VERSION "DIPBNNNYNNNNNNNNNNNNNNNNNNNNNNNNNNNNNNNNNN/4>*%%/4/'%**4NNN///"

NS_ :

BS_:

BU_: Gateway_1 Gateway_0
VAL_TABLE_ SSS_FF38_BtnEvent 3 "Ignore" 2 "No Change/Held" 1 "Pressed" 0 "Released" ;
VAL_TABLE_ SSS_FF39_ControllerFaultStatus 2 "Critical Fault Active" 1 "Caution Fault Active" 0 "No Active Faults" ;
VAL_TABLE_ SSS_FF38_CmdType 1 "Position Cmd" 0 "Button Cmd" ;
VAL_TABLE_ VT_TTA_InstanceSetupMode 3 "Ignore" 2 "Reserved" 1 "MagnetInstancingActive" 0 "PowerOnInstancingActive" ;
VAL_TABLE_ Value_Table_u2_Enable_Disable 3 "Ignore" 2 "Reserved" 1 "Enable" 0 "Disable" ;
VAL_TABLE_ SSS_Act_FaultStatus 3 "Ignore" 2 "Warning" 1 "Caution" 0 "Inactive" ;
VAL_TABLE_ SSS_Act_PosFbk 2047 "No Data" 2046 "Error" 2043 "Not Homed Yet" ;
VAL_TABLE_ SSS_Act_SpeedSetting 4095 "No Change" 4094 "Error" ;
VAL_TABLE_ SSS_Act_FunctionInst 15 "No Data" 14 "Error" 13 "All" ;
VAL_TABLE_ SSS_Act_SourceInst 15 "Not Available" 14 "Error" ;
VAL_TABLE_ SSS_Act_PosCmd 2047 "No Cmd" 2046 "Error" 2043 "Home Cmd" ;
VAL_TABLE_ SSS_Act_MotionCmd 3 "No Cmd" 2 "Move down / Retract / Stbd" 1 "Move up / Extend / Port" 0 "Stop" ;
VAL_TABLE_ SSS_Act_FunctionType 15 "Ignore" 14 "Error" 13 "All" 7 "Smart Act 3" 6 "Smart Act 2" 5 "Smart Act 1" 4 "Surf Actuator" 3 "Trim Tab" 2 "Shallow Water Anchor" 1 "Jack Plate" 0 "Engine Trim" ;
VAL_TABLE_ SSS_Act_SourceType 2 "Trim Dial" 1 "DSC" 0 "MFD" ;
VAL_TABLE_ VT_STA_TabState 5 "Error" 4 "Cycling" 3 "Active" 2 "Ready" 1 "Initting" 0 "Not ready" ;
VAL_TABLE_ CCPCommands 255 "ECU_RESPONCE" 23 "EXCHANGE_ID" 19 "UNLOCK" 18 "GET_SEED" 4 "UPLOAD" 3 "DOWNLOAD" 2 "SET_MTA" 1 "CONNECT" ;
VAL_TABLE_ HelmHardstopType 3 "Ignore" 2 "Electronic and Physical" 1 "Physical" 0 "Electronic" ;
VAL_TABLE_ BatteryStatus 5 "Bad Connection" 4 "High" 3 "Low" 2 "Weak" 1 "Charger Off" 0 "Normal" ;
VAL_TABLE_ Merc_Authentication_Status 1 "Authenticated" 0 "Not Authenticated (default)" ;
VAL_TABLE_ Merc_Trolling_Mode 3 "Not Available (default)" 2 "Error" 1 "Mode on" 0 "Mode off" ;
VAL_TABLE_ Merc_Throttle_Only_Mode 3 "Not Available (default)" 2 "Error" 1 "Mode on" 0 "Mode off" ;
VAL_TABLE_ Merc_Single_Lever_Mode 3 "Not Available (default)" 2 "Error" 1 "Mode on" 0 "Mode off" ;
VAL_TABLE_ AutopiliotMode 4 "Override" 3 "Route" 2 "Track" 1 "Heading" 0 "Standby" ;
VAL_TABLE_ CommandType 1 "Steering" 0 "Rudder" ;
VAL_TABLE_ PCM_eHardstop 2 "Stbd" 1 "Port" 0 "None" ;
VAL_TABLE_ ASK_AckReq 1 "Ack Requested" 0 "No Ack Requested" ;
VAL_TABLE_ JoystickMode 3 "Position and Heading Hold" 2 "Heading Hold" 1 "Position Hold" 0 "Manual" ;
VAL_TABLE_ MCU_Reset_Source 4 "CCP Reset" 3 "Network Reset" 2 "Local Reset" 1 "Stack Overflow" 0 "None" ;
VAL_TABLE_ CPU_Reset_Source 1024 "Software Reset" 512 "Core Lockup" 256 "JTAG Reset" 130 "Power-on" 65 "VLLS with reset Assertion" 64 "External" 32 "Watchdog" 4 "Loss-of-Clock" 2 "Low-voltage Detect" 1 "Low Leakage Wakeup" ;
VAL_TABLE_ ASK_ControlZone 6 "CCW" 5 "CW" 4 "Port" 3 "Reverse" 2 "Starboard" 1 "Forward" 0 "Neutral" ;
VAL_TABLE_ ASK_Mode 3 "Position & Heading" 2 "Heading" 1 "Position" 0 "Off" ;
VAL_TABLE_ VariationSource 63 "Data Not Available" 8 "WMM 2020" 7 "WMM 2015" 6 "WMM 2010" 5 "WMM 2005" 4 "WMM 2000" 3 "Automatic - Calculation" 2 "Automatic - Table" 1 "Automatic - Chart" 0 "Manual Entry" ;
VAL_TABLE_ TFX_OffOn 1 "On" 0 "Off" ;
VAL_TABLE_ TFX_ControlState_EST 0 "Y: Startup, S: Unknown" 15 "Not Available" 14 "Error" 8 "EOL Test" 7 "Power down" 6 "Fault" 5 "Joystick Active" 4 "CH Active" 3 "Y: Inactive, S: Calibration" 2 "Y: SmartSelect, S: Certification" 1 "Y: LPS Cal, S: Startup" ;
VAL_TABLE_ RPMSource 4 "i7700 Tach" 3 "Electronic Engines" 2 "NMEA2000" 1 "PCM Tach" 0 "Unavailable" ;
VAL_TABLE_ TFX_MasterJoystick 3 "Not Available" 2 "Not Available" 1 "Master Joystick" 0 "Non-Master Joystick" ;
VAL_TABLE_ JS_CL_State 2 "Latched" 1 "Enabled" 0 "Disabled" ;
VAL_TABLE_ Default_Ignore_uint4 15 "Ignore" 14 "Default" ;
VAL_TABLE_ TFX_TransferRqstESTGateway 3 "Not Available" 2 "Error" 1 "Transfer to Gateway" 0 "No Request" ;
VAL_TABLE_ Error_NA_int8 127 "Not Available" 126 "Error" ;
VAL_TABLE_ Error_NA_int16 32767 "Not Available" 32766 "Error" ;
VAL_TABLE_ Error_NA_uint4 15 "Not Available" 14 "Error" ;
VAL_TABLE_ Error_NA_uint16 65535 "Not Available" 65534 "Error" ;
VAL_TABLE_ Error_NA_uint8 255 "Not Available" 254 "Error" ;
VAL_TABLE_ TFX_SourceType 1 "Joystick" 0 "Main PCM" ;
VAL_TABLE_ MainSecond 1 "Second" 0 "Main" ;
VAL_TABLE_ EngagedDisengaged 1 "Disengaged" 0 "Engaged" ;
VAL_TABLE_ TFX_ESMFaults 5 "Throttle Up Fault" 4 "Reverse Fault" 3 "Forward Fault" 2 "Neutral Fault" 1 "Danger Fault" 0 "No Fault" ;
VAL_TABLE_ TFX_StartStop 3 "Reserved" 2 "Engine Stop" 1 "Engine Start" 0 "No Change" ;
VAL_TABLE_ TFX_TrimCommand 2 "Trim Down Active" 1 "Trim Up Active" 0 "No Trim Change" ;
VAL_TABLE_ InactiveActive 1 "Active" 0 "Inactive" ;
VAL_TABLE_ Shift_Throttle_type 7 "ETEC-G2" 6 "None (EPS only)" 5 "i7700" 4 "Suzuki" 3 "Yamaha" 2 "Yanmar" 1 "ICON" 0 "i6800" ;
VAL_TABLE_ E_Default_F_Ignore 15 "Ignore" 14 "Default" ;
VAL_TABLE_ BRP_Fault_Code 5 "Throttle Up Fault" 4 "Reverse Fault" 3 "Forward Fault" 2 "Neutral Fault" 1 "Non Recoverable Fault" 0 "No Fault" ;
VAL_TABLE_ TFX_CtrakSourceInstance 15 "Not Available" 14 "Error" ;
VAL_TABLE_ TFX_3Ignore 3 "Ignore" ;
VAL_TABLE_ TFX_3All 3 "All" ;
VAL_TABLE_ TFX_013_OffOnIgnore 1 "On" 0 "Off" 3 "Ignore" ;
VAL_TABLE_ TFX_ErrorFE_NotAvailableFF 255 "Not Available" 254 "Error" ;
VAL_TABLE_ TFX_CANtrakAdjustScreen 3 "Ignore" 1 "Enabled" 0 "Disabled" ;
VAL_TABLE_ TFX_OptimusSystemType 3 "Ignore" 1 "Optimus 360" 0 "Optimus" ;
VAL_TABLE_ TFX_DockingMode 3 "Ignore" 1 "Description for the value '0x1'" 0 "Description for the value '0x0'" ;
VAL_TABLE_ TFX_SyncMode 15 "Ignore" 1 "PTS" 0 "CS" ;
VAL_TABLE_ TFX_OffOnIgnore 3 "Ignore" 1 "On" 0 "Off" ;
VAL_TABLE_ TFX_NeutralGearIgnore 3 "Ignore" 1 "Gear" 0 "Neutral" ;
VAL_TABLE_ TFX_F_Ignore 15 "Ignore" ;
VAL_TABLE_ TFX_LampStatus 1 "On" 0 "Off" ;
VAL_TABLE_ TFX_LimpHomeMode 3 "Reserved Mode" 2 "Mode 2" 1 "Mode 1" 0 "Off" ;
VAL_TABLE_ TFX_KeyOffCylPos 1 "Straighten up if Angled to COG" 0 "Keep Last Position" ;
VAL_TABLE_ TFX_SpeedSource 15 "Ignore" 3 "Throttle Command" 2 "PCM Tachometer" 1 "N2K Engine RPM" 0 "Speed Over Water" ;
VAL_TABLE_ TFX_FFFFIgnore 65535 "Ignore" ;
VAL_TABLE_ TFX_7FIgnore 127 "Ignore" ;
VAL_TABLE_ TFX_FFIgnore 255 "Ignore" ;
VAL_TABLE_ TFX_CANtrak_UserCmd 15 "Ignore" 14 "Error" 3 "Exit Limp Home Mode" 2 "Enter Limp Home Mode" 1 "Resume" 0 "No Command" ;
VAL_TABLE_ TFX_HelmCommand 2 "Reset" 1 "Powerdown" 0 "No Command" ;
VAL_TABLE_ TFX_Helm_Brake_State 8 "Disabled" 7 "Off" 6 "Reapply Brake" 5 "Reverse" 4 "Reduce" 3 "Hold" 2 "Brake" 1 "Steering" 0 "Startup" ;
VAL_TABLE_ TFX_Helm_State 3 "Fault" 2 "Reverse" 1 "Hardover" 0 "Steering" ;
VAL_TABLE_ TFX_TeleflexHeading 1850 "Teleflex" ;
VAL_TABLE_ TFX_TrueFalse 1 "True" 0 "False" ;
VAL_TABLE_ TFX_JoystickInNeutral 3 "Not Available" 2 "Error" 1 "No" 0 "Yes" ;
VAL_TABLE_ TFX_SourceControlType 15 "Not Available" 14 "Error" 1 "Joystick" 0 "Control Head" ;
VAL_TABLE_ TFX_ControlState_Actuator 15 "Not Available" 14 "Error" 5 "Freeze" 4 "Active" 3 "Calibration" 2 "Power Down" 1 "Inactive" ;
VAL_TABLE_ TFX_PrtStbd 2 "Error" 3 "Not Available" 1 "Starboard" 0 "Port" ;
VAL_TABLE_ TFX_NoYes 1 "Yes" 0 "No" ;
VAL_TABLE_ TFX_SidePerformance 3 "Not Available" 2 "Shut Down" 1 "Limited" 0 "Full" ;
VAL_TABLE_ TFX_ControlState_PCM 15 "Not Available" 14 "Error" 8 "Auto-Pilot" 7 "Steering" 6 "Docking" 5 "Freeze" 4 "Purge" 3 "Calibration" 2 "Power Down" 1 "Inactive" ;
VAL_TABLE_ TFX_Fault 1 "Active" 0 "Inactive" ;
VAL_TABLE_ TFX_ActuatorType 1 "Throttle" 0 "Shift" ;
VAL_TABLE_ TFX_GearValue 15 "Not Available" 14 "Error" 2 "Reverse" 1 "Neutral" 0 "Forward" ;

BO_ 3221225472 VECTOR__INDEPENDENT_SIG_MSG: 0 Vector__XXX
 SG_ OilPressure : 0|16@1+ (100,0) [0|0] "Pa" Vector__XXX
 SG_ FaultCode : 0|8@1+ (1,0) [0|0] "" Vector__XXX
 SG_ PeerEMMInstance : 0|8@1+ (1,0) [0|0] "" Vector__XXX
 SG_ SourceESMInstance : 0|3@1+ (1,0) [0|0] "" Vector__XXX
 SG_ TotalNumberOfFramestoTransmitRTS : 0|8@1+ (1,0) [0|255] "" Vector__XXX
 SG_ TotalMessageSizeRTS : 0|16@1+ (1,0) [0|1785] "" Vector__XXX
 SG_ NumberofFramesAllowableforSend : 0|8@1+ (1,0) [0|255] "" Vector__XXX
 SG_ NumberofNextTransmittedFrame : 0|8@1- (1,0) [0|255] "" Vector__XXX
 SG_ TotalMessageSizeModeEOM : 0|16@1+ (1,0) [0|1785] "" Vector__XXX
 SG_ TotalNumberOfFramesReceived : 0|8@1- (1,0) [0|255] "" Vector__XXX
 SG_ TotalMessageSizeModeBAM : 0|16@1+ (1,0) [0|1785] "" Vector__XXX
 SG_ TotalNumberFramesTransmitBAM : 0|8@1- (1,0) [0|255] "" Vector__XXX
 SG_ TFX_ST_MarineIndustryID : 0|3@1+ (1,0) [0|0] "" Vector__XXX
 SG_ SID : 0|8@1+ (1,0) [0|250] "" Vector__XXX
 SG_ TFX_Shift_SyncActive : 0|1@1- (1,0) [0|0] "" Vector__XXX
 SG_ TFX_Shift_Group : 0|3@1+ (1,0) [0|7] "" Vector__XXX
 SG_ TFX_SCM_DockingActive : 0|1@1+ (1,0) [0|0] "" Vector__XXX
 SG_ TFX_SCM_DockingActive : 0|1@1+ (1,0) [0|0] "" Vector__XXX
 SG_ IndustryGroup : 0|3@1+ (1,0) [0|0] "" Vector__XXX
 SG_ TFX_Shift_Throttle : 0|10@1+ (0.1,0) [0|0] "%" Vector__XXX
 SG_ TFX_Shift_TrollBucket : 0|8@1- (1,0) [0|0] "" Vector__XXX
 SG_ TFX_Shift_EngineRpm : 0|14@1- (1,0) [0|0] "" Vector__XXX
 SG_ TFX_Shift_Gear : 0|2@1+ (1,0) [0|0] "" Vector__XXX
 SG_ TFX_Shift_TrollValveEngaged : 0|1@1+ (1,0) [0|0] "" Vector__XXX
 SG_ TFX_Shift_CriticalFailActive : 0|1@1+ (1,0) [0|0] "" Vector__XXX
 SG_ TFX_Shift_WarningActive : 0|1@1- (1,0) [0|0] "" Vector__XXX
 SG_ TFX_Shift_SyncActive : 0|1@1- (1,0) [0|0] "" Vector__XXX
 SG_ TFX_Shift_Group : 0|5@1+ (1,0) [0|0] "" Vector__XXX
 SG_ TFX_Shift_EngineRpm : 0|14@1- (1,0) [0|0] "" Vector__XXX
 SG_ TFX_Shift_TrollValveEngaged : 0|1@1+ (1,0) [0|0] "" Vector__XXX
 SG_ TFX_Shift_CriticalFailActive : 0|1@1+ (1,0) [0|0] "" Vector__XXX
 SG_ TFX_Shift_WarningActive : 0|1@1- (1,0) [0|0] "" Vector__XXX
 SG_ TFX_Shift_Group : 0|5@1+ (1,0) [0|0] "" Vector__XXX
 SG_ TFX_Header : 0|16@1+ (1,0) [0|0] "" Vector__XXX
 SG_ TFX_Shift_Gear : 0|2@1+ (1,0) [0|0] "" Vector__XXX
 SG_ TFX_Shift_TrollValveEngaged : 0|1@1+ (1,0) [0|0] "" Vector__XXX
 SG_ TFX_Shift_CriticalFailActive : 0|1@1+ (1,0) [0|0] "" Vector__XXX
 SG_ TFX_Shift_SyncActive : 0|1@1- (1,0) [0|0] "" Vector__XXX
 SG_ TFX_Shift_Instance : 0|3@1+ (1,0) [0|0] "" Vector__XXX
 SG_ TFX_Shift_TrollBucket : 0|8@1- (1,0) [0|0] "" Vector__XXX
 SG_ TFX_Shift_EngineRpm : 0|14@1- (1,0) [0|0] "" Vector__XXX
 SG_ TFX_Shift_Gear : 0|2@1+ (1,0) [0|0] "" Vector__XXX
 SG_ TFX_Shift_WarningActive : 0|1@1- (1,0) [0|0] "" Vector__XXX
 SG_ TFX_Shift_SyncActive : 0|1@1- (1,0) [0|0] "" Vector__XXX
 SG_ TFX_Shift_Throttle : 0|10@1+ (0.1,0) [0|0] "%" Vector__XXX
 SG_ TFX_Shift_Instance : 0|4@1+ (1,0) [0|15] "" Vector__XXX
 SG_ TFX_Shift_Group : 0|3@1+ (1,0) [0|7] "" Vector__XXX
 SG_ TFX_Header : 0|11@1+ (1,0) [0|2047] "" Vector__XXX
 SG_ TFX_Shift_WarningActive : 0|1@1- (1,0) [0|0] "" Vector__XXX
 SG_ TFX_Shift_TrollValveEngaged : 0|1@1+ (1,0) [0|0] "" Vector__XXX
 SG_ TFX_Shift_TrollBucket : 0|8@1- (1,0) [0|0] "" Vector__XXX
 SG_ TFX_Shift_Throttle : 0|10@1+ (0.1,0) [0|0] "%" Vector__XXX
 SG_ TFX_Shift_SyncActive : 0|1@1- (1,0) [0|0] "" Vector__XXX
 SG_ TFX_Shift_Instance : 0|3@1+ (1,0) [0|0] "" Vector__XXX
 SG_ TFX_Shift_Group : 0|5@1+ (1,0) [0|0] "" Vector__XXX
 SG_ TFX_Shift_Gear : 0|2@1+ (1,0) [0|0] "" Vector__XXX
 SG_ TFX_Shift_EngineRpm : 0|14@1- (1,0) [0|0] "" Vector__XXX
 SG_ TFX_Shift_CriticalFailActive : 0|1@1+ (1,0) [0|0] "" Vector__XXX
 SG_ TFX_Header : 0|16@1+ (1,0) [0|0] "" Vector__XXX
 SG_ TFX_Shift_WarningActive : 0|1@1- (1,0) [0|0] "" Vector__XXX
 SG_ TFX_Shift_TrollValveEngaged : 0|1@1+ (1,0) [0|0] "" Vector__XXX
 SG_ TFX_Shift_TrollBucket : 0|8@1- (1,0) [0|0] "" Vector__XXX
 SG_ TFX_Shift_Throttle : 0|10@1+ (0.1,0) [0|0] "%" Vector__XXX
 SG_ TFX_Shift_SyncActive : 0|1@1- (1,0) [0|0] "" Vector__XXX
 SG_ TFX_Shift_Instance : 0|3@1+ (1,0) [0|0] "" Vector__XXX
 SG_ TFX_Shift_Group : 0|5@1+ (1,0) [0|0] "" Vector__XXX
 SG_ TFX_Shift_Gear : 0|2@1+ (1,0) [0|0] "" Vector__XXX
 SG_ TFX_Shift_EngineRpm : 0|14@1- (1,0) [0|0] "" Vector__XXX
 SG_ TFX_Shift_CriticalFailActive : 0|1@1+ (1,0) [0|0] "" Vector__XXX
 SG_ TFX_Header : 0|16@1+ (1,0) [0|0] "" Vector__XXX
 SG_ TFX_Shift_WarningActive : 0|1@1- (1,0) [0|0] "" Vector__XXX
 SG_ TFX_Shift_TrollValveEngaged : 0|1@1+ (1,0) [0|0] "" Vector__XXX
 SG_ TFX_Shift_TrollBucket : 0|8@1- (1,0) [0|0] "" Vector__XXX
 SG_ TFX_Shift_Throttle : 0|10@1+ (0.1,0) [0|0] "%" Vector__XXX
 SG_ TFX_Shift_SyncActive : 0|1@1- (1,0) [0|0] "" Vector__XXX
 SG_ TFX_Shift_Instance : 0|3@1+ (1,0) [0|0] "" Vector__XXX
 SG_ TFX_Shift_Group : 0|5@1+ (1,0) [0|0] "" Vector__XXX
 SG_ TFX_Shift_Gear : 0|2@1+ (1,0) [0|0] "" Vector__XXX
 SG_ TFX_Shift_EngineRpm : 0|14@1- (1,0) [0|0] "" Vector__XXX
 SG_ TFX_Shift_CriticalFailActive : 0|1@1+ (1,0) [0|0] "" Vector__XXX
 SG_ Override : 0|8@1+ (1,0) [0|0] "" Vector__XXX
 SG_ TFX_PCM_PortSetpointDelta : 0|16@1- (0.01,0) [0|0] "°" Vector__XXX
 SG_ TFX_PCM_PortPTerm : 0|16@1- (0.01,0) [0|0] "" Vector__XXX
 SG_ TFX_PCM_PortPositionError : 0|16@1- (0.01,0) [0|0] "°" Vector__XXX
 SG_ TFX_PCM_PortFfTerm : 0|16@1- (0.1,0) [0|0] "" Vector__XXX
 SG_ TFX_SourceInstance : 0|4@1+ (1,0) [0|0] "" Vector__XXX
 SG_ TFX_IndustryGroup : 0|3@1+ (1,0) [0|0] "" Vector__XXX
 SG_ TFX_Header : 0|11@1+ (1,0) [0|0] "" Vector__XXX
 SG_ TFX_IndustryGroup : 0|3@1+ (1,0) [0|0] "" Vector__XXX
 SG_ TFX_Header : 0|11@1+ (1,0) [0|0] "" Vector__XXX
 SG_ TFX_Helm_Fault_SingleSensor : 0|1@1+ (1,0) [0|0] "" Vector__XXX
 SG_ TFX_Helm_Fault_SensorMismatch : 0|1@1+ (1,0) [0|0] "" Vector__XXX
 SG_ TFX_Helm_Fault_PcmHeartbeat : 0|1@1+ (1,0) [0|0] "" Vector__XXX
 SG_ TFX_Helm_Fault_FtCanWiring : 0|1@1+ (1,0) [0|0] "" Vector__XXX
 SG_ TFX_Helm_Fault_Brake_OverCurrent : 0|1@1+ (1,0) [0|0] "" Vector__XXX
 SG_ TFX_Helm_Fault_Brake_OpenCircuit : 0|1@1+ (1,0) [0|0] "" Vector__XXX
 SG_ TFX_Helm_Fault_BothSensors : 0|1@1+ (1,0) [0|0] "" Vector__XXX
 SG_ TFX_VC_JoystickAngle : 0|16@1- (0.01,0) [-180|180] "deg" Vector__XXX
 SG_ TFX_VC_JoystickTAxisPos : 0|16@1- (0.01,0) [-100|100] "%" Vector__XXX
 SG_ TFX_VC_JoystickYAxisPos : 0|16@1- (0.01,0) [-100|100] "%" Vector__XXX
 SG_ TFX_VC_JoystickXAxisPos : 0|16@1- (0.01,0) [-100|100] "%" Vector__XXX
 SG_ TFX_VC_Thrust_Stbd : 0|16@1+ (0.01,0) [0|100] "%" Vector__XXX
 SG_ TFX_VC_Thrust_Port : 0|16@1+ (0.01,0) [0|100] "%" Vector__XXX
 SG_ TFX_VC_State : 0|8@1+ (1,0) [0|0] "" Vector__XXX
 SG_ TFX_VC_ControlState : 0|8@1+ (1,0) [0|0] "" Vector__XXX
 SG_ TFX_JoystickHrtBtLoss_1 : 0|1@1+ (1,0) [0|0] "" Vector__XXX
 SG_ TFX_JoystickHrtBtLoss_0 : 0|1@1+ (1,0) [0|0] "" Vector__XXX
 SG_ TFX_HelmSensorFault : 0|1@1+ (1,0) [0|0] "" Vector__XXX
 SG_ TFX_HelmPCM_HrtBtLoss : 0|1@1+ (1,0) [0|0] "" Vector__XXX
 SG_ TFX_HelmHrtBtLoss_1 : 0|1@1+ (1,0) [0|0] "" Vector__XXX
 SG_ TFX_HelmHrtBtLoss_0 : 0|1@1+ (1,0) [0|0] "" Vector__XXX
 SG_ TFX_HelmFTCANwiringProblem : 0|1@1+ (1,0) [0|0] "" Vector__XXX
 SG_ TFX_HelmBrakeFault : 0|1@1+ (1,0) [0|0] "" Vector__XXX
 SG_ TFX_StbdTempSensorFault : 0|1@1+ (1,0) [0|0] "" Vector__XXX
 SG_ TFX_StbdOverTempFault : 0|1@1+ (1,0) [0|0] "" Vector__XXX
 SG_ TFX_StbdMotorFault : 0|1@1+ (1,0) [0|0] "" Vector__XXX
 SG_ TFX_StbdElectronicFault : 0|1@1+ (1,0) [0|0] "" Vector__XXX
 SG_ TFX_StbdCylWrongDirection : 0|1@1+ (1,0) [0|0] "" Vector__XXX
 SG_ TFX_StbdCylUnintendedMove : 0|1@1+ (1,0) [0|0] "" Vector__XXX
 SG_ TFX_StbdCylSensorNotCalibrated : 0|1@1+ (1,0) [0|0] "" Vector__XXX
 SG_ TFX_StbdCylSensorFault : 0|1@1+ (1,0) [0|0] "" Vector__XXX
 SG_ TFX_StbdCylDidNotMove : 0|1@1+ (1,0) [0|0] "" Vector__XXX
 SG_ TFX_StbdBatVoltageFault : 0|1@1+ (1,0) [0|0] "" Vector__XXX
 SG_ TFX_PortCylWrongDirection : 0|1@1+ (1,0) [0|0] "" Vector__XXX
 SG_ TFX_PortCylSensorNotCalibrated : 0|1@1+ (1,0) [0|0] "" Vector__XXX
 SG_ TFX_PortCylSensorFault : 0|1@1+ (1,0) [0|0] "" Vector__XXX
 SG_ TFX_StbdSideVoltageSource : 0|1@1+ (1,0) [0|0] "" Vector__XXX
 SG_ TFX_StbdSidePerformance : 0|2@1+ (1,0) [0|0] "" Vector__XXX
 SG_ TFX_PortSideVoltageSource : 0|1@1+ (1,0) [0|0] "" Vector__XXX
 SG_ TFX_PortSidePerformance : 0|2@1+ (1,0) [0|0] "" Vector__XXX
 SG_ TFX_PortTempSensorFault : 0|1@1+ (1,0) [0|0] "" Vector__XXX
 SG_ TFX_PortOverTempFault : 0|1@1+ (1,0) [0|0] "" Vector__XXX
 SG_ TFX_PortMotorFault : 0|1@1+ (1,0) [0|0] "" Vector__XXX
 SG_ TFX_PortElectronicFault : 0|1@1+ (1,0) [0|0] "" Vector__XXX
 SG_ TFX_PortCylUnintendedMove : 0|1@1+ (1,0) [0|0] "" Vector__XXX
 SG_ TFX_PortCylDidNotMove : 0|1@1+ (1,0) [0|0] "" Vector__XXX
 SG_ TFX_PortBatVoltageFault : 0|1@1+ (1,0) [0|0] "" Vector__XXX
 SG_ TFX_StbdSidePerformance : 0|1@1+ (1,0) [0|0] "" Vector__XXX
 SG_ TFX_ThrActHrtBtLoss_2 : 0|1@1+ (1,0) [0|0] "" Vector__XXX
 SG_ TFX_ThrActHrtBtLoss_1 : 0|1@1+ (1,0) [0|0] "" Vector__XXX
 SG_ TFX_ThrActHrtBtLoss_0 : 0|1@1+ (1,0) [0|0] "" Vector__XXX
 SG_ TFX_ShftActHrtBtLoss_2 : 0|1@1+ (1,0) [0|0] "" Vector__XXX
 SG_ TFX_ShftActHrtBtLoss_1 : 0|1@1+ (1,0) [0|0] "" Vector__XXX
 SG_ TFX_ShftActHrtBtLoss_0 : 0|1@1+ (1,0) [0|0] "" Vector__XXX
 SG_ TFX_PCM_HrtBtLoss_1 : 0|1@1+ (1,0) [0|0] "" Vector__XXX
 SG_ TFX_PCM_HrtBtLoss_0 : 0|1@1+ (1,0) [0|0] "" Vector__XXX
 SG_ TFX_JoystickYaxisPotFault : 0|1@1+ (1,0) [0|0] "" Vector__XXX
 SG_ TFX_JoystickXaxisPotFault : 0|1@1+ (1,0) [0|0] "" Vector__XXX
 SG_ TFX_JoystickThetaAxisPotFault : 0|1@1+ (1,0) [0|0] "" Vector__XXX
 SG_ TFX_ThrActHrtBtLoss_3 : 0|1@1+ (1,0) [0|0] "" Vector__XXX
 SG_ TFX_ThrActHrtBtLoss_2 : 0|1@1+ (1,0) [0|0] "" Vector__XXX
 SG_ TFX_ThrActHrtBtLoss_1 : 0|1@1+ (1,0) [0|0] "" Vector__XXX
 SG_ TFX_ThrActHrtBtLoss_0 : 0|1@1+ (1,0) [0|0] "" Vector__XXX
 SG_ TFX_StbdLeverFault : 0|1@1+ (1,0) [0|0] "" Vector__XXX
 SG_ TFX_ShftActHrtBtLoss_3 : 0|1@1+ (1,0) [0|0] "" Vector__XXX
 SG_ TFX_ShftActHrtBtLoss_2 : 0|1@1+ (1,0) [0|0] "" Vector__XXX
 SG_ TFX_ShftActHrtBtLoss_1 : 0|1@1+ (1,0) [0|0] "" Vector__XXX
 SG_ TFX_ShftActHrtBtLoss_0 : 0|1@1+ (1,0) [0|0] "" Vector__XXX
 SG_ TFX_PortLeverFault : 0|1@1+ (1,0) [0|0] "" Vector__XXX
 SG_ TFX_WarningFault : 0|1@1+ (1,0) [0|0] "" Vector__XXX
 SG_ TFX_ThrUpMotionFault : 0|1@1+ (1,0) [0|0] "" Vector__XXX
 SG_ TFX_ThrDwnMotionFault : 0|1@1+ (1,0) [0|0] "" Vector__XXX
 SG_ TFX_ShiftRevMotionFault : 0|1@1+ (1,0) [0|0] "" Vector__XXX
 SG_ TFX_ShiftNeutMotionFault : 0|1@1+ (1,0) [0|0] "" Vector__XXX
 SG_ TFX_ShiftFwdMotionFault : 0|1@1+ (1,0) [0|0] "" Vector__XXX
 SG_ TFX_CriticalFault : 0|1@1+ (1,0) [0|0] "" Vector__XXX
 SG_ TFX_ActuatorType : 0|1@1+ (1,0) [0|0] "" Vector__XXX
 SG_ TFX_ActualTrollingValveValue : 0|8@1+ (1,0) [0|100] "%" Vector__XXX
 SG_ TFX_ActualThrottleValue : 0|16@1+ (0.1,0) [0|100] "%" Vector__XXX
 SG_ TFX_ActualGearValue : 0|4@1- (1,0) [0|0] "" Vector__XXX
 SG_ TFX_SourceInstance : 0|4@1+ (1,0) [0|0] "" Vector__XXX
 SG_ TFX_IndustryGroup : 0|3@1+ (1,0) [0|0] "" Vector__XXX
 SG_ TFX_Header : 0|11@1+ (1,0) [0|2047] "" Vector__XXX
 SG_ TFX_ThrUpMotionFault : 0|1@1+ (1,0) [0|0] "" Vector__XXX
 SG_ TFX_ThrDwnMotionFault : 0|1@1+ (1,0) [0|0] "" Vector__XXX
 SG_ TFX_ShiftRevMotionFault : 0|1@1+ (1,0) [0|0] "" Vector__XXX
 SG_ TFX_ShiftNeutMotionFault : 0|1@1+ (1,0) [0|0] "" Vector__XXX
 SG_ TFX_ShiftFwdMotionFault : 0|1@1+ (1,0) [0|0] "" Vector__XXX
 SG_ TFX_CriticalFault : 0|1@1+ (1,0) [0|0] "" Vector__XXX
 SG_ TFX_ActuatorType : 0|1@1+ (1,0) [0|0] "" Vector__XXX
 SG_ TFX_ActualTrollingValveValue : 0|8@1+ (1,0) [0|100] "%" Vector__XXX
 SG_ TFX_ActualThrottleValue : 0|16@1+ (0.1,0) [0|100] "%" Vector__XXX
 SG_ TFX_ActualGearValue : 0|4@1- (1,0) [0|0] "" Vector__XXX
 SG_ TFX_SourceInstance : 0|4@1+ (1,0) [0|0] "" Vector__XXX
 SG_ TFX_Header : 0|11@1+ (1,0) [0|2047] "" Vector__XXX
 SG_ TFX_DockingMode : 0|2@1+ (1,0) [0|3] "" Vector__XXX
 SG_ TFX_StationProtect : 0|2@1+ (1,0) [0|3] "" Vector__XXX
 SG_ TFX_SplitRange : 0|16@1+ (1,0) [5|75] "" Vector__XXX
 SG_ TFX_LeadLever : 0|2@1+ (1,0) [0|3] "" Vector__XXX
 SG_ TFX_FailureToSomething : 0|2@1+ (1,0) [0|3] "" Vector__XXX
 SG_ TFX_FilterThr_Stbd : 0|16@1+ (0.1,0) [0|100] "%" Vector__XXX
 SG_ TFX_FilterThr_Port : 0|16@1+ (0.1,0) [0|100] "%" Vector__XXX
 SG_ TFX_IndustryGroup : 0|3@1+ (1,0) [0|0] "" Vector__XXX
 SG_ TFX_Header : 0|11@1+ (1,0) [0|2047] "" Vector__XXX
 SG_ TFX_DestinationAddress : 0|8@1+ (1,0) [0|0] "" Vector__XXX
 SG_ TFX_DestinationAddress : 0|8@1+ (1,0) [0|0] "" Vector__XXX
 SG_ TFX_DestinationAddress : 0|8@1+ (1,0) [0|0] "" Vector__XXX
 SG_ TFX_Shift_WarningActive : 0|1@1- (1,0) [0|0] "" Vector__XXX
 SG_ TFX_Shift_TrollValveEngaged : 0|1@1+ (1,0) [0|0] "" Vector__XXX
 SG_ TFX_Shift_TrollBucket : 0|8@1- (1,0) [0|0] "" Vector__XXX
 SG_ TFX_Shift_Throttle : 0|10@1+ (0.1,0) [0|0] "%" Vector__XXX
 SG_ TFX_Shift_SyncActive : 0|1@1- (1,0) [0|0] "" Vector__XXX
 SG_ TFX_Shift_Instance : 0|3@1+ (1,0) [0|0] "" Vector__XXX
 SG_ TFX_Shift_Group : 0|5@1+ (1,0) [0|0] "" Vector__XXX
 SG_ TFX_Shift_Gear : 0|2@1+ (1,0) [0|0] "" Vector__XXX
 SG_ TFX_Shift_EngineRpm : 0|14@1- (1,0) [0|0] "" Vector__XXX
 SG_ TFX_Shift_CriticalFailActive : 0|1@1+ (1,0) [0|0] "" Vector__XXX
 SG_ TFX_Header : 0|16@1+ (1,0) [0|0] "" Vector__XXX
 SG_ TFX_Shift_WarningActive : 0|1@1- (1,0) [0|0] "" Vector__XXX
 SG_ TFX_Shift_TrollValveEngaged : 0|1@1+ (1,0) [0|0] "" Vector__XXX
 SG_ TFX_Shift_TrollBucket : 0|8@1- (1,0) [0|0] "" Vector__XXX
 SG_ TFX_Shift_Throttle : 0|10@1+ (0.1,0) [0|0] "%" Vector__XXX
 SG_ TFX_Shift_SyncActive : 0|1@1- (1,0) [0|0] "" Vector__XXX
 SG_ TFX_Shift_Instance : 0|3@1+ (1,0) [0|0] "" Vector__XXX
 SG_ TFX_Shift_Group : 0|5@1+ (1,0) [0|0] "" Vector__XXX
 SG_ TFX_Shift_Gear : 0|2@1+ (1,0) [0|0] "" Vector__XXX
 SG_ TFX_Shift_EngineRpm : 0|14@1- (1,0) [0|0] "" Vector__XXX
 SG_ TFX_Shift_CriticalFailActive : 0|1@1+ (1,0) [0|0] "" Vector__XXX
 SG_ TFX_Header : 0|16@1+ (1,0) [0|0] "" Vector__XXX
 SG_ TFX_Shift_WarningActive : 0|1@1- (1,0) [0|0] "" Vector__XXX
 SG_ TFX_Shift_TrollValveEngaged : 0|1@1+ (1,0) [0|0] "" Vector__XXX
 SG_ TFX_Shift_TrollBucket : 0|8@1- (1,0) [0|0] "" Vector__XXX
 SG_ TFX_Shift_Throttle : 0|10@1+ (0.1,0) [0|0] "%" Vector__XXX
 SG_ TFX_Shift_SyncActive : 0|1@1- (1,0) [0|0] "" Vector__XXX
 SG_ TFX_Shift_Instance : 0|3@1+ (1,0) [0|0] "" Vector__XXX
 SG_ TFX_Shift_Group : 0|5@1+ (1,0) [0|0] "" Vector__XXX
 SG_ TFX_Shift_Gear : 0|2@1+ (1,0) [0|0] "" Vector__XXX
 SG_ TFX_Shift_EngineRpm : 0|14@1- (1,0) [0|0] "" Vector__XXX
 SG_ TFX_Shift_CriticalFailActive : 0|1@1+ (1,0) [0|0] "" Vector__XXX
 SG_ TFX_Header : 0|16@1+ (1,0) [0|0] "" Vector__XXX
 SG_ TFX_Shift_WarningActive : 0|1@1- (1,0) [0|0] "" Vector__XXX
 SG_ TFX_Shift_TrollValveEngaged : 0|1@1+ (1,0) [0|0] "" Vector__XXX
 SG_ TFX_Shift_TrollBucket : 0|8@1- (1,0) [0|0] "" Vector__XXX
 SG_ TFX_Shift_Throttle : 0|10@1+ (0.1,0) [0|0] "%" Vector__XXX
 SG_ TFX_Shift_SyncActive : 0|1@1- (1,0) [0|0] "" Vector__XXX
 SG_ TFX_Shift_Instance : 0|3@1+ (1,0) [0|0] "" Vector__XXX
 SG_ TFX_Shift_Group : 0|5@1+ (1,0) [0|0] "" Vector__XXX
 SG_ TFX_Shift_Gear : 0|2@1+ (1,0) [0|0] "" Vector__XXX
 SG_ TFX_Shift_EngineRpm : 0|14@1- (1,0) [0|0] "" Vector__XXX
 SG_ TFX_Shift_CriticalFailActive : 0|1@1+ (1,0) [0|0] "" Vector__XXX
 SG_ TFX_Header : 0|16@1+ (1,0) [0|0] "" Vector__XXX
 SG_ TFX_VC_JoystickAngle : 0|16@1- (0.01,0) [-180|180] "deg" Vector__XXX
 SG_ LPS_Sender_SCtr_2 : 0|16@1+ (0.001220703125,0) [0|0] "V" Vector__XXX
 SG_ LPS_Sender_PCtr_2 : 0|16@1+ (0.001220703125,0) [0|0] "V" Vector__XXX
 SG_ TFX_SteeringResistance : 0|12@1- (0.1,0) [0|0] "" Vector__XXX
 SG_ TFX_StarboardAngleToBrake : 0|16@1- (0.1,0) [0|0] "" Vector__XXX
 SG_ TFX_PortAngleToBrake : 0|16@1- (0.1,0) [0|0] "" Vector__XXX
 SG_ TFX_SCU_SourceInstance : 0|4@1+ (1,0) [0|0] "" Vector__XXX
 SG_ TFX_Integrity_Counter : 0|8@1+ (1,0) [0|0] "" Vector__XXX
 SG_ TFX_Helm_WarningFault : 0|1@1+ (1,0) [0|0] "" Vector__XXX
 SG_ TFX_Helm_DangerFault : 0|1@1+ (1,0) [0|0] "" Vector__XXX
 SG_ TFX_Helm_EstimatedPosition : 0|16@1- (0.1,0) [0|0] "°" Vector__XXX
 SG_ TFX_Helm_SteeringMovement : 0|16@1- (0.01,0) [0|0] "°" Vector__XXX
 SG_ TFX_Helm_SourceInstance : 0|4@1+ (1,0) [0|0] "" Vector__XXX
 SG_ TFX_Integrity_Counter : 0|8@1+ (1,0) [0|0] "" Vector__XXX
 SG_ TFX_PCM_StbdPerformanceLimit : 0|8@1+ (1,0) [0|0] "%" Vector__XXX
 SG_ TFX_PCM_StbdHBridgeSource : 0|8@1+ (1,0) [0|0] "" Vector__XXX
 SG_ TFX_PCM_StbdBatteryVoltage : 0|16@1+ (0.001,0) [0|0] "V" Vector__XXX
 SG_ TFX_PCM_PortPerformanceLimit : 0|8@1+ (1,0) [0|0] "%" Vector__XXX
 SG_ TFX_PCM_PortHBridgeSource : 0|8@1+ (1,0) [0|0] "" Vector__XXX
 SG_ TFX_PCM_PortBatteryVoltage : 0|16@1+ (0.001,0) [0|0] "V" Vector__XXX
 SG_ TFX_RateOfTurn : 0|16@1- (0.011,0) [-360.448|360.437] "deg/sec" Vector__XXX
 SG_ TFX_Angle : 0|16@1- (0.005493,0) [-180|180] "deg" Vector__XXX
 SG_ Power_PowerdownTimer : 0|16@0+ (1,0) [0|0] "" Vector__XXX
 SG_ Power_ForceResetTimer : 0|8@0+ (1,0) [0|0] "" Vector__XXX
 SG_ EngineSpeed : 0|16@1+ (0.25,0) [0|16383] "RPM" Vector__XXX
 SG_ Heading : 0|16@1+ (0.0001,0) [0|6.2831] "rad" Vector__XXX
 SG_ PCM_WrgDir_Time : 0|8@1+ (100,0) [0|1000] "ms" Vector__XXX
 SG_ TFX_SourceType : 0|4@1+ (1,0) [0|0] "" Vector__XXX
 SG_ TFX_SourceType : 0|4@1+ (1,0) [0|0] "" Vector__XXX
 SG_ Autopilot_Diag3_LongN : 0|32@1- (1E-007,0) [0|0] "°" Vector__XXX
 SG_ Autopilot_Diag3_LatiN : 0|32@1- (1E-007,0) [0|0] "°" Vector__XXX
 SG_ Autopilot_Diag4_PosY_0 : 0|32@1- (0.01,0) [0|0] "m" Vector__XXX
 SG_ Autopilot_Diag4_PosX_0 : 0|32@1- (0.01,0) [0|0] "m" Vector__XXX
 SG_ Autopilot_Diag2_Long0 : 0|32@1- (1E-007,0) [0|0] "°" Vector__XXX
 SG_ Autopilot_Diag2_Lati0 : 0|32@1- (1E-007,0) [0|0] "°" Vector__XXX
 SG_ Autopilot_Diag1_XTE : 0|32@1- (0.01,0) [0|0] "m" Vector__XXX
 SG_ LPS_DAC_Stbd_2 : 0|16@1+ (0.001220703125,0) [0|0] "V" Vector__XXX
 SG_ LPS_DAC_Stbd_1 : 0|16@1+ (0.001220703125,0) [0|0] "V" Vector__XXX
 SG_ LPS_DAC_Port_2 : 0|16@1+ (0.001220703125,0) [0|0] "V" Vector__XXX
 SG_ LPS_DAC_Port_1 : 0|16@1+ (0.001220703125,0) [0|0] "V" Vector__XXX
 SG_ RPM_Stbd : 0|16@1+ (0.25,0) [0|16383] "RPM" Vector__XXX
 SG_ RPM_Port : 0|16@1+ (0.25,0) [0|16383] "RPM" Vector__XXX
 SG_ LPS_Input_Stbd_3 : 0|16@1+ (0.001220703125,0) [0|0] "V" Vector__XXX
 SG_ LPS_Input_Stbd_2 : 0|16@1+ (0.001220703125,0) [0|0] "V" Vector__XXX
 SG_ LPS_Input_Stbd_1 : 0|16@1+ (0.001220703125,0) [0|0] "V" Vector__XXX
 SG_ LPS_Input_Port_3 : 0|16@1+ (0.001220703125,0) [0|0] "V" Vector__XXX
 SG_ LPS_Input_Port_2 : 0|16@1+ (0.001220703125,0) [0|0] "V" Vector__XXX
 SG_ LPS_Input_Port_1 : 0|16@1+ (0.001220703125,0) [0|0] "V" Vector__XXX
 SG_ XTE_Limit : 0|16@1+ (1,0) [0|0] "m" Vector__XXX
 SG_ NumOfWPsInRoute : 0|16@1+ (1,0) [0|0] "" Vector__XXX
 SG_ SourceInstance : 0|4@1+ (1,0) [0|15] "" Vector__XXX
 SG_ IndustryGroup : 0|3@1+ (1,0) [0|0] "" Vector__XXX
 SG_ ManufacturerCode : 0|11@1+ (1,0) [0|0] "" Vector__XXX
 SG_ IndustryGroup : 0|3@1+ (1,0) [0|0] "" Vector__XXX
 SG_ ManufacturerCode : 0|11@1+ (1,0) [0|0] "" Vector__XXX
 SG_ TFX_Header : 0|11@1+ (1,0) [0|0] "" Vector__XXX
 SG_ ETEC_G2_Fault : 0|1@1+ (1,0) [0|0] "" Vector__XXX
 SG_ ETEC_G2_Gear : 0|2@1+ (1,0) [0|0] "" Vector__XXX
 SG_ EMM_Instance : 0|3@1+ (1,0) [0|0] "" Vector__XXX
 SG_ IndustryGroup : 0|3@1+ (1,0) [0|0] "" Vector__XXX
 SG_ ManufacturerCode : 0|11@1+ (1,0) [0|0] "" Vector__XXX
 SG_ ESM_Instance : 0|3@1+ (1,0) [0|0] "" Vector__XXX
 SG_ TFX_IndustryGroup : 0|3@1+ (1,0) [0|0] "" Vector__XXX
 SG_ ManufacturerCode : 0|11@1+ (1,0) [0|0] "" Vector__XXX
 SG_ ESM_Instance : 0|3@1+ (1,0) [0|0] "" Vector__XXX
 SG_ TFX_IndustryGroup : 0|3@1+ (1,0) [0|0] "" Vector__XXX
 SG_ ManufacturerCode : 0|11@1+ (1,0) [0|0] "" Vector__XXX
 SG_ ESM_Instance : 0|3@1+ (1,0) [0|0] "" Vector__XXX
 SG_ TFX_IndustryGroup : 0|3@1+ (1,0) [0|0] "" Vector__XXX
 SG_ ManufacturerCode : 0|11@1+ (1,0) [0|0] "" Vector__XXX
 SG_ ESM_Instance : 0|3@1+ (1,0) [0|0] "" Vector__XXX
 SG_ TFX_IndustryGroup : 0|3@1+ (1,0) [0|0] "" Vector__XXX
 SG_ ManufacturerCode : 0|11@1+ (1,0) [0|0] "" Vector__XXX
 SG_ TFX_IndustryGroup : 0|3@1+ (1,0) [0|0] "" Vector__XXX
 SG_ ManufacturerCode : 0|11@1+ (1,0) [0|0] "" Vector__XXX
 SG_ TFX_IndustryGroup : 0|3@1+ (1,0) [0|0] "" Vector__XXX
 SG_ ManufacturerCode : 0|11@1+ (1,0) [0|0] "" Vector__XXX
 SG_ ESM_Instance : 0|3@1+ (1,0) [0|0] "" Vector__XXX
 SG_ TFX_IndustryGroup : 0|3@1+ (1,0) [0|0] "" Vector__XXX
 SG_ ManufacturerCode : 0|11@1+ (1,0) [0|0] "" Vector__XXX
 SG_ GearCommand : 0|2@1+ (1,0) [0|0] "" Vector__XXX
 SG_ LimpHomeCommand : 0|1@1+ (1,0) [0|1] "" Vector__XXX
 SG_ NTLStartProtection : 0|1@1+ (1,0) [0|1] "" Vector__XXX
 SG_ StartStopCommand : 0|2@1+ (1,0) [0|3] "" Vector__XXX
 SG_ TrimCommand : 0|8@1+ (1,0) [0|255] "" Vector__XXX
 SG_ TFX_ThrottleCommand : 0|16@1+ (0.1,0) [0|100] "%" Vector__XXX
 SG_ Synchronizing : 0|1@1+ (1,0) [0|1] "" Vector__XXX
 SG_ DestinationESMinstance : 0|3@1+ (1,0) [0|7] "" Vector__XXX
 SG_ MessageGroup : 0|5@1+ (1,0) [0|31] "" Vector__XXX
 SG_ TFX_IndustryGroup : 0|3@1+ (1,0) [0|0] "" Vector__XXX
 SG_ TFX_Header : 0|11@1+ (1,0) [0|2047] "" Vector__XXX
 SG_ TFX_Header : 0|11@1+ (1,0) [0|2047] "" Vector__XXX
 SG_ IndustryGroup : 0|3@1+ (1,0) [0|0] "" Vector__XXX
 SG_ TFX_Header : 0|11@1+ (1,0) [0|0] "" Vector__XXX
 SG_ TFX_IndustryGroup : 0|3@1+ (1,0) [0|0] "" Vector__XXX
 SG_ TFX_ST_StbdThrottleCmd : 0|8@1+ (1,0) [0|0] "%" Vector__XXX
 SG_ TFX_ST_StbdShiftCmd : 0|8@1+ (1,0) [0|0] "" Vector__XXX
 SG_ TFX_ST_PortThrottleCmd : 0|8@1+ (1,0) [0|0] "%" Vector__XXX
 SG_ TFX_ST_PortShiftCmd : 0|8@1+ (1,0) [0|0] "" Vector__XXX
 SG_ TFX_ST_Group : 0|5@1+ (1,0) [0|0] "" Vector__XXX
 SG_ TFX_ST_DestSourceAddr : 0|8@1+ (1,0) [0|0] "" Vector__XXX
 SG_ TFX_ST_ControlType : 0|3@1+ (1,0) [0|0] "" Vector__XXX
 SG_ TFX_ST_Header : 0|16@1+ (1,0) [0|0] "" Vector__XXX
 SG_ TFX_PCM_StbdRudderFbk : 0|16@1- (0.01,0) [-30|30] "deg" Vector__XXX
 SG_ TFX_FilterThr_Stbd : 0|16@1+ (0.1,0) [0|100] "%" Vector__XXX
 SG_ TFX_FilterThr_Port : 0|16@1+ (0.1,0) [0|100] "%" Vector__XXX
 SG_ TFX_FilterRPM_Stbd : 0|16@1+ (0.25,0) [0|6000] "RPM" Vector__XXX
 SG_ TFX_FilterRPM_Port : 0|16@1+ (0.25,0) [0|6000] "RPM" Vector__XXX
 SG_ SSS_FFF2_Break_Voltage : 0|16@1+ (0.001,0) [0|0] "" Vector__XXX
 SG_ Reserved_1Bit_0 : 0|1@1+ (1,0) [0|0] "" Vector__XXX
 SG_ Reserved_1Byte_0s : 0|8@1+ (1,0) [0|0] "" Vector__XXX
 SG_ Reserved2_2Bits_3 : 0|2@1+ (1,0) [3|3] "" Vector__XXX
 SG_ Reserved_1Word_0xFFFF : 0|16@1+ (1,0) [65535|65535] "" Vector__XXX
 SG_ TFX_SteeringDerated : 0|1@1+ (1,0) [0|0] "" Vector__XXX
 SG_ TFX_SteeringOverride : 0|1@1+ (1,0) [0|0] "" Vector__XXX
 SG_ TFX_StbdRPMFbk_PCM : 0|16@1+ (0.25,0) [0|6000] "RPM" Vector__XXX
 SG_ TFX_PrtRPMFbk_PCM : 0|16@1+ (0.25,0) [0|6000] "RPM" Vector__XXX
 SG_ TFX_StbdRPMFbk_N2K : 0|16@1+ (0.25,0) [0|6000] "RPM" Vector__XXX
 SG_ TFX_PrtRPMFbk_N2K : 0|16@1+ (0.25,0) [0|6000] "RPM" Vector__XXX
 SG_ Reserved_2Bits_3 : 0|2@1+ (1,0) [3|3] "" Vector__XXX
 SG_ Reserved_2Bits_3 : 0|2@1+ (1,0) [3|3] "" Vector__XXX
 SG_ Reserved_1Word_0xFFFF : 0|16@1+ (1,0) [65535|65535] "" Vector__XXX
 SG_ Reserved_1Bit_0 : 0|1@1+ (1,0) [0|0] "" Vector__XXX
 SG_ DestinationTabInstance : 0|4@1+ (1,0) [0|15] "" Vector__XXX
 SG_ u16Percent_3 : 0|16@0+ (0.01,0) [0|125] "" Vector__XXX
 SG_ u16Percent_2 : 0|16@0+ (0.01,0) [0|125] "" Vector__XXX
 SG_ u16Percent_1 : 0|16@0+ (0.01,0) [0|125] "" Vector__XXX

BO_ 2680225749 TFX_Autolevel_diag_1: 8 Vector__XXX
 SG_ AL_OL_RudderFFPortion : 32|16@1- (0.01,0) [-327.68|327.67] "°" Vector__XXX
 SG_ AL_OL_RetractPortion : 16|16@1- (0.01,0) [-327.68|327.67] "°" Vector__XXX
 SG_ AL_OL_Cmd : 48|16@1- (0.01,0) [-327.68|327.67] "°" Vector__XXX
 SG_ AL_OL_BaseCmd : 0|16@1- (0.01,0) [-327.68|327.67] "°" Vector__XXX

BO_ 2680225591 TFX_Diag_TTA_2: 8 Vector__XXX
 SG_ i16Percent_1 : 7|16@0- (0.01,0) [-125|125] "" Vector__XXX
 SG_ u16Raw_2 : 23|16@0+ (1,0) [0|5000] "" Vector__XXX
 SG_ u16Raw_3 : 39|16@0+ (1,0) [0|5000] "" Vector__XXX
 SG_ i16Percent_4 : 55|16@0- (0.01,0) [-125|125] "" Vector__XXX

BO_ 2680225590 TFX_Diag_TTA_1: 8 Vector__XXX
 SG_ u16Percent_4 : 55|16@0+ (0.01,0) [0|100] "" Vector__XXX
 SG_ u16Percent_3 : 39|16@0+ (0.01,0) [0|125] "" Vector__XXX
 SG_ u16Percent_2 : 23|16@0+ (0.01,0) [0|125] "" Vector__XXX
 SG_ u16Percent_1 : 7|16@0+ (0.01,0) [0|125] "" Vector__XXX

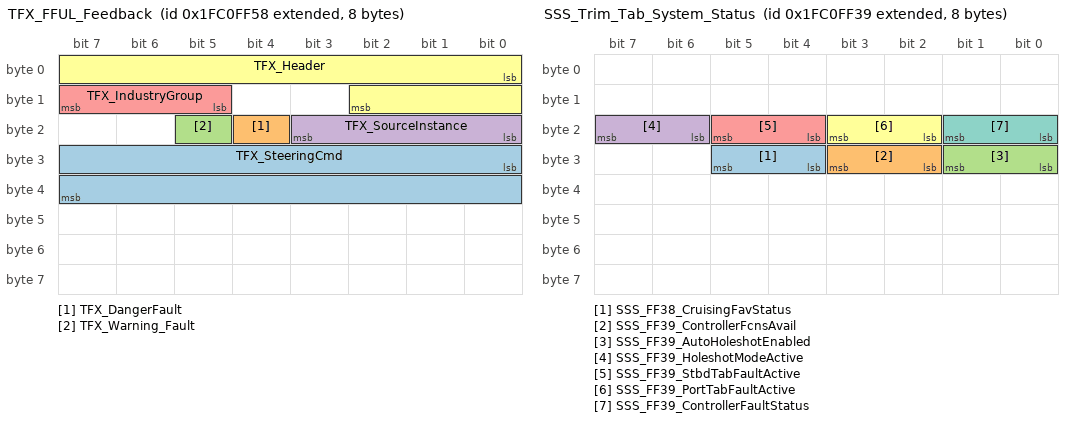
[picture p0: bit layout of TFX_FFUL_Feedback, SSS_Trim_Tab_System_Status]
BO_ 2680225624 TFX_FFUL_Feedback: 8 Vector__XXX
 SG_ TFX_SteeringCmd : 24|16@1- (0.01,0) [-40|40] "deg" Vector__XXX
 SG_ TFX_DangerFault : 20|1@1+ (1,0) [0|0] "" Vector__XXX
 SG_ TFX_Warning_Fault : 21|1@1+ (1,0) [0|0] "" Vector__XXX
 SG_ TFX_SourceInstance : 16|4@1+ (1,0) [0|0] "" Vector__XXX
 SG_ TFX_IndustryGroup : 13|3@1+ (1,0) [0|0] "" Vector__XXX
 SG_ TFX_Header : 0|11@1+ (1,0) [0|2047] "" Vector__XXX

BO_ 2680225593 SSS_Trim_Tab_System_Status: 8 Vector__XXX
 SG_ SSS_FF38_CruisingFavStatus : 28|2@1- (1,0) [0|0] "" Vector__XXX
 SG_ SSS_FF39_ControllerFcnsAvail : 26|2@1+ (1,0) [0|0] "" Vector__XXX
 SG_ SSS_FF39_AutoHoleshotEnabled : 24|2@1+ (1,0) [0|0] "" Vector__XXX
 SG_ SSS_FF39_HoleshotModeActive : 22|2@1+ (1,0) [0|0] "" Vector__XXX
 SG_ SSS_FF39_StbdTabFaultActive : 20|2@1+ (1,0) [0|0] "" Vector__XXX
 SG_ SSS_FF39_PortTabFaultActive : 18|2@1+ (1,0) [0|0] "" Vector__XXX
 SG_ SSS_FF39_ControllerFaultStatus : 16|2@1+ (1,0) [0|0] "" Vector__XXX

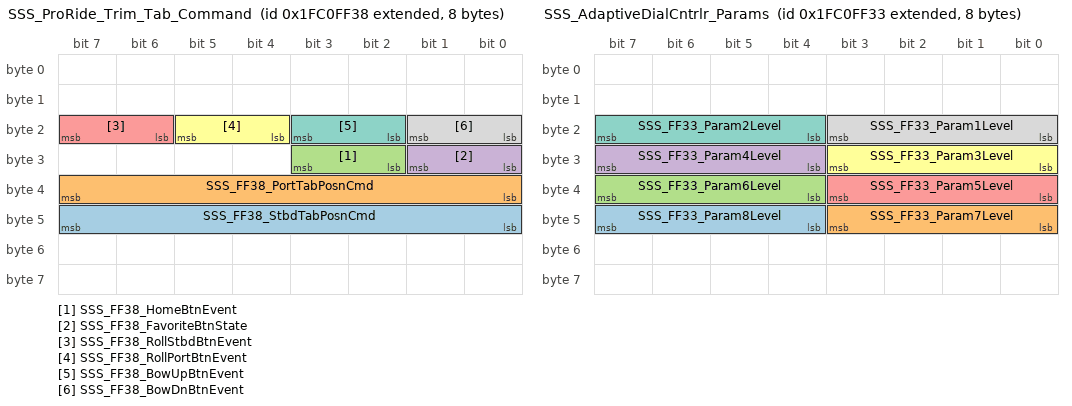
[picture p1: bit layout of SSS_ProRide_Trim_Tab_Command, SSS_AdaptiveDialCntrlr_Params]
BO_ 2680225592 SSS_ProRide_Trim_Tab_Command: 8 Vector__XXX
 SG_ SSS_FF38_StbdTabPosnCmd : 40|8@1- (1,0) [0|0] "" Vector__XXX
 SG_ SSS_FF38_PortTabPosnCmd : 32|8@1- (1,0) [0|0] "" Vector__XXX
 SG_ SSS_FF38_HomeBtnEvent : 26|2@1+ (1,0) [0|0] "" Vector__XXX
 SG_ SSS_FF38_FavoriteBtnState : 24|2@1+ (1,0) [0|0] "" Vector__XXX
 SG_ SSS_FF38_RollStbdBtnEvent : 22|2@1+ (1,0) [0|0] "" Vector__XXX
 SG_ SSS_FF38_RollPortBtnEvent : 20|2@1+ (1,0) [0|0] "" Vector__XXX
 SG_ SSS_FF38_BowUpBtnEvent : 18|2@1+ (1,0) [0|0] "" Vector__XXX
 SG_ SSS_FF38_BowDnBtnEvent : 16|2@1+ (1,0) [0|0] "" Vector__XXX

BO_ 2680225587 SSS_AdaptiveDialCntrlr_Params: 8 Vector__XXX
 SG_ SSS_FF33_Param8Level : 44|4@1+ (1,0) [0|15] "" Vector__XXX
 SG_ SSS_FF33_Param7Level : 40|4@1+ (1,0) [0|15] "" Vector__XXX
 SG_ SSS_FF33_Param6Level : 36|4@1+ (1,0) [0|15] "" Vector__XXX
 SG_ SSS_FF33_Param4Level : 28|4@1+ (1,0) [0|15] "" Vector__XXX
 SG_ SSS_FF33_Param5Level : 32|4@1+ (1,0) [0|15] "" Vector__XXX
 SG_ SSS_FF33_Param3Level : 24|4@1+ (1,0) [0|15] "" Vector__XXX
 SG_ SSS_FF33_Param2Level : 20|4@1+ (1,0) [0|15] "" Vector__XXX
 SG_ SSS_FF33_Param1Level : 16|4@1+ (1,0) [0|15] "" Vector__XXX

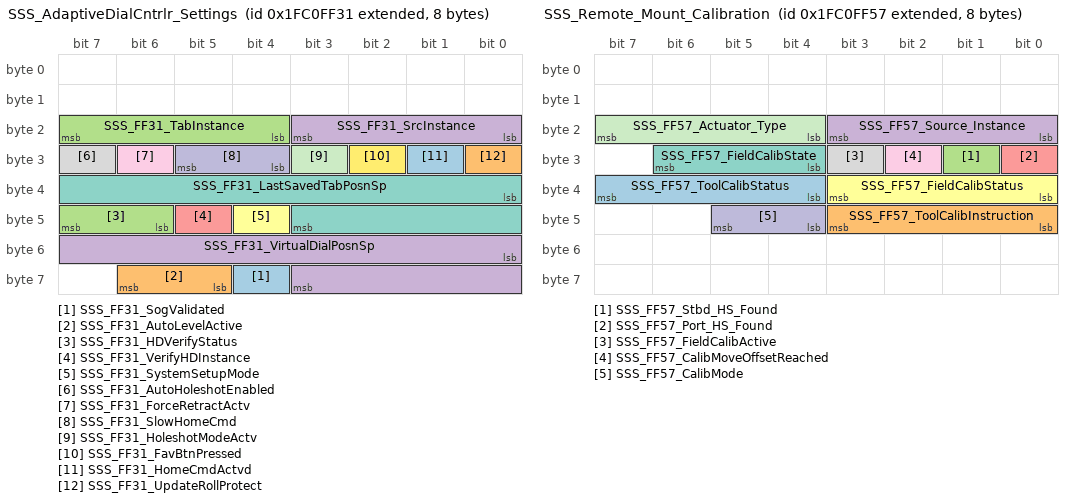
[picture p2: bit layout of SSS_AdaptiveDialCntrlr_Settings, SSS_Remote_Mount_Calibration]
BO_ 2680225585 SSS_AdaptiveDialCntrlr_Settings: 8 Vector__XXX
 SG_ SSS_FF31_SogValidated : 60|1@1+ (1,0) [0|15] "" Vector__XXX
 SG_ SSS_FF31_AutoLevelActive : 61|2@1+ (1,0) [0|15] "" Vector__XXX
 SG_ SSS_FF31_HDVerifyStatus : 46|2@1+ (1,0) [0|0] "" Vector__XXX
 SG_ SSS_FF31_VirtualDialPosnSp : 48|12@1- (0.1,0) [0|15] "%" Vector__XXX
 SG_ SSS_FF31_VerifyHDInstance : 45|1@1+ (1,0) [0|15] "" Vector__XXX
 SG_ SSS_FF31_SystemSetupMode : 44|1@1+ (1,0) [0|15] "" Vector__XXX
 SG_ SSS_FF31_LastSavedTabPosnSp : 32|12@1+ (0.1,0) [0|15] "%" Vector__XXX
 SG_ SSS_FF31_AutoHoleshotEnabled : 31|1@1+ (1,0) [0|15] "" Vector__XXX
 SG_ SSS_FF31_ForceRetractActv : 30|1@1+ (1,0) [0|15] "" Vector__XXX
 SG_ SSS_FF31_SlowHomeCmd : 28|2@1+ (1,0) [0|15] "" Vector__XXX
 SG_ SSS_FF31_HoleshotModeActv : 27|1@1+ (1,0) [0|15] "" Vector__XXX
 SG_ SSS_FF31_FavBtnPressed : 26|1@1+ (1,0) [0|15] "" Vector__XXX
 SG_ SSS_FF31_HomeCmdActvd : 25|1@1+ (1,0) [0|15] "" Vector__XXX
 SG_ SSS_FF31_UpdateRollProtect : 24|1@1+ (1,0) [0|15] "" Vector__XXX
 SG_ SSS_FF31_TabInstance : 20|4@1+ (1,0) [0|15] "" Vector__XXX
 SG_ SSS_FF31_SrcInstance : 16|4@1+ (1,0) [0|15] "" Vector__XXX

BO_ 2680225623 SSS_Remote_Mount_Calibration: 8 Vector__XXX
 SG_ SSS_FF57_ToolCalibStatus : 36|4@1+ (1,0) [0|0] "" Vector__XXX
 SG_ SSS_FF57_ToolCalibInstruction : 40|4@1+ (1,0) [0|0] "" Vector__XXX
 SG_ SSS_FF57_Stbd_HS_Found : 25|1@1+ (1,0) [0|0] "" Vector__XXX
 SG_ SSS_FF57_Source_Instance : 16|4@1+ (1,0) [0|0] "" Vector__XXX
 SG_ SSS_FF57_Port_HS_Found : 24|1@1+ (1,0) [0|0] "" Vector__XXX
 SG_ SSS_FF57_FieldCalibStatus : 32|4@1+ (1,0) [0|0] "" Vector__XXX
 SG_ SSS_FF57_FieldCalibState : 28|3@1+ (1,0) [0|0] "" Vector__XXX
 SG_ SSS_FF57_FieldCalibActive : 27|1@1+ (1,0) [0|0] "" Vector__XXX
 SG_ SSS_FF57_CalibMoveOffsetReached : 26|1@1+ (1,0) [0|0] "" Vector__XXX
 SG_ SSS_FF57_CalibMode : 44|2@1+ (1,0) [0|0] "" Vector__XXX
 SG_ SSS_FF57_Actuator_Type : 20|4@1+ (1,0) [0|0] "" Vector__XXX

BO_ 2680225586 SSS_Actuator_Misc_Settings: 8 Vector__XXX
 SG_ SSS_FF32_SafeMode : 16|2@1+ (1,0) [0|15] "" Vector__XXX
 SG_ IndustryGroup : 13|3@1+ (1,0) [0|0] "" Vector__XXX
 SG_ ManufacturerCode : 0|11@1+ (1,0) [0|0] "" Vector__XXX

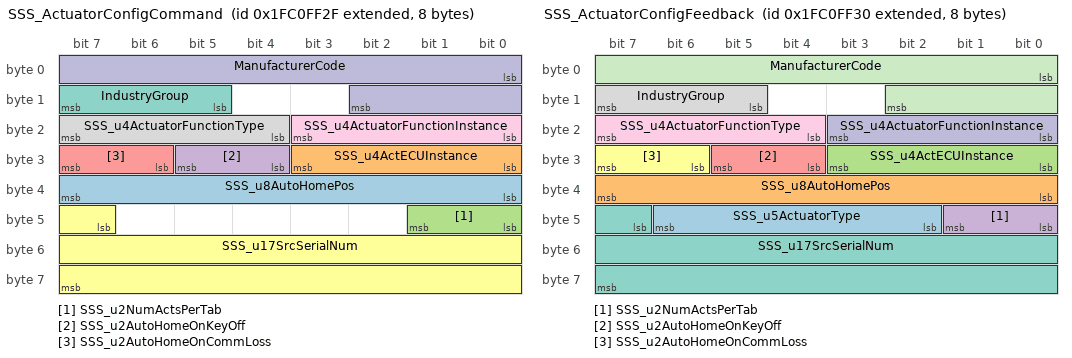
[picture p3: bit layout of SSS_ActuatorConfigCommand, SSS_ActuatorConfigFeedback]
BO_ 2680225583 SSS_ActuatorConfigCommand: 8 Vector__XXX
 SG_ SSS_u8AutoHomePos : 32|8@1+ (1,0) [0|255] "%" Vector__XXX
 SG_ SSS_u4ActECUInstance : 24|4@1+ (1,0) [0|15] "" Vector__XXX
 SG_ SSS_u2NumActsPerTab : 40|2@1+ (1,0) [0|3] "" Vector__XXX
 SG_ SSS_u2AutoHomeOnKeyOff : 28|2@1+ (1,0) [0|3] "" Vector__XXX
 SG_ SSS_u2AutoHomeOnCommLoss : 30|2@1+ (1,0) [0|3] "" Vector__XXX
 SG_ SSS_u17SrcSerialNum : 47|17@1+ (1,0) [0|131071] "" Vector__XXX
 SG_ IndustryGroup : 13|3@1+ (1,0) [0|0] "" Vector__XXX
 SG_ SSS_u4ActuatorFunctionType : 20|4@1+ (1,0) [0|15] "" Vector__XXX
 SG_ SSS_u4ActuatorFunctionInstance : 16|4@1+ (1,0) [0|15] "" Vector__XXX
 SG_ ManufacturerCode : 0|11@1+ (1,0) [0|0] "" Vector__XXX

BO_ 2680225584 SSS_ActuatorConfigFeedback: 8 Vector__XXX
 SG_ SSS_u5ActuatorType : 42|5@1+ (1,0) [0|31] "" Vector__XXX
 SG_ SSS_u8AutoHomePos : 32|8@1+ (1,0) [0|255] "%" Vector__XXX
 SG_ SSS_u4ActECUInstance : 24|4@1+ (1,0) [0|15] "" Vector__XXX
 SG_ SSS_u2NumActsPerTab : 40|2@1+ (1,0) [0|3] "" Vector__XXX
 SG_ SSS_u2AutoHomeOnKeyOff : 28|2@1+ (1,0) [0|3] "" Vector__XXX
 SG_ SSS_u2AutoHomeOnCommLoss : 30|2@1+ (1,0) [0|3] "" Vector__XXX
 SG_ SSS_u17SrcSerialNum : 47|17@1+ (1,0) [0|131071] "" Vector__XXX
 SG_ IndustryGroup : 13|3@1+ (1,0) [0|0] "" Vector__XXX
 SG_ SSS_u4ActuatorFunctionType : 20|4@1+ (1,0) [0|15] "" Vector__XXX
 SG_ SSS_u4ActuatorFunctionInstance : 16|4@1+ (1,0) [0|15] "" Vector__XXX
 SG_ ManufacturerCode : 0|11@1+ (1,0) [0|0] "" Vector__XXX

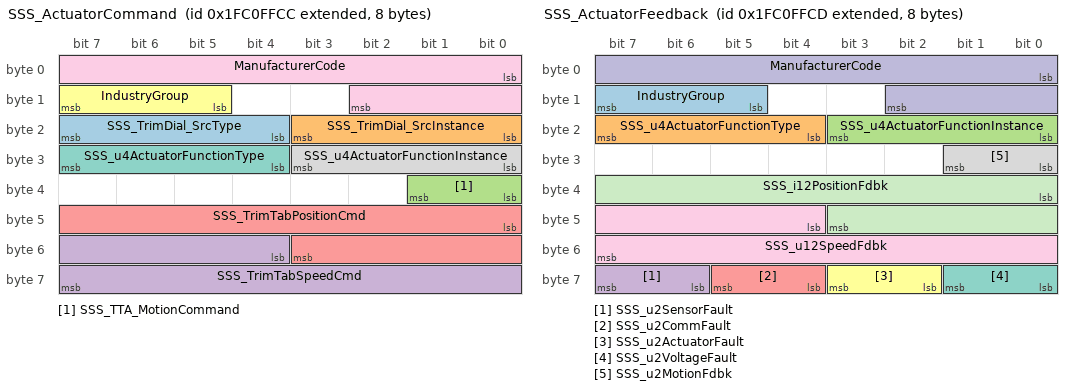
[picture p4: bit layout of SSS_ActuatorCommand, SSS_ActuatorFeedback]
BO_ 2680225740 SSS_ActuatorCommand: 8 Vector__XXX
 SG_ SSS_TrimDial_SrcType : 20|4@1+ (1,0) [0|15] "" Vector__XXX
 SG_ SSS_TrimDial_SrcInstance : 16|4@1+ (1,0) [0|15] "" Vector__XXX
 SG_ SSS_TTA_MotionCommand : 32|2@1+ (1,0) [0|3] "" Vector__XXX
 SG_ SSS_TrimTabSpeedCmd : 52|12@1+ (0.1,0) [1|100] "" Vector__XXX
 SG_ SSS_TrimTabPositionCmd : 40|12@1+ (0.1,0) [0|100] "" Vector__XXX
 SG_ IndustryGroup : 13|3@1+ (1,0) [0|0] "" Vector__XXX
 SG_ SSS_u4ActuatorFunctionType : 28|4@1+ (1,0) [0|15] "" Vector__XXX
 SG_ SSS_u4ActuatorFunctionInstance : 24|4@1+ (1,0) [0|15] "" Vector__XXX
 SG_ ManufacturerCode : 0|11@1+ (1,0) [0|0] "" Vector__XXX

BO_ 2680225741 SSS_ActuatorFeedback: 8 Vector__XXX
 SG_ IndustryGroup : 13|3@1+ (1,0) [0|0] "" Vector__XXX
 SG_ SSS_u4ActuatorFunctionType : 20|4@1+ (1,0) [0|15] "" Vector__XXX
 SG_ SSS_u4ActuatorFunctionInstance : 16|4@1+ (1,0) [0|15] "" Vector__XXX
 SG_ SSS_u2SensorFault : 62|2@1+ (1,0) [0|3] "" Vector__XXX
 SG_ SSS_u2CommFault : 60|2@1+ (1,0) [0|3] "" Vector__XXX
 SG_ SSS_u2ActuatorFault : 58|2@1+ (1,0) [0|3] "" Vector__XXX
 SG_ SSS_u2VoltageFault : 56|2@1+ (1,0) [0|3] "" Vector__XXX
 SG_ SSS_u2MotionFdbk : 24|2@1+ (1,0) [0|3] "" Vector__XXX
 SG_ SSS_u12SpeedFdbk : 44|12@1+ (0.1,0) [0|100] "" Vector__XXX
 SG_ ManufacturerCode : 0|11@1+ (1,0) [0|0] "" Vector__XXX
 SG_ SSS_i12PositionFdbk : 32|12@1- (0.1,0) [-100|100] "" Vector__XXX

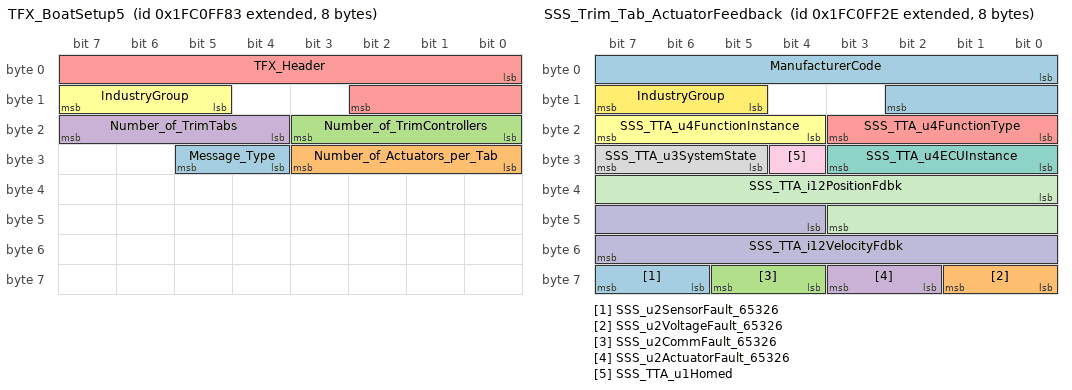
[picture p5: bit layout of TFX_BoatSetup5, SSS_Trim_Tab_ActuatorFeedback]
BO_ 2680225667 TFX_BoatSetup5: 8 Vector__XXX
 SG_ Message_Type : 28|2@1+ (1,0) [0|0] "" Vector__XXX
 SG_ Number_of_Actuators_per_Tab : 24|4@1+ (1,0) [0|0] "" Vector__XXX
 SG_ Number_of_TrimControllers : 16|4@1+ (1,0) [0|0] "" Vector__XXX
 SG_ Number_of_TrimTabs : 20|4@1+ (1,0) [0|0] "" Vector__XXX
 SG_ TFX_Header : 0|11@1+ (1,0) [0|2047] "" Vector__XXX
 SG_ IndustryGroup : 13|3@1+ (1,0) [0|0] "" Vector__XXX

BO_ 2680225790 SSS_FFFE_DM15: 8 Vector__XXX
 SG_ PreDriverState : 32|16@1+ (1,0) [0|0] "" Vector__XXX

BO_ 2680225582 SSS_Trim_Tab_ActuatorFeedback: 8 Vector__XXX
 SG_ SSS_u2SensorFault_65326 : 62|2@1+ (1,0) [0|3] "" Vector__XXX
 SG_ SSS_u2VoltageFault_65326 : 56|2@1+ (1,0) [0|3] "" Vector__XXX
 SG_ SSS_u2CommFault_65326 : 60|2@1+ (1,0) [0|3] "" Vector__XXX
 SG_ SSS_u2ActuatorFault_65326 : 58|2@1+ (1,0) [0|3] "" Vector__XXX
 SG_ SSS_TTA_u4FunctionType : 16|4@1+ (1,0) [-204.8|204.7] "" Vector__XXX
 SG_ SSS_TTA_u4FunctionInstance : 20|4@1+ (1,0) [-204.8|204.7] "" Vector__XXX
 SG_ SSS_TTA_u4ECUInstance : 24|4@1+ (1,0) [-204.8|204.7] "" Vector__XXX
 SG_ SSS_TTA_u3SystemState : 29|3@1+ (1,0) [-204.8|204.7] "" Vector__XXX
 SG_ SSS_TTA_u1Homed : 28|1@1+ (1,0) [-204.8|204.7] "" Vector__XXX
 SG_ SSS_TTA_i12VelocityFdbk : 44|12@1+ (0.1,0) [-204.8|204.7] "" Vector__XXX
 SG_ SSS_TTA_i12PositionFdbk : 32|12@1- (0.1,0) [-204.8|204.7] "" Vector__XXX
 SG_ IndustryGroup : 13|3@1+ (1,0) [0|0] "" Vector__XXX
 SG_ ManufacturerCode : 0|11@1+ (1,0) [0|0] "" Vector__XXX

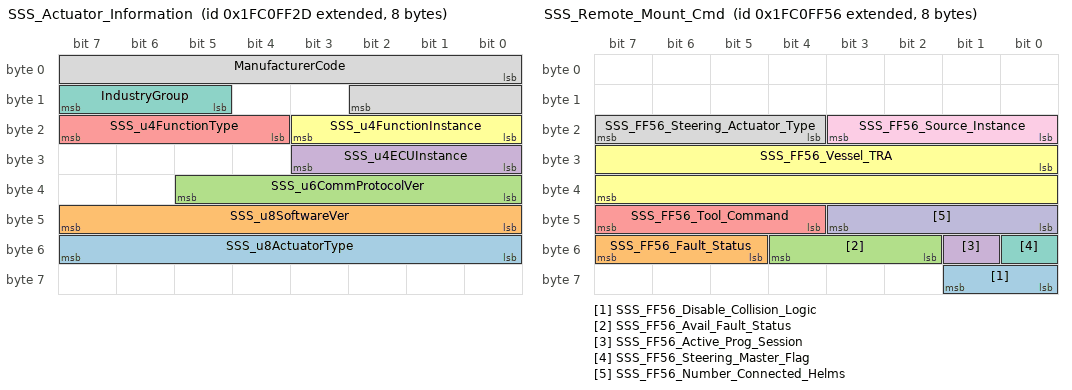
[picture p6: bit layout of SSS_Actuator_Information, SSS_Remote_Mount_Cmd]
BO_ 2680225581 SSS_Actuator_Information: 8 Vector__XXX
 SG_ SSS_u8ActuatorType : 48|8@1+ (1,0) [0|255] "" Vector__XXX
 SG_ SSS_u8SoftwareVer : 40|8@1+ (1,0) [0|255] "" Vector__XXX
 SG_ SSS_u6CommProtocolVer : 32|6@1+ (1,0) [0|63] "" Vector__XXX
 SG_ SSS_u4ECUInstance : 24|4@1+ (1,0) [0|15] "" Vector__XXX
 SG_ SSS_u4FunctionType : 20|4@1+ (1,0) [0|15] "" Vector__XXX
 SG_ SSS_u4FunctionInstance : 16|4@1+ (1,0) [0|15] "" Vector__XXX
 SG_ IndustryGroup : 13|3@1+ (1,0) [0|0] "" Vector__XXX
 SG_ ManufacturerCode : 0|11@1+ (1,0) [0|0] "" Vector__XXX

BO_ 2680225622 SSS_Remote_Mount_Cmd: 8 Vector__XXX
 SG_ SSS_FF56_Disable_Collision_Logic : 56|2@1+ (1,0) [0|0] "" Vector__XXX
 SG_ SSS_FF56_Fault_Status : 53|3@1+ (1,0) [0|0] "" Vector__XXX
 SG_ SSS_FF56_Avail_Fault_Status : 50|3@1+ (1,0) [0|0] "" Vector__XXX
 SG_ SSS_FF56_Active_Prog_Session : 49|1@1+ (1,0) [0|0] "" Vector__XXX
 SG_ SSS_FF56_Tool_Command : 44|4@1+ (1,0) [0|0] "" Vector__XXX
 SG_ SSS_FF56_Vessel_TRA : 24|16@1- (1,0) [0|0] "" Vector__XXX
 SG_ SSS_FF56_Steering_Master_Flag : 48|1@1+ (1,0) [0|0] "" Vector__XXX
 SG_ SSS_FF56_Steering_Actuator_Type : 20|4@1+ (1,0) [0|0] "" Vector__XXX
 SG_ SSS_FF56_Source_Instance : 16|4@1+ (1,0) [0|0] "" Vector__XXX
 SG_ SSS_FF56_Number_Connected_Helms : 40|4@1+ (1,0) [0|0] "" Vector__XXX

BO_ 2680225786 SSS_FFFA_DM10: 8 Vector__XXX
 SG_ SSS_FFFA_Motor_Current_Sq_30min m6 : 16|16@1+ (1,0) [0|0] "" Vector__XXX
 SG_ SSS_FFFA_Motor_Current_Sq_5sec m5 : 16|16@1+ (1,0) [0|0] "" Vector__XXX
 SG_ SSS_FFFA_Motor_Current_Sq_5min m5 : 48|16@1+ (1,0) [0|0] "" Vector__XXX
 SG_ SSS_FFFA_Motor_Current_Sq_1min m5 : 32|16@1+ (1,0) [0|0] "" Vector__XXX
 SG_ SSS_FFFA_Temperature m4 : 24|16@1- (0.01,0) [0|0] "" Vector__XXX
 SG_ SSS_FFFA_Motor_RPM m4 : 8|16@1+ (1,0) [0|0] "" Vector__XXX
 SG_ SSS_FFFA_Invalid_Com_Counts m4 : 40|16@1+ (1,0) [0|0] "" Vector__XXX
 SG_ SSS_FFFA_Toe_Angle m3 : 8|8@1- (0.01,0) [0|0] "" Vector__XXX
 SG_ SSS_FFFA_SCU_State m3 : 24|8@1+ (1,0) [0|0] "" Vector__XXX
 SG_ SSS_FFFA_Number_Of_Helm_Turns m3 : 16|8@1+ (1,0) [0|0] "" Vector__XXX
 SG_ SSS_FFFA_Calibration_State m3 : 32|8@1+ (1,0) [0|0] "" Vector__XXX
 SG_ SSS_FFFA_Warning_Fault m2 : 10|1@1+ (1,0) [0|0] "" Vector__XXX
 SG_ SSS_FFFA_Wake_Up_B m2 : 12|1@1+ (1,0) [0|0] "" Vector__XXX
 SG_ SSS_FFFA_Wake_Up_A m2 : 13|1@1+ (1,0) [0|0] "" Vector__XXX
 SG_ SSS_FFFA_Override m2 : 8|1@1+ (1,0) [0|0] "" Vector__XXX
 SG_ SSS_FFFA_Motor_Circuit_Error_Bit m2 : 22|1@1+ (1,0) [0|0] "" Vector__XXX
 SG_ SSS_FFFA_Limp_Home m2 : 23|1@1+ (1,0) [0|0] "" Vector__XXX
 SG_ SSS_FFFA_Ignition_Switch m2 : 14|1@1+ (1,0) [0|0] "" Vector__XXX
 SG_ SSS_FFFA_High_Speed_Rudder_Lock m2 : 15|1@1+ (1,0) [0|0] "" Vector__XXX
 SG_ SSS_FFFA_Derated_Flag m2 : 9|1@1+ (1,0) [0|0] "" Vector__XXX
 SG_ SSS_FFFA_Danger_Fault m2 : 11|1@1+ (1,0) [0|0] "" Vector__XXX
 SG_ SSS_FFFA_ID M : 0|8@1+ (1,0) [0|0] "" Vector__XXX

BO_ 2680225785 SSS_FFF9_DM9: 8 Vector__XXX
 SG_ SSS_FFF9_Motor_Sensor_Angle : 16|16@1- (0.01,0) [0|0] "" Vector__XXX
 SG_ SSS_FFF9_Active_Phase : 0|8@1+ (1,0) [0|0] "" Vector__XXX
 SG_ SSS_FFF9_PWM_Output : 48|16@1- (0.01,0) [0|0] "" Vector__XXX
 SG_ SSS_FFF9_PWM_Command : 32|16@1- (0.01,0) [0|0] "" Vector__XXX
 SG_ SSS_FFF9_Hall_State : 8|8@1+ (1,0) [0|0] "" Vector__XXX

BO_ 2680225784 SSS_FFF8_DM8: 8 Vector__XXX
 SG_ SSS_FFF8_Abs_Raw_Angle_1 : 32|16@1- (0.01,0) [0|0] "" Vector__XXX
 SG_ SSS_FFF8_Abs_Sensor_Angle_2 : 16|16@1- (0.01,0) [0|0] "" Vector__XXX
 SG_ SSS_FFF8_Abs_Sensor_Angle_1 : 0|16@1- (0.01,0) [0|0] "" Vector__XXX
 SG_ SSS_FFF8_Abs_Raw_Angle_2 : 48|16@1- (0.01,0) [0|0] "" Vector__XXX

BO_ 2680225783 SSS_FFF7_DM7: 8 Vector__XXX
 SG_ SSS_FFF7_Virtual_Sensor_Counts : 48|16@1- (1,0) [0|0] "" Vector__XXX
 SG_ SSS_FFF7_Virtual_Sensor_Angle : 32|16@1- (0.01,0) [0|0] "" Vector__XXX
 SG_ SSS_FFF7_Target_Rudder_Angle : 0|16@1- (0.01,0) [0|0] "" Vector__XXX
 SG_ SSS_FFF7_Combined_Pos_Angle : 16|16@1- (0.01,0) [0|0] "" Vector__XXX

BO_ 2680225782 SSS_FFF6_DM6: 8 Vector__XXX
 SG_ SSS_FFF6_Battery_Voltage : 48|16@1+ (0.001,0) [0|0] "" Vector__XXX
 SG_ SSS_FFF6_Phase_C_Current : 32|16@1- (0.01,0) [0|0] "" Vector__XXX
 SG_ SSS_FFF6_Phase_A_Current : 0|16@1- (0.01,0) [0|0] "" Vector__XXX
 SG_ SSS_FFF6_Phase_B_Current : 16|16@1- (0.01,0) [0|0] "" Vector__XXX

BO_ 2680225781 SSS_FFF5_DM5: 8 Vector__XXX
 SG_ SSS_FFF5_Motor_Current : 0|16@1- (0.1,0) [0|0] "" Vector__XXX
 SG_ SSS_FFF5_Filtered_Motor_Current : 16|16@1- (0.1,0) [0|0] "" Vector__XXX
 SG_ SSS_FFF5_Filtered_Batt_Current : 48|16@1- (0.1,0) [0|0] "" Vector__XXX
 SG_ SSS_FFF5_Battery_Current : 32|16@1- (0.1,0) [0|0] "" Vector__XXX

BO_ 2680225780 SSS_FFF4_DM4: 8 Vector__XXX
 SG_ SSS_FFF4_Unsaturated_PID : 32|16@1- (0.01,0) [0|0] "" Vector__XXX
 SG_ SSS_FFF4_Position_Error : 48|16@1- (0.01,0) [0|0] "" Vector__XXX
 SG_ SSS_FFF4_D_Term : 0|16@1- (0.01,0) [0|0] "" Vector__XXX
 SG_ SSS_FFF4_Back_Calculation_Term : 16|16@1- (0.01,0) [0|0] "" Vector__XXX

BO_ 2680225779 SSS_FFF3_DM3: 8 Vector__XXX
 SG_ SSS_FFF3_Velocity_FF : 32|16@1- (0.01,0) [0|0] "" Vector__XXX
 SG_ SSS_FFF3_PID_Total : 48|16@1- (0.01,0) [0|0] "" Vector__XXX
 SG_ SSS_FFF3_P_Term : 0|16@1- (0.01,0) [0|0] "" Vector__XXX
 SG_ SSS_FFF3_I_Term : 16|16@1- (0.01,0) [0|0] "" Vector__XXX

BO_ 2680225778 SSS_FFF2_DM2: 8 Vector__XXX
 SG_ SSS_FFF2_Coil_Temp : 48|16@1- (0.01,0) [0|0] "" Vector__XXX
 SG_ SSS_FFF2_Coil_Resistance : 32|16@1- (0.001,0) [0|0] "" Vector__XXX
 SG_ SSS_FFF2_Brake_PWM : 16|16@1+ (0.01,0) [0|0] "" Vector__XXX
 SG_ SSS_FFF2_Brake_Current : 0|16@1+ (0.001,0) [0|0] "" Vector__XXX

BO_ 2680225777 SSS_FFF1_DM1: 8 Vector__XXX
 SG_ SSS_FFF1_STBD_Stop_Angle : 48|16@1- (0.01,0) [0|0] "" Vector__XXX
 SG_ SSS_FFF1_STBD_Slow_Angle : 32|16@1- (0.01,0) [0|0] "" Vector__XXX
 SG_ SSS_FFF1_Port_Stop_Angle : 16|16@1- (0.01,0) [0|0] "" Vector__XXX
 SG_ SSS_FFF1_Port_Slow_Angle : 0|16@1- (0.01,0) [0|0] "" Vector__XXX

BO_ 2147544832 CCPComMessage: 8 Vector__XXX
 SG_ CPP_Command : 0|8@1+ (1,0) [0|255] "" Vector__XXX

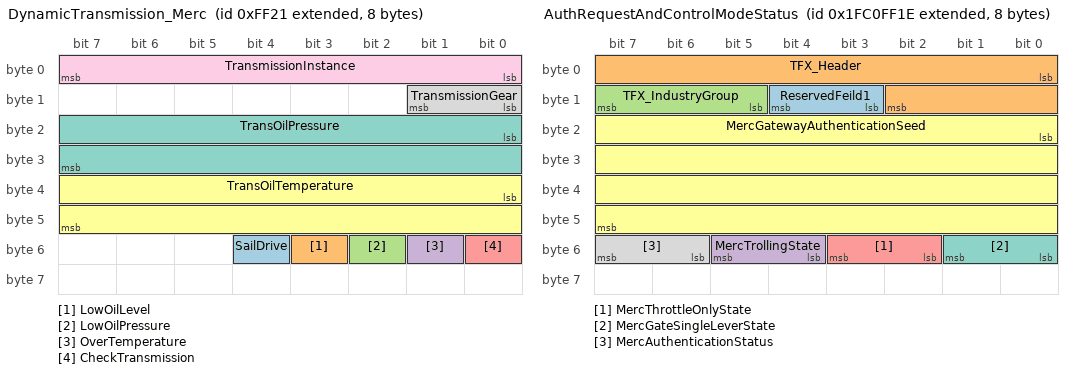
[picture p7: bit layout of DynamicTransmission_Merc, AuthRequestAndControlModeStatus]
BO_ 2147548961 DynamicTransmission_Merc: 8 Vector__XXX
 SG_ SailDrive : 52|1@1+ (1,0) [0|1] "" Vector__XXX
 SG_ LowOilLevel : 51|1@1+ (1,0) [0|1] "" Vector__XXX
 SG_ LowOilPressure : 50|1@1+ (1,0) [0|1] "" Vector__XXX
 SG_ OverTemperature : 49|1@1+ (1,0) [0|1] "" Vector__XXX
 SG_ CheckTransmission : 48|1@1+ (1,0) [0|1] "" Vector__XXX
 SG_ TransOilTemperature : 32|16@1+ (0.1,0) [0|6553.2] "degK" Vector__XXX
 SG_ TransOilPressure : 16|16@1+ (100,0) [0|6553200] "Pa" Vector__XXX
 SG_ TransmissionGear : 8|2@1+ (1,0) [0|3] "" Vector__XXX
 SG_ TransmissionInstance : 0|8@1+ (1,0) [0|255] "" Vector__XXX

BO_ 2147548960 EngineParametersRapidUpdate_Merc: 8 Vector__XXX
 SG_ EngineTiltTrim : 40|8@1- (1,0) [0|0] "%" Vector__XXX
 SG_ EngineBoostPressure : 24|16@1+ (100,0) [0|6553200] "Pa" Vector__XXX
 SG_ EngineSpeed : 8|16@1+ (0.25,0) [0|16383] "RPM" Vector__XXX
 SG_ EngineInstance : 0|8@1+ (1,0) [0|255] "" Vector__XXX

BO_ 2680225567 AuthenticationResponce: 8 Vector__XXX
 SG_ TFX_IndustryGroup : 13|3@1+ (1,0) [0|0] "" Vector__XXX
 SG_ TFX_Header : 0|11@1+ (1,0) [0|2047] "" Vector__XXX
 SG_ GeneratedKey : 16|32@1+ (1,0) [0|0] "" Vector__XXX

BO_ 2680225566 AuthRequestAndControlModeStatus: 8 Vector__XXX
 SG_ ReservedFeild1 : 11|2@1+ (1,0) [0|0] "" Vector__XXX
 SG_ TFX_Header : 0|11@1+ (1,0) [0|0] "" Vector__XXX
 SG_ TFX_IndustryGroup : 13|3@1+ (1,0) [0|0] "" Vector__XXX
 SG_ MercTrollingState : 52|2@1+ (1,0) [0|0] "" Vector__XXX
 SG_ MercThrottleOnlyState : 50|2@1+ (1,0) [0|0] "" Vector__XXX
 SG_ MercGatewayAuthenticationSeed : 16|32@1+ (1,0) [0|0] "" Vector__XXX
 SG_ MercGateSingleLeverState : 48|2@1+ (1,0) [0|0] "" Vector__XXX
 SG_ MercAuthenticationStatus : 54|2@1+ (1,0) [0|0] "" Vector__XXX

BO_ 2680225603 TFX_AutopilotFbk_3: 8 Vector__XXX
 SG_ Target_Heading : 16|16@1+ (0.01,0) [0|360] "°" Vector__XXX
 SG_ Target_COG : 32|16@1+ (0.01,0) [0|360] "°" Vector__XXX

BO_ 2680225602 TFX_AutopilotFbk_2: 8 Vector__XXX
 SG_ XTE_Internal : 16|16@1- (0.1,0) [0|200] "m" Vector__XXX
 SG_ XTE_Limit : 32|16@1+ (0.1,0) [0|500] "m" Vector__XXX

BO_ 2680225710 TFX_Diagnostics_Gtwy_ECM_Port: 8 Vector__XXX
 SG_ LPS_ECM_Stbd_1 : 48|16@1+ (0.001220703125,0) [0|0] "V" Vector__XXX
 SG_ LPS_ECM_Port_3 : 32|16@1+ (0.001220703125,0) [0|0] "V" Vector__XXX
 SG_ LPS_ECM_Port_2 : 16|16@1+ (0.001220703125,0) [0|0] "V" Vector__XXX
 SG_ LPS_ECM_Port_1 : 0|16@1+ (0.001220703125,0) [0|0] "V" Vector__XXX

BO_ 2680225601 TFX_AutopilotFbk_1: 8 Vector__XXX
 SG_ ShowXTELimits : 31|1@1+ (1,0) [0|1] "" Vector__XXX
 SG_ RouteTurnBuzzOption : 23|1@1+ (1,0) [0|1] "" Vector__XXX
 SG_ RouteOverrideScrRqst : 28|1@1+ (1,0) [0|1] "" Vector__XXX
 SG_ RouteInitScrRqst : 27|1@1+ (1,0) [0|1] "" Vector__XXX
 SG_ RouteEndBuzzOpt : 30|1@1+ (1,0) [0|1] "" Vector__XXX
 SG_ AutopilotEnabled : 18|1@1+ (1,0) [0|1] "" Vector__XXX
 SG_ AutopilotAvailable : 17|1@1+ (1,0) [0|1] "" Vector__XXX
 SG_ CourseChange : 32|16@1- (0.01,0) [-327.68|327.67] "°" Vector__XXX
 SG_ RouteEndReq : 29|1@1+ (1,0) [0|0] "" Vector__XXX
 SG_ GPS_SourceAddr : 48|8@1+ (1,0) [0|0] "" Vector__XXX
 SG_ CourseChangeReq : 22|1@1+ (1,0) [0|0] "" Vector__XXX
 SG_ Compass_SourceAddr : 56|8@1+ (1,0) [0|0] "" Vector__XXX
 SG_ RouteModeAvailable : 21|1@1+ (1,0) [0|0] "" Vector__XXX
 SG_ TrackModeAvailable : 20|1@1+ (1,0) [0|0] "" Vector__XXX
 SG_ HeadingModeAvailable : 19|1@1+ (1,0) [0|0] "" Vector__XXX
 SG_ AutopiloteMode : 24|3@1+ (1,0) [0|0] "" Vector__XXX
 SG_ LicenseExists : 16|1@1+ (1,0) [0|1] "" Vector__XXX
 SG_ IndustryGroup : 13|3@1+ (1,0) [0|0] "" Vector__XXX
 SG_ ManufacturerCode : 0|11@1+ (1,0) [0|0] "" Vector__XXX

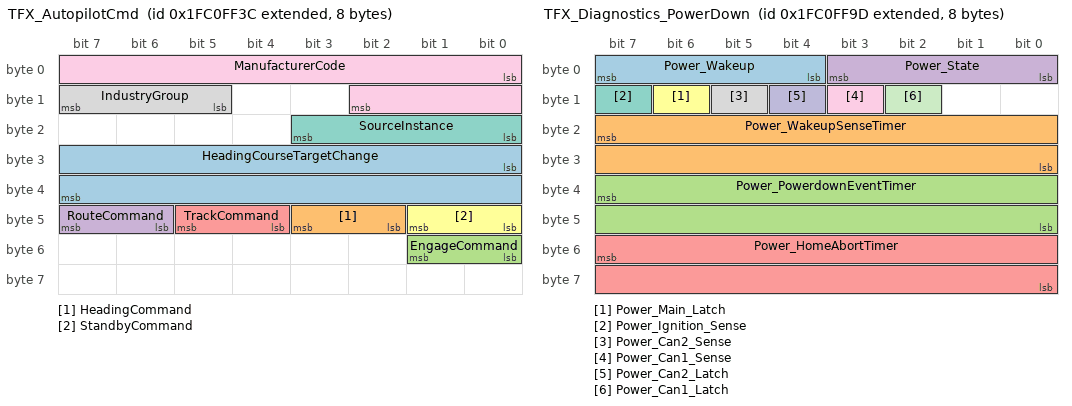
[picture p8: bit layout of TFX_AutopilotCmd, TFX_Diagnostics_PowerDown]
BO_ 2680225596 TFX_AutopilotCmd: 8 Vector__XXX
 SG_ HeadingCourseTargetChange : 24|16@1- (0.1,0) [0|0] "°" Vector__XXX
 SG_ HeadingCommand : 42|2@1+ (1,0) [0|3] "" Vector__XXX
 SG_ EngageCommand : 48|2@1+ (1,0) [0|3] "" Vector__XXX
 SG_ RouteCommand : 46|2@1+ (1,0) [0|3] "" Vector__XXX
 SG_ TrackCommand : 44|2@1+ (1,0) [0|3] "" Vector__XXX
 SG_ StandbyCommand : 40|2@1+ (1,0) [0|3] "" Vector__XXX
 SG_ SourceInstance : 16|4@1+ (1,0) [0|15] "" Vector__XXX
 SG_ IndustryGroup : 13|3@1+ (1,0) [0|0] "" Vector__XXX
 SG_ ManufacturerCode : 0|11@1+ (1,0) [0|0] "" Vector__XXX

BO_ 2147612933 NavigationDataRouteWpInfo: 8 Vector__XXX

BO_ 2680225748 TFX_Autopilot_Diag5: 8 Vector__XXX
 SG_ Autopilot_Diag5_PosY_N : 32|32@1- (0.01,0) [0|0] "m" Vector__XXX
 SG_ Autopilot_Diag5_PosX_N : 0|32@1- (0.01,0) [0|0] "m" Vector__XXX

BO_ 2680225747 TFX_Autopilot_Diag4: 8 Vector__XXX
 SG_ AP_HeadingError : 0|16@1- (0.01,0) [-30|30] "°" Vector__XXX
 SG_ AP_Heading_P : 16|16@1- (0.01,0) [-30|30] "°" Vector__XXX
 SG_ AP_Heading_I : 32|16@1- (0.01,0) [-30|30] "°" Vector__XXX
 SG_ AP_Heading_D : 48|16@1- (0.01,0) [-30|30] "°" Vector__XXX

BO_ 2680225746 TFX_Autopilot_Diag3: 8 Vector__XXX
 SG_ AP_RawTargetHeading : 0|16@1+ (0.01,0) [0|360] "°" Vector__XXX
 SG_ AP_SlewedTargetHeading : 16|16@1+ (0.01,0) [0|360] "°" Vector__XXX
 SG_ AP_HeadingVelocityFF : 48|16@1- (0.01,0) [-15|15] "°" Vector__XXX
 SG_ AP_HeadingAccelFF : 32|16@1- (0.01,0) [-15|15] "°" Vector__XXX

BO_ 2680225745 TFX_Autopilot_Diag2: 8 Vector__XXX
 SG_ AP_XTE : 0|16@1- (0.01,0) [-30|30] "m" Vector__XXX
 SG_ AP_Track_P : 16|16@1- (0.01,0) [-30|30] "°" Vector__XXX
 SG_ AP_Track_I : 32|16@1- (0.01,0) [-30|30] "°" Vector__XXX
 SG_ AP_Track_D : 48|16@1- (0.01,0) [-30|30] "°" Vector__XXX

BO_ 2680225744 TFX_Autopilot_Diag1: 8 Vector__XXX
 SG_ AP_TrackVelocityFF : 48|16@1- (0.01,0) [-15|15] "°" Vector__XXX
 SG_ AP_TrackAccelFF : 32|16@1- (0.01,0) [-15|15] "°" Vector__XXX
 SG_ AP_SlewedTargetTrack : 16|16@1+ (0.01,0) [0|360] "°" Vector__XXX
 SG_ AP_RawTargetTrack : 0|16@1+ (0.01,0) [0|360] "°" Vector__XXX

BO_ 2680225692 TFX_Diagnostics_PCM_WrongDir: 8 Vector__XXX
 SG_ PCM_WrgDir_Accum : 40|16@1- (0.001,0) [-2|2] "°" Vector__XXX
 SG_ PCM_WrgDir_HS : 32|8@1+ (1,0) [0|3] "" Vector__XXX
 SG_ PCM_WrgDir_CylMvmt : 16|16@1- (0.001,0) [-0.3|0.3] "°" Vector__XXX
 SG_ PCM_WrgDir_Pwm : 0|16@1- (0.01,0) [-100|100] "%" Vector__XXX

BO_ 2147544833 HEM_Diag: 8 Vector__XXX
 SG_ HEM_CMDL : 0|8@1+ (1,0) [0|0] "" Vector__XXX
 SG_ HEM_CMDH_type : 13|2@1- (1,0) [0|0] "" Vector__XXX
 SG_ HEM_CMDH_reserved : 10|3@1+ (1,0) [0|0] "" Vector__XXX
 SG_ HEM_CMDH_multiframe : 15|1@1+ (1,0) [0|0] "" Vector__XXX
 SG_ HEM_CMDH_data : 8|2@1+ (1,0) [0|0] "" Vector__XXX

BO_ 2680422144 MysteryMsg: 8 Vector__XXX

BO_ 2680225720 TFX_Diag_i7700_4: 8 Vector__XXX
 SG_ IsrAddr : 0|32@1+ (1,0) [0|0] "" Vector__XXX
 SG_ CPU_Reset_Source : 39|16@0+ (1,0) [0|0] "" Vector__XXX
 SG_ DiagBackupFlag : 48|16@1+ (1,0) [0|0] "" Vector__XXX

BO_ 2680225556 Yanmar_Engine_Data: 8 Vector__XXX
 SG_ TFX_Header : 0|16@1+ (1,0) [0|0] "" Vector__XXX
 SG_ EngineTiltTrim : 48|8@1- (1,0) [0|0] "%" Vector__XXX
 SG_ EngineOilPressure : 32|16@1+ (100,0) [0|6553200] "Pa" Vector__XXX
 SG_ EngineStatus : 24|8@1+ (1,0) [0|0] "" Vector__XXX
 SG_ Instance : 21|3@1+ (1,0) [0|4] "" Vector__XXX
 SG_ MessageGroup : 16|5@1+ (1,0) [0|31] "" Vector__XXX

BO_ 2680225734 TFX_Diag_ASK_8_TPID: 8 Vector__XXX
 SG_ ASK_T_P : 7|16@0- (0.01,0) [-110|110] "%" Vector__XXX
 SG_ ASK_T_I : 23|16@0- (0.01,0) [-110|110] "%" Vector__XXX
 SG_ ASK_T_D : 39|16@0- (0.01,0) [-110|110] "%" Vector__XXX

BO_ 2680225733 TFX_Diag_ASK_7_YPID: 8 Vector__XXX
 SG_ ASK_Y_P : 7|16@0- (0.01,0) [-110|110] "%" Vector__XXX
 SG_ ASK_Y_I : 23|16@0- (0.01,0) [-110|110] "%" Vector__XXX
 SG_ ASK_Y_D : 39|16@0- (0.01,0) [-110|110] "%" Vector__XXX

BO_ 2680225732 TFX_Diag_ASK_6_XPID: 8 Vector__XXX
 SG_ ASK_X_P : 7|16@0- (0.01,0) [-110|110] "%" Vector__XXX
 SG_ ASK_X_I : 23|16@0- (0.01,0) [-110|110] "%" Vector__XXX
 SG_ ASK_X_D : 39|16@0- (0.01,0) [-110|110] "%" Vector__XXX

BO_ 2680225731 TFX_Diag_ASK_5_XYTerr: 8 Vector__XXX
 SG_ ASK_Yerr : 23|16@0- (0.01,0) [-20|20] "m" Vector__XXX
 SG_ ASK_Xerr : 7|16@0- (0.01,0) [-20|20] "m" Vector__XXX
 SG_ ASK_Terr : 39|16@0- (0.01,0) [-20|20] "°" Vector__XXX

BO_ 2680225730 TFX_Diag_ASK_4_Cmds: 8 Vector__XXX
 SG_ ASK_Ycmd : 39|16@0- (0.01,0) [-110|110] "%" Vector__XXX
 SG_ ASK_Xcmd : 23|16@0- (0.01,0) [-110|110] "%" Vector__XXX
 SG_ ASK_Tcmd : 55|16@0- (0.01,0) [-110|110] "%" Vector__XXX
 SG_ ASK_AskZone : 15|8@0+ (1,0) [0|10] "" Vector__XXX
 SG_ ASK_AskMode : 7|8@0+ (1,0) [0|5] "" Vector__XXX

BO_ 2680225729 TFX_Diag_ASK_3_PosErr: 8 Vector__XXX
 SG_ ASK_LonErrM : 55|16@0- (0.01,0) [-20|20] "m" Vector__XXX
 SG_ ASK_LonErr : 23|16@0- (1E-007,0) [-0.0001|0.0001] "°" Vector__XXX
 SG_ ASK_LatErrM : 39|16@0- (0.01,0) [-20|20] "m" Vector__XXX
 SG_ ASK_LatErr : 7|16@0- (1E-007,0) [-0.0001|0.0001] "°" Vector__XXX

BO_ 2680225728 TFX_Diag_ASK_2_Heading: 8 Vector__XXX
 SG_ ASK_HeadingSP : 7|32@0- (0.01,0) [0|360] "°" Vector__XXX
 SG_ ASK_HeadingFbk : 39|32@0- (0.01,0) [0|360] "°" Vector__XXX

BO_ 2680225727 TFX_Diag_ASK_1_PosFbk: 8 Vector__XXX
 SG_ ASK_LonFbk : 39|32@0- (1E-007,0) [-180|180] "°" Vector__XXX
 SG_ ASK_LatFbk : 7|32@0- (1E-007,0) [-180|180] "°" Vector__XXX

BO_ 2680225726 TFX_Diag_ASK_0_PosSP: 8 Vector__XXX
 SG_ ASK_LonSP : 39|32@0- (1E-007,0) [-180|180] "°" Vector__XXX
 SG_ ASK_LatSP : 7|32@0- (1E-007,0) [-180|180] "°" Vector__XXX

BO_ 2680225618 TFX_Helm_Command_2: 8 Vector__XXX
 SG_ TFX_PCM_Command : 16|4@1+ (1,0) [0|0] "" Vector__XXX
 SG_ TFX_Helm_SteeringResistance : 20|12@1+ (0.1,0) [0|0] "%" Vector__XXX
 SG_ TFX_Helm_StbdAngleToBrake : 48|16@1- (0.1,0) [0|0] "°" Vector__XXX
 SG_ TFX_Helm_PortAngleToBrake : 32|16@1- (0.1,0) [0|0] "°" Vector__XXX
 SG_ TFX_IndustryGroup : 13|3@1+ (1,0) [0|0] "" Vector__XXX
 SG_ TFX_Header : 0|11@1+ (1,0) [0|2047] "" Vector__XXX

BO_ 2147545092 EEC1: 8 Vector__XXX
 SG_ J1939_EngTorqueMode : 0|4@1+ (1,0) [0|0] "" Vector__XXX
 SG_ J1939_EngStarterMode : 48|4@1+ (1,0) [0|0] "" Vector__XXX
 SG_ J1939_EngineSpeed : 24|16@1+ (0.125,0) [0|8031.875] "RPM" Vector__XXX
 SG_ J1939_EngDemand : 56|8@1- (1,0) [-125|125] "" Vector__XXX
 SG_ J1939_EngCntrlDeviceSA : 40|8@1+ (1,0) [0|253] "" Vector__XXX
 SG_ J1939_DriverDemandTrq : 8|8@1- (1,0) [-125|125] "%" Vector__XXX
 SG_ J1939_ActualEngTorque : 16|8@1- (1,0) [-125|125] "" Vector__XXX

BO_ 2147610906 MagneticVariation: 8 Vector__XXX
 SG_ Variation : 32|16@1- (0.00573,0) [-180|180] "deg" Vector__XXX
 SG_ AgeOfService : 16|16@1+ (1,0) [0|0] "> Jan1, 1970" Vector__XXX
 SG_ VariationSource : 8|4@1+ (1,0) [0|0] "" Vector__XXX
 SG_ SequenceID : 0|8@1+ (1,0) [0|252] "" Vector__XXX

BO_ 2680225693 TFX_Diagnostics_PowerDown: 8 Vector__XXX
 SG_ Power_Wakeup : 7|4@0+ (1,0) [0|0] "" Vector__XXX
 SG_ Power_WakeupSenseTimer : 23|16@0+ (1,0) [0|0] "" Vector__XXX
 SG_ Power_PowerdownEventTimer : 39|16@0+ (1,0) [0|0] "" Vector__XXX
 SG_ Power_State : 3|4@0+ (1,0) [0|0] "" Vector__XXX
 SG_ Power_HomeAbortTimer : 55|16@0+ (1,0) [0|0] "" Vector__XXX
 SG_ Power_Main_Latch : 14|1@0+ (1,0) [0|0] "" Vector__XXX
 SG_ Power_Ignition_Sense : 15|1@0+ (1,0) [0|0] "" Vector__XXX
 SG_ Power_Can2_Sense : 13|1@0+ (1,0) [0|0] "" Vector__XXX
 SG_ Power_Can1_Sense : 11|1@0+ (1,0) [0|0] "" Vector__XXX
 SG_ Power_Can2_Latch : 12|1@0+ (1,0) [0|0] "" Vector__XXX
 SG_ Power_Can1_Latch : 10|1@0+ (1,0) [0|0] "" Vector__XXX

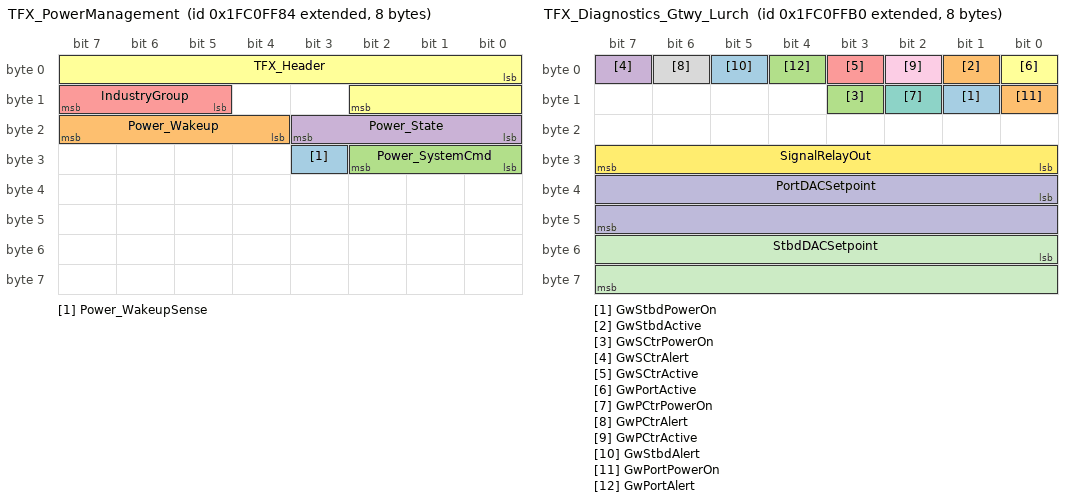
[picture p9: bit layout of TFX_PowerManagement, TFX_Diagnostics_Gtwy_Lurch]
BO_ 2680225668 TFX_PowerManagement: 8 Vector__XXX
 SG_ Power_WakeupSense : 27|1@0+ (1,0) [0|0] "" Vector__XXX
 SG_ Power_Wakeup : 23|4@0+ (1,0) [0|0] "" Vector__XXX
 SG_ Power_SystemCmd : 26|3@0+ (1,0) [0|0] "" Vector__XXX
 SG_ Power_State : 19|4@0+ (1,0) [0|0] "" Vector__XXX
 SG_ IndustryGroup : 13|3@1+ (1,0) [0|0] "" Vector__XXX
 SG_ TFX_Header : 0|11@1+ (1,0) [0|0] "" Vector__XXX

BO_ 2680225719 TFX_Diag_i7700RotSnrPoc_3: 8 Vector__XXX
 SG_ HFSR : 32|32@1+ (1,0) [0|0] "" Vector__XXX
 SG_ CFSR : 0|32@1+ (1,0) [0|0] "" Vector__XXX

BO_ 2680225718 TFX_Diag_i7700RotSnrPoc_2: 8 Vector__XXX
 SG_ ThrottleSnr2_MR_Combined : 48|16@1+ (0.01,0) [0|0] "°" Vector__XXX
 SG_ ThrottleSnr2_MR_Ch3_adc : 32|16@1+ (1,0) [0|0] "adc" Vector__XXX
 SG_ ThrottleSnr2_MR_Ch1_adc : 0|16@1+ (1,0) [0|0] "adc" Vector__XXX
 SG_ ThrottleSnr2_MR_Ch2_adc : 16|16@1+ (1,0) [0|0] "adc" Vector__XXX

BO_ 2680225717 TFX_Diag_i7700RotSnrPoc_1: 8 Vector__XXX
 SG_ ThrottleSnr1_MR_Combined : 48|16@1+ (0.01,0) [0|0] "°" Vector__XXX
 SG_ ThrottleSnr1_MR_Ch3_adc : 32|16@1+ (1,0) [0|0] "adc" Vector__XXX
 SG_ ThrottleSnr1_MR_Ch2_adc : 16|16@1+ (1,0) [0|0] "adc" Vector__XXX
 SG_ ThrottleSnr1_MR_Ch1_adc : 0|16@1+ (1,0) [0|0] "adc" Vector__XXX

BO_ 2680225723 SSS_Combined_Heading: 8 Vector__XXX
 SG_ IndustryGroup : 13|3@1+ (1,0) [0|0] "" Vector__XXX
 SG_ ManufacturerCode : 0|11@1+ (1,0) [0|0] "" Vector__XXX
 SG_ SSS_SensorHeading : 32|16@1+ (0.00573,0) [0|0] "deg" Vector__XXX
 SG_ SSS_ReferenceHeading : 16|16@1+ (0.00573,0) [0|0] "deg" Vector__XXX

BO_ 2147610899 VesselRateOfTurn: 8 Vector__XXX
 SG_ Rate_Of_Turn : 8|32@1- (3.125E-008,0) [-67|67] "rad/s" Vector__XXX
 SG_ SID : 0|8@1+ (1,0) [0|252] "" Vector__XXX

BO_ 2147512832 RateOfTurn: 8 Vector__XXX
 SG_ SequenceID : 0|8@1+ (1,0) [0|252] "" Vector__XXX
 SG_ Rate_Of_Turn : 8|32@1- (3.125E-008,0) [-67|67] "rad/s" Vector__XXX

BO_ 2680225721 TFX_Helm_Configuration: 8 Vector__XXX
 SG_ IndustryGroup : 13|3@1+ (1,0) [0|0] "" Vector__XXX
 SG_ ManufacturerCode : 0|11@1+ (1,0) [0|0] "" Vector__XXX
 SG_ Helm_Steering_resistance : 32|8@1- (1,0) [0|0] "" Vector__XXX
 SG_ Number_of_turns : 24|8@1- (0.1,0) [0|0] "" Vector__XXX
 SG_ Sync_Helm : 16|2@1- (1,0) [0|0] "" Vector__XXX

BO_ 2680225712 TFX_Diagnostics_Gtwy_Lurch: 8 Vector__XXX
 SG_ GwStbdPowerOn : 9|1@1+ (1,0) [0|0] "" Vector__XXX
 SG_ GwStbdActive : 1|1@1+ (1,0) [0|0] "" Vector__XXX
 SG_ GwSCtrPowerOn : 11|1@1+ (1,0) [0|0] "" Vector__XXX
 SG_ GwSCtrAlert : 7|1@1+ (1,0) [0|0] "" Vector__XXX
 SG_ GwSCtrActive : 3|1@1+ (1,0) [0|0] "" Vector__XXX
 SG_ GwPortActive : 0|1@1+ (1,0) [0|0] "" Vector__XXX
 SG_ GwPCtrPowerOn : 10|1@1+ (1,0) [0|0] "" Vector__XXX
 SG_ GwPCtrAlert : 6|1@1+ (1,0) [0|0] "" Vector__XXX
 SG_ GwPCtrActive : 2|1@1+ (1,0) [0|0] "" Vector__XXX
 SG_ PortDACSetpoint : 32|16@1+ (0.0012207,0) [0.6|5] "V" Vector__XXX
 SG_ StbdDACSetpoint : 48|16@1+ (0.0012207,0) [0.6|5] "V" Vector__XXX
 SG_ SignalRelayOut : 24|8@1+ (1,0) [0|0] "" Vector__XXX
 SG_ GwStbdAlert : 5|1@1+ (1,0) [0|0] "" Vector__XXX
 SG_ GwPortPowerOn : 8|1@1+ (1,0) [0|0] "" Vector__XXX
 SG_ GwPortAlert : 4|1@1+ (1,0) [0|0] "" Vector__XXX

BO_ 2147611132 EngineParametersRapidUpdate_SCtr: 8 Vector__XXX
 SG_ EngineTiltTrim : 40|8@1- (1,0) [0|0] "%" Vector__XXX
 SG_ EngineBoostPressure : 24|16@1+ (100,0) [0|6553200] "Pa" Vector__XXX
 SG_ RPM_SCtr : 8|16@1+ (0.25,0) [0|16383] "RPM" Vector__XXX
 SG_ EngineInstance : 0|8@1+ (1,0) [0|255] "" Vector__XXX

BO_ 2147611133 EngineParametersRapidUpdate_PCtr: 8 Vector__XXX
 SG_ RPM_PCtr : 8|16@1+ (0.25,0) [0|16383] "RPM" Vector__XXX
 SG_ EngineTiltTrim : 40|8@1- (1,0) [0|0] "%" Vector__XXX
 SG_ EngineBoostPressure : 24|16@1+ (100,0) [0|6553200] "Pa" Vector__XXX
 SG_ EngineInstance : 0|8@1+ (1,0) [0|255] "" Vector__XXX

BO_ 2680225675 TFX_Diagnostics_VC_SetPt_Thrust: 8 Vector__XXX
 SG_ TFX_VC_Thrust_SCtr : 48|16@1+ (0.01,0) [0|100] "%" Vector__XXX
 SG_ TFX_VC_Thrust_PCtr : 32|16@1+ (0.01,0) [0|100] "%" Vector__XXX
 SG_ TFX_VC_Thrust_Stbd : 16|16@1+ (0.01,0) [0|100] "%" Vector__XXX
 SG_ TFX_VC_Thrust_Port : 0|16@1+ (0.01,0) [0|100] "%" Vector__XXX

BO_ 2680225711 TFX_Diagnostics_Gtwy_ECM_Stbd: 8 Vector__XXX
 SG_ LPS_Port2_Error : 16|16@1+ (0.001220703125,0) [0|0] "V" Vector__XXX
 SG_ LPS_Port1_Error : 0|16@1+ (0.001220703125,0) [0|0] "V" Vector__XXX
 SG_ LPS_ECM_Stbd_3 : 48|16@1+ (0.001220703125,0) [0|0] "V" Vector__XXX
 SG_ LPS_ECM_Stbd_2 : 32|16@1+ (0.001220703125,0) [0|0] "V" Vector__XXX

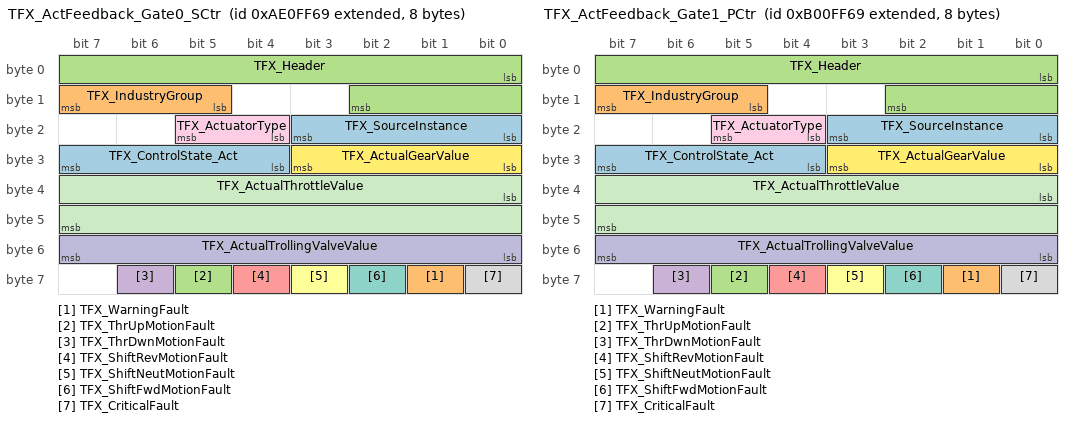
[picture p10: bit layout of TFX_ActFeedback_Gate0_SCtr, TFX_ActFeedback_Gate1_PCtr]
BO_ 2330001257 TFX_ActFeedback_Gate0_SCtr: 8 Vector__XXX
 SG_ TFX_ControlState_Act : 28|4@1+ (1,0) [0|0] "" Vector__XXX
 SG_ TFX_WarningFault : 57|1@1+ (1,0) [0|0] "" Vector__XXX
 SG_ TFX_ThrUpMotionFault : 61|1@1+ (1,0) [0|0] "" Vector__XXX
 SG_ TFX_ThrDwnMotionFault : 62|1@1+ (1,0) [0|0] "" Vector__XXX
 SG_ TFX_ShiftRevMotionFault : 60|1@1+ (1,0) [0|0] "" Vector__XXX
 SG_ TFX_ShiftNeutMotionFault : 59|1@1+ (1,0) [0|0] "" Vector__XXX
 SG_ TFX_ShiftFwdMotionFault : 58|1@1+ (1,0) [0|0] "" Vector__XXX
 SG_ TFX_CriticalFault : 56|1@1+ (1,0) [0|0] "" Vector__XXX
 SG_ TFX_ActuatorType : 20|2@1+ (1,0) [0|3] "" Vector__XXX
 SG_ TFX_ActualTrollingValveValue : 48|8@1+ (1,0) [0|100] "%" Vector__XXX
 SG_ TFX_ActualThrottleValue : 32|16@1+ (0.1,0) [0|100] "%" Vector__XXX
 SG_ TFX_ActualGearValue : 24|4@1- (1,0) [0|0] "" Vector__XXX
 SG_ TFX_SourceInstance : 16|4@1+ (1,0) [0|0] "" Vector__XXX
 SG_ TFX_IndustryGroup : 13|3@1+ (1,0) [0|0] "" Vector__XXX
 SG_ TFX_Header : 0|11@1+ (1,0) [0|2047] "" Vector__XXX

BO_ 2332098409 TFX_ActFeedback_Gate1_PCtr: 8 Vector__XXX
 SG_ TFX_ControlState_Act : 28|4@1+ (1,0) [0|0] "" Vector__XXX
 SG_ TFX_WarningFault : 57|1@1+ (1,0) [0|0] "" Vector__XXX
 SG_ TFX_ThrUpMotionFault : 61|1@1+ (1,0) [0|0] "" Vector__XXX
 SG_ TFX_ThrDwnMotionFault : 62|1@1+ (1,0) [0|0] "" Vector__XXX
 SG_ TFX_ShiftRevMotionFault : 60|1@1+ (1,0) [0|0] "" Vector__XXX
 SG_ TFX_ShiftNeutMotionFault : 59|1@1+ (1,0) [0|0] "" Vector__XXX
 SG_ TFX_ShiftFwdMotionFault : 58|1@1+ (1,0) [0|0] "" Vector__XXX
 SG_ TFX_CriticalFault : 56|1@1+ (1,0) [0|0] "" Vector__XXX
 SG_ TFX_ActuatorType : 20|2@1+ (1,0) [0|3] "" Vector__XXX
 SG_ TFX_ActualTrollingValveValue : 48|8@1+ (1,0) [0|100] "%" Vector__XXX
 SG_ TFX_ActualThrottleValue : 32|16@1+ (0.1,0) [0|100] "%" Vector__XXX
 SG_ TFX_ActualGearValue : 24|4@1- (1,0) [0|0] "" Vector__XXX
 SG_ TFX_SourceInstance : 16|4@1+ (1,0) [0|0] "" Vector__XXX
 SG_ TFX_IndustryGroup : 13|3@1+ (1,0) [0|0] "" Vector__XXX
 SG_ TFX_Header : 0|11@1+ (1,0) [0|2047] "" Vector__XXX

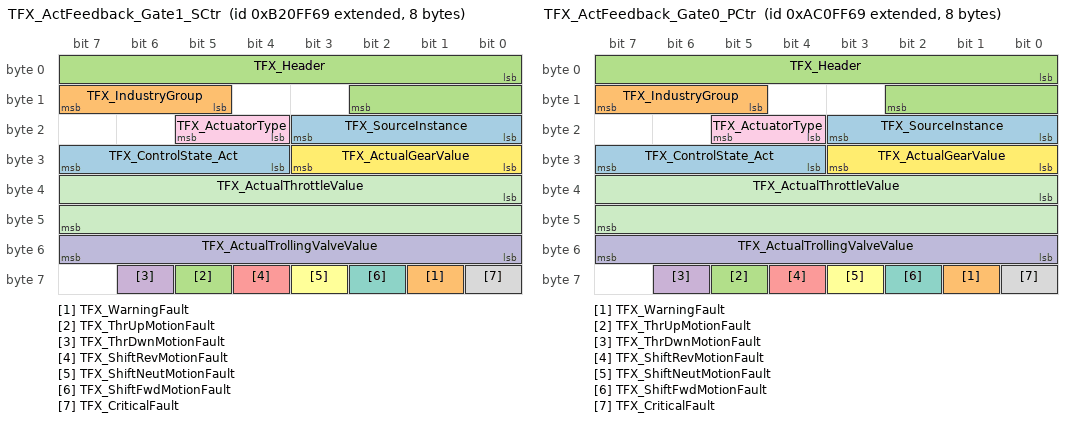
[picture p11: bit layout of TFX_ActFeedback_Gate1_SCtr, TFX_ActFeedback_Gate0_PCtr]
BO_ 2334195561 TFX_ActFeedback_Gate1_SCtr: 8 Vector__XXX
 SG_ TFX_ControlState_Act : 28|4@1+ (1,0) [0|0] "" Vector__XXX
 SG_ TFX_WarningFault : 57|1@1+ (1,0) [0|0] "" Vector__XXX
 SG_ TFX_ThrUpMotionFault : 61|1@1+ (1,0) [0|0] "" Vector__XXX
 SG_ TFX_ThrDwnMotionFault : 62|1@1+ (1,0) [0|0] "" Vector__XXX
 SG_ TFX_ShiftRevMotionFault : 60|1@1+ (1,0) [0|0] "" Vector__XXX
 SG_ TFX_ShiftNeutMotionFault : 59|1@1+ (1,0) [0|0] "" Vector__XXX
 SG_ TFX_ShiftFwdMotionFault : 58|1@1+ (1,0) [0|0] "" Vector__XXX
 SG_ TFX_CriticalFault : 56|1@1+ (1,0) [0|0] "" Vector__XXX
 SG_ TFX_ActuatorType : 20|2@1+ (1,0) [0|3] "" Vector__XXX
 SG_ TFX_ActualTrollingValveValue : 48|8@1+ (1,0) [0|100] "%" Vector__XXX
 SG_ TFX_ActualThrottleValue : 32|16@1+ (0.1,0) [0|100] "%" Vector__XXX
 SG_ TFX_ActualGearValue : 24|4@1- (1,0) [0|0] "" Vector__XXX
 SG_ TFX_SourceInstance : 16|4@1+ (1,0) [0|0] "" Vector__XXX
 SG_ TFX_IndustryGroup : 13|3@1+ (1,0) [0|0] "" Vector__XXX
 SG_ TFX_Header : 0|11@1+ (1,0) [0|2047] "" Vector__XXX

BO_ 2327904105 TFX_ActFeedback_Gate0_PCtr: 8 Vector__XXX
 SG_ TFX_ControlState_Act : 28|4@1+ (1,0) [0|0] "" Vector__XXX
 SG_ TFX_WarningFault : 57|1@1+ (1,0) [0|0] "" Vector__XXX
 SG_ TFX_ThrUpMotionFault : 61|1@1+ (1,0) [0|0] "" Vector__XXX
 SG_ TFX_ThrDwnMotionFault : 62|1@1+ (1,0) [0|0] "" Vector__XXX
 SG_ TFX_ShiftRevMotionFault : 60|1@1+ (1,0) [0|0] "" Vector__XXX
 SG_ TFX_ShiftNeutMotionFault : 59|1@1+ (1,0) [0|0] "" Vector__XXX
 SG_ TFX_ShiftFwdMotionFault : 58|1@1+ (1,0) [0|0] "" Vector__XXX
 SG_ TFX_CriticalFault : 56|1@1+ (1,0) [0|0] "" Vector__XXX
 SG_ TFX_ActuatorType : 20|2@1+ (1,0) [0|3] "" Vector__XXX
 SG_ TFX_ActualTrollingValveValue : 48|8@1+ (1,0) [0|100] "%" Vector__XXX
 SG_ TFX_ActualThrottleValue : 32|16@1+ (0.1,0) [0|100] "%" Vector__XXX
 SG_ TFX_ActualGearValue : 24|4@1- (1,0) [0|0] "" Vector__XXX
 SG_ TFX_SourceInstance : 16|4@1+ (1,0) [0|0] "" Vector__XXX
 SG_ TFX_IndustryGroup : 13|3@1+ (1,0) [0|0] "" Vector__XXX
 SG_ TFX_Header : 0|11@1+ (1,0) [0|2047] "" Vector__XXX

BO_ 2680225709 TFX_Diagnostics_Gtwy_Stbd: 8 Vector__XXX
 SG_ LPS_Sender_SCtr_1 : 48|16@1+ (0.001220703125,0) [0|0] "V" Vector__XXX
 SG_ LPS_Sender_Stbd_2 : 32|16@1+ (0.001220703125,0) [0|0] "V" Vector__XXX
 SG_ LPS_Sender_Stbd_1 : 16|16@1+ (0.001220703125,0) [0|0] "V" Vector__XXX
 SG_ LPS_Cmd_Stbd : 0|16@1- (0.1,0) [0|0] "%" Vector__XXX

BO_ 2680225708 TFX_Diagnostics_Gtwy_Port: 8 Vector__XXX
 SG_ LPS_Sender_Port_2 : 32|16@1+ (0.001220703125,0) [0|0] "V" Vector__XXX
 SG_ LPS_Sender_Port_1 : 16|16@1+ (0.001220703125,0) [0|0] "V" Vector__XXX
 SG_ LPS_Sender_PCtr_1 : 48|16@1+ (0.001220703125,0) [0|0] "V" Vector__XXX
 SG_ LPS_Cmd_Port : 0|16@1- (0.1,0) [0|0] "%" Vector__XXX

BO_ 2147611135 EngineParametersRapidUpdate_Stbd: 8 Vector__XXX
 SG_ EngineTiltTrim : 40|8@1- (1,0) [0|0] "%" Vector__XXX
 SG_ EngineBoostPressure : 24|16@1+ (100,0) [0|6553200] "Pa" Vector__XXX
 SG_ RPM_Stbd : 8|16@1+ (0.25,0) [0|16383] "RPM" Vector__XXX
 SG_ EngineInstance : 0|8@1+ (1,0) [0|255] "" Vector__XXX

BO_ 2147611134 EngineParametersRapidUpdate_Port: 8 Vector__XXX
 SG_ RPM_Port : 8|16@1+ (0.25,0) [0|16383] "RPM" Vector__XXX
 SG_ EngineTiltTrim : 40|8@1- (1,0) [0|0] "%" Vector__XXX
 SG_ EngineBoostPressure : 24|16@1+ (100,0) [0|6553200] "Pa" Vector__XXX
 SG_ EngineInstance : 0|8@1+ (1,0) [0|255] "" Vector__XXX

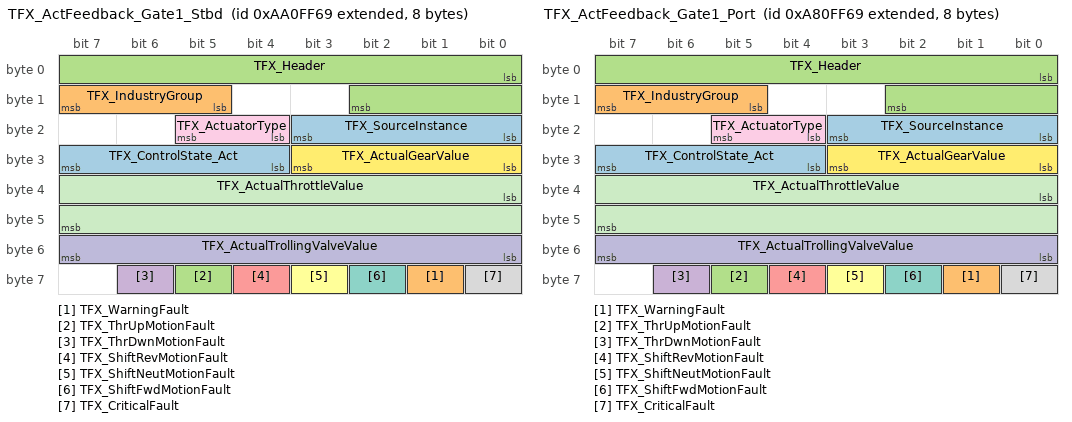
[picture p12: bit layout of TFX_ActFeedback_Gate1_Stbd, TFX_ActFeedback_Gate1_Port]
BO_ 2325806953 TFX_ActFeedback_Gate1_Stbd: 8 Vector__XXX
 SG_ TFX_ControlState_Act : 28|4@1+ (1,0) [0|0] "" Vector__XXX
 SG_ TFX_WarningFault : 57|1@1+ (1,0) [0|0] "" Vector__XXX
 SG_ TFX_ThrUpMotionFault : 61|1@1+ (1,0) [0|0] "" Vector__XXX
 SG_ TFX_ThrDwnMotionFault : 62|1@1+ (1,0) [0|0] "" Vector__XXX
 SG_ TFX_ShiftRevMotionFault : 60|1@1+ (1,0) [0|0] "" Vector__XXX
 SG_ TFX_ShiftNeutMotionFault : 59|1@1+ (1,0) [0|0] "" Vector__XXX
 SG_ TFX_ShiftFwdMotionFault : 58|1@1+ (1,0) [0|0] "" Vector__XXX
 SG_ TFX_CriticalFault : 56|1@1+ (1,0) [0|0] "" Vector__XXX
 SG_ TFX_ActuatorType : 20|2@1+ (1,0) [0|3] "" Vector__XXX
 SG_ TFX_ActualTrollingValveValue : 48|8@1+ (1,0) [0|100] "%" Vector__XXX
 SG_ TFX_ActualThrottleValue : 32|16@1+ (0.1,0) [0|100] "%" Vector__XXX
 SG_ TFX_ActualGearValue : 24|4@1- (1,0) [0|0] "" Vector__XXX
 SG_ TFX_SourceInstance : 16|4@1+ (1,0) [0|0] "" Vector__XXX
 SG_ TFX_IndustryGroup : 13|3@1+ (1,0) [0|0] "" Vector__XXX
 SG_ TFX_Header : 0|11@1+ (1,0) [0|2047] "" Vector__XXX

BO_ 2323709801 TFX_ActFeedback_Gate1_Port: 8 Vector__XXX
 SG_ TFX_ControlState_Act : 28|4@1+ (1,0) [0|0] "" Vector__XXX
 SG_ TFX_WarningFault : 57|1@1+ (1,0) [0|0] "" Vector__XXX
 SG_ TFX_ThrUpMotionFault : 61|1@1+ (1,0) [0|0] "" Vector__XXX
 SG_ TFX_ThrDwnMotionFault : 62|1@1+ (1,0) [0|0] "" Vector__XXX
 SG_ TFX_ShiftRevMotionFault : 60|1@1+ (1,0) [0|0] "" Vector__XXX
 SG_ TFX_ShiftNeutMotionFault : 59|1@1+ (1,0) [0|0] "" Vector__XXX
 SG_ TFX_ShiftFwdMotionFault : 58|1@1+ (1,0) [0|0] "" Vector__XXX
 SG_ TFX_CriticalFault : 56|1@1+ (1,0) [0|0] "" Vector__XXX
 SG_ TFX_ActuatorType : 20|2@1+ (1,0) [0|3] "" Vector__XXX
 SG_ TFX_ActualTrollingValveValue : 48|8@1+ (1,0) [0|100] "%" Vector__XXX
 SG_ TFX_ActualThrottleValue : 32|16@1+ (0.1,0) [0|100] "%" Vector__XXX
 SG_ TFX_ActualGearValue : 24|4@1- (1,0) [0|0] "" Vector__XXX
 SG_ TFX_SourceInstance : 16|4@1+ (1,0) [0|0] "" Vector__XXX
 SG_ TFX_IndustryGroup : 13|3@1+ (1,0) [0|0] "" Vector__XXX
 SG_ TFX_Header : 0|11@1+ (1,0) [0|2047] "" Vector__XXX

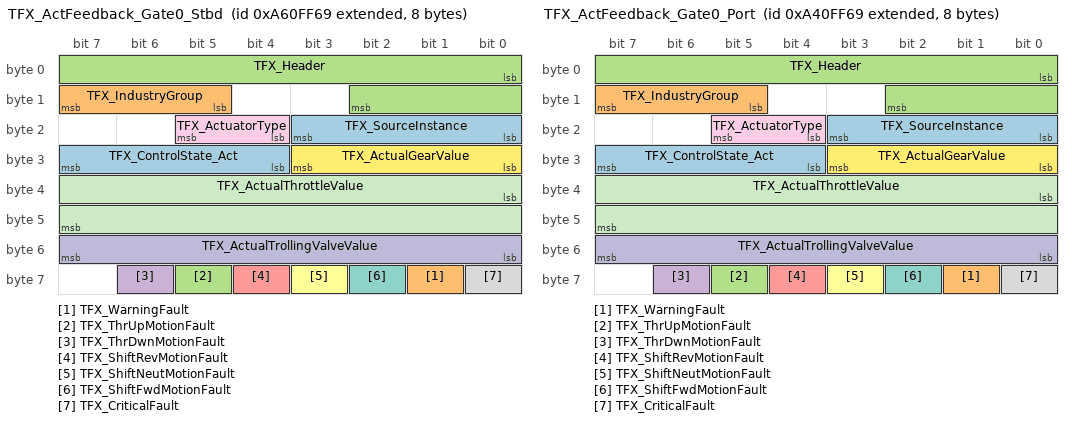
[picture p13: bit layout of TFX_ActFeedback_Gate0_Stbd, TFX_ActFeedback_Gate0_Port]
BO_ 2321612649 TFX_ActFeedback_Gate0_Stbd: 8 Vector__XXX
 SG_ TFX_ControlState_Act : 28|4@1+ (1,0) [0|0] "" Vector__XXX
 SG_ TFX_WarningFault : 57|1@1+ (1,0) [0|0] "" Vector__XXX
 SG_ TFX_ThrUpMotionFault : 61|1@1+ (1,0) [0|0] "" Vector__XXX
 SG_ TFX_ThrDwnMotionFault : 62|1@1+ (1,0) [0|0] "" Vector__XXX
 SG_ TFX_ShiftRevMotionFault : 60|1@1+ (1,0) [0|0] "" Vector__XXX
 SG_ TFX_ShiftNeutMotionFault : 59|1@1+ (1,0) [0|0] "" Vector__XXX
 SG_ TFX_ShiftFwdMotionFault : 58|1@1+ (1,0) [0|0] "" Vector__XXX
 SG_ TFX_CriticalFault : 56|1@1+ (1,0) [0|0] "" Vector__XXX
 SG_ TFX_ActuatorType : 20|2@1+ (1,0) [0|3] "" Vector__XXX
 SG_ TFX_ActualTrollingValveValue : 48|8@1+ (1,0) [0|100] "%" Vector__XXX
 SG_ TFX_ActualThrottleValue : 32|16@1+ (0.1,0) [0|100] "%" Vector__XXX
 SG_ TFX_ActualGearValue : 24|4@1- (1,0) [0|0] "" Vector__XXX
 SG_ TFX_SourceInstance : 16|4@1+ (1,0) [0|0] "" Vector__XXX
 SG_ TFX_IndustryGroup : 13|3@1+ (1,0) [0|0] "" Vector__XXX
 SG_ TFX_Header : 0|11@1+ (1,0) [0|2047] "" Vector__XXX

BO_ 2319515497 TFX_ActFeedback_Gate0_Port: 8 Vector__XXX
 SG_ TFX_ControlState_Act : 28|4@1+ (1,0) [0|0] "" Vector__XXX
 SG_ TFX_WarningFault : 57|1@1+ (1,0) [0|0] "" Vector__XXX
 SG_ TFX_ThrUpMotionFault : 61|1@1+ (1,0) [0|0] "" Vector__XXX
 SG_ TFX_ThrDwnMotionFault : 62|1@1+ (1,0) [0|0] "" Vector__XXX
 SG_ TFX_ShiftRevMotionFault : 60|1@1+ (1,0) [0|0] "" Vector__XXX
 SG_ TFX_ShiftNeutMotionFault : 59|1@1+ (1,0) [0|0] "" Vector__XXX
 SG_ TFX_ShiftFwdMotionFault : 58|1@1+ (1,0) [0|0] "" Vector__XXX
 SG_ TFX_CriticalFault : 56|1@1+ (1,0) [0|0] "" Vector__XXX
 SG_ TFX_ActuatorType : 20|2@1+ (1,0) [0|3] "" Vector__XXX
 SG_ TFX_ActualTrollingValveValue : 48|8@1+ (1,0) [0|100] "%" Vector__XXX
 SG_ TFX_ActualThrottleValue : 32|16@1+ (0.1,0) [0|100] "%" Vector__XXX
 SG_ TFX_ActualGearValue : 24|4@1- (1,0) [0|0] "" Vector__XXX
 SG_ TFX_SourceInstance : 16|4@1+ (1,0) [0|0] "" Vector__XXX
 SG_ TFX_IndustryGroup : 13|3@1+ (1,0) [0|0] "" Vector__XXX
 SG_ TFX_Header : 0|11@1+ (1,0) [0|2047] "" Vector__XXX

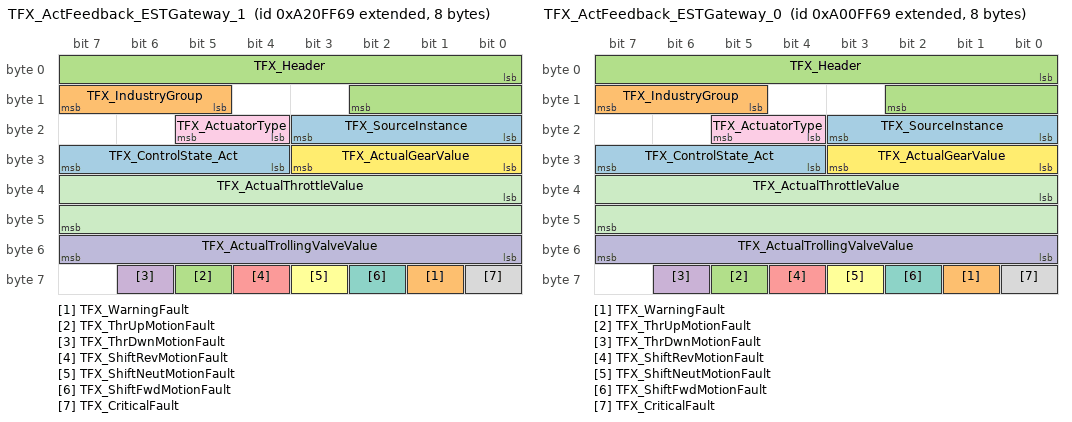
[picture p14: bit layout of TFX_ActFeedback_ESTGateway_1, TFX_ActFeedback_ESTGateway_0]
BO_ 2317418345 TFX_ActFeedback_ESTGateway_1: 8 Vector__XXX
 SG_ TFX_ControlState_Act : 28|4@1+ (1,0) [0|0] "" Vector__XXX
 SG_ TFX_WarningFault : 57|1@1+ (1,0) [0|0] "" Vector__XXX
 SG_ TFX_ThrUpMotionFault : 61|1@1+ (1,0) [0|0] "" Vector__XXX
 SG_ TFX_ThrDwnMotionFault : 62|1@1+ (1,0) [0|0] "" Vector__XXX
 SG_ TFX_ShiftRevMotionFault : 60|1@1+ (1,0) [0|0] "" Vector__XXX
 SG_ TFX_ShiftNeutMotionFault : 59|1@1+ (1,0) [0|0] "" Vector__XXX
 SG_ TFX_ShiftFwdMotionFault : 58|1@1+ (1,0) [0|0] "" Vector__XXX
 SG_ TFX_CriticalFault : 56|1@1+ (1,0) [0|0] "" Vector__XXX
 SG_ TFX_ActuatorType : 20|2@1+ (1,0) [0|3] "" Vector__XXX
 SG_ TFX_ActualTrollingValveValue : 48|8@1+ (1,0) [0|100] "%" Vector__XXX
 SG_ TFX_ActualThrottleValue : 32|16@1+ (0.1,0) [0|100] "%" Vector__XXX
 SG_ TFX_ActualGearValue : 24|4@1- (1,0) [0|0] "" Vector__XXX
 SG_ TFX_SourceInstance : 16|4@1+ (1,0) [0|0] "" Vector__XXX
 SG_ TFX_IndustryGroup : 13|3@1+ (1,0) [0|0] "" Vector__XXX
 SG_ TFX_Header : 0|11@1+ (1,0) [0|2047] "" Vector__XXX

BO_ 2315321193 TFX_ActFeedback_ESTGateway_0: 8 Vector__XXX
 SG_ TFX_ControlState_Act : 28|4@1+ (1,0) [0|0] "" Vector__XXX
 SG_ TFX_WarningFault : 57|1@1+ (1,0) [0|0] "" Vector__XXX
 SG_ TFX_ThrUpMotionFault : 61|1@1+ (1,0) [0|0] "" Vector__XXX
 SG_ TFX_ThrDwnMotionFault : 62|1@1+ (1,0) [0|0] "" Vector__XXX
 SG_ TFX_ShiftRevMotionFault : 60|1@1+ (1,0) [0|0] "" Vector__XXX
 SG_ TFX_ShiftNeutMotionFault : 59|1@1+ (1,0) [0|0] "" Vector__XXX
 SG_ TFX_ShiftFwdMotionFault : 58|1@1+ (1,0) [0|0] "" Vector__XXX
 SG_ TFX_CriticalFault : 56|1@1+ (1,0) [0|0] "" Vector__XXX
 SG_ TFX_ActuatorType : 20|2@1+ (1,0) [0|3] "" Vector__XXX
 SG_ TFX_ActualTrollingValveValue : 48|8@1+ (1,0) [0|100] "%" Vector__XXX
 SG_ TFX_ActualThrottleValue : 32|16@1+ (0.1,0) [0|100] "%" Vector__XXX
 SG_ TFX_ActualGearValue : 24|4@1- (1,0) [0|0] "" Vector__XXX
 SG_ TFX_SourceInstance : 16|4@1+ (1,0) [0|0] "" Vector__XXX
 SG_ TFX_IndustryGroup : 13|3@1+ (1,0) [0|0] "" Vector__XXX
 SG_ TFX_Header : 0|11@1+ (1,0) [0|2047] "" Vector__XXX

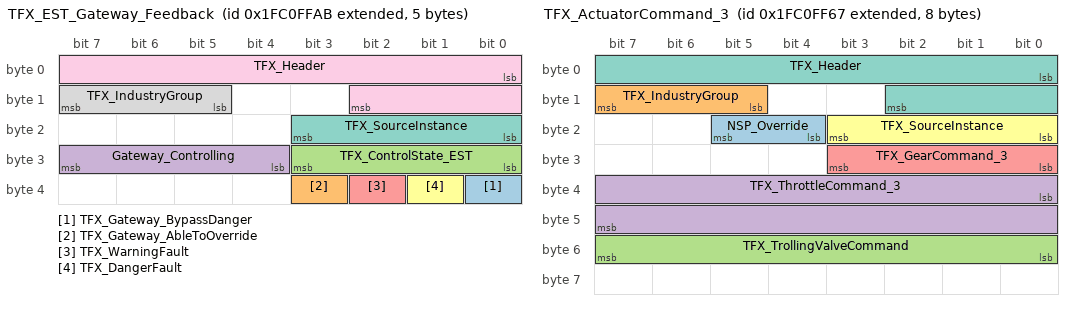
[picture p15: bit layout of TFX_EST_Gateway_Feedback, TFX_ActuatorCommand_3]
BO_ 2680225707 TFX_EST_Gateway_Feedback: 5 Vector__XXX
 SG_ TFX_Gateway_BypassDanger : 32|1@1+ (1,0) [0|0] "" Vector__XXX
 SG_ TFX_Gateway_AbleToOverride : 35|1@1+ (1,0) [0|0] "" Vector__XXX
 SG_ TFX_ControlState_EST : 24|4@1+ (1,0) [0|0] "" Vector__XXX
 SG_ Gateway_Controlling : 28|4@1+ (1,0) [0|15] "" Vector__XXX
 SG_ TFX_WarningFault : 34|1@1+ (1,0) [0|0] "" Vector__XXX
 SG_ TFX_DangerFault : 33|1@1+ (1,0) [0|0] "" Vector__XXX
 SG_ TFX_SourceInstance : 16|4@1+ (1,0) [0|0] "" Vector__XXX
 SG_ TFX_IndustryGroup : 13|3@1+ (1,0) [0|0] "" Vector__XXX
 SG_ TFX_Header : 0|11@1+ (1,0) [0|2047] "" Vector__XXX

BO_ 2680225639 TFX_ActuatorCommand_3: 8 Vector__XXX
 SG_ NSP_Override : 20|2@1+ (1,0) [0|0] "" Vector__XXX
 SG_ TFX_IndustryGroup : 13|3@1+ (1,0) [0|0] "" Vector__XXX
 SG_ TFX_TrollingValveCommand : 48|8@1+ (1,0) [0|0] "%" Vector__XXX
 SG_ TFX_ThrottleCommand_3 : 32|16@1+ (0.1,0) [0|100] "%" Vector__XXX
 SG_ TFX_GearCommand_3 : 24|4@1+ (1,0) [0|2] "" Vector__XXX
 SG_ TFX_SourceInstance : 16|4@1+ (1,0) [0|15] "" Vector__XXX
 SG_ TFX_Header : 0|11@1+ (1,0) [0|2047] "" Vector__XXX

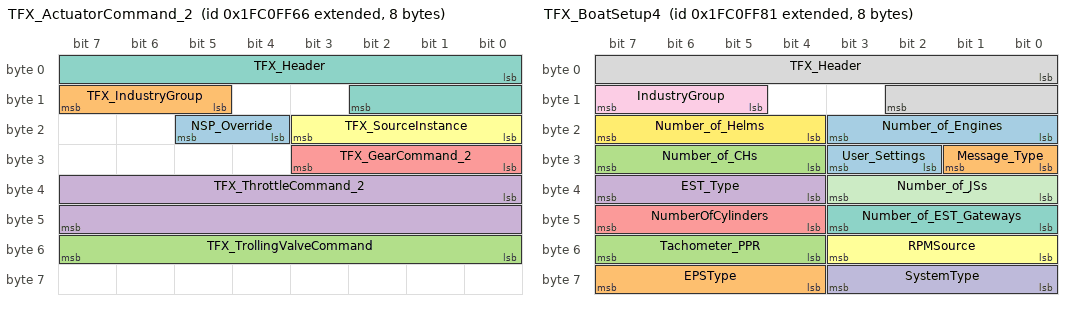
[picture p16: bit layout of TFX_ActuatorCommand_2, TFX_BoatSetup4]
BO_ 2680225638 TFX_ActuatorCommand_2: 8 Vector__XXX
 SG_ NSP_Override : 20|2@1+ (1,0) [0|0] "" Vector__XXX
 SG_ TFX_IndustryGroup : 13|3@1+ (1,0) [0|0] "" Vector__XXX
 SG_ TFX_TrollingValveCommand : 48|8@1+ (1,0) [0|0] "%" Vector__XXX
 SG_ TFX_ThrottleCommand_2 : 32|16@1+ (0.1,0) [0|100] "%" Vector__XXX
 SG_ TFX_GearCommand_2 : 24|4@1+ (1,0) [0|2] "" Vector__XXX
 SG_ TFX_SourceInstance : 16|4@1+ (1,0) [0|15] "" Vector__XXX
 SG_ TFX_Header : 0|11@1+ (1,0) [0|2047] "" Vector__XXX

BO_ 2680225627 TFX_PCMCommand_1: 8 Vector__XXX
 SG_ TFX_CommandType : 20|4@1+ (1,0) [0|0] "" Vector__XXX
 SG_ TFX_IndustryGroup : 13|3@1+ (1,0) [0|0] "" Vector__XXX
 SG_ TFX_StbdRudderCmd : 40|16@1- (0.01,0) [-30|30] "deg" Vector__XXX
 SG_ TFX_PrtRudderCmd : 24|16@1- (0.01,0) [-30|30] "deg" Vector__XXX
 SG_ TFX_SourceInstance : 16|4@1+ (1,0) [0|0] "" Vector__XXX
 SG_ TFX_Header : 0|11@1+ (1,0) [0|0] "" Vector__XXX

BO_ 2680225617 TFX_Helm_Command_1: 8 Vector__XXX
 SG_ TFX_PCM_Command : 16|4@1+ (1,0) [0|0] "" Vector__XXX
 SG_ TFX_Helm_SteeringResistance : 20|12@1+ (0.1,0) [0|0] "%" Vector__XXX
 SG_ TFX_Helm_StbdAngleToBrake : 48|16@1- (0.1,0) [0|0] "°" Vector__XXX
 SG_ TFX_Helm_PortAngleToBrake : 32|16@1- (0.1,0) [0|0] "°" Vector__XXX
 SG_ TFX_IndustryGroup : 13|3@1+ (1,0) [0|0] "" Vector__XXX
 SG_ TFX_Header : 0|11@1+ (1,0) [0|2047] "" Vector__XXX

BO_ 2680225665 TFX_BoatSetup4: 8 Vector__XXX
 SG_ User_Settings : 26|2@1+ (1,0) [0|0] "" Vector__XXX
 SG_ EPSType : 60|4@1+ (1,0) [0|0] "" Vector__XXX
 SG_ Tachometer_PPR : 52|4@1+ (1,0) [0|0] "" Vector__XXX
 SG_ EST_Type : 36|4@1+ (1,0) [0|0] "" Vector__XXX
 SG_ NumberOfCylinders : 44|4@1+ (1,0) [0|0] "" Vector__XXX
 SG_ RPMSource : 48|4@1+ (1,0) [0|0] "" Vector__XXX
 SG_ Number_of_EST_Gateways : 40|4@1+ (1,0) [0|0] "" Vector__XXX
 SG_ TFX_Header : 0|11@1+ (1,0) [0|2047] "" Vector__XXX
 SG_ IndustryGroup : 13|3@1+ (1,0) [0|0] "" Vector__XXX
 SG_ SystemType : 56|4@1+ (1,0) [0|0] "" Vector__XXX
 SG_ Number_of_JSs : 32|4@1+ (1,0) [0|0] "" Vector__XXX
 SG_ Number_of_Helms : 20|4@1+ (1,0) [0|0] "" Vector__XXX
 SG_ Number_of_Engines : 16|4@1+ (1,0) [0|0] "" Vector__XXX
 SG_ Message_Type : 24|2@1+ (1,0) [0|0] "" Vector__XXX
 SG_ Number_of_CHs : 28|4@1+ (1,0) [0|0] "" Vector__XXX

BO_ 2680225787 TFX_RPM_Throttle_Curve_2: 8 Vector__XXX
 SG_ TFX_FilterThr_Stbd_Cmd : 48|16@1+ (0.1,0) [0|100] "%" Vector__XXX
 SG_ TFX_FilterThr_Port_Cmd : 32|16@1+ (0.1,0) [0|100] "%" Vector__XXX
 SG_ TFX_FilterRPM_Stbd : 16|16@1+ (0.25,0) [0|6000] "RPM" Vector__XXX
 SG_ TFX_FilterRPM_Port : 0|16@1+ (0.25,0) [0|6000] "RPM" Vector__XXX

BO_ 2680225666 TFX_SystemParameter: 8 Vector__XXX
 SG_ TFX_IndustryGroup : 13|3@1+ (1,0) [0|0] "" Vector__XXX
 SG_ TFX_Header : 0|11@1+ (1,0) [0|2047] "" Vector__XXX
 SG_ TFX_DashboardIlluminationLevels : 16|8@1+ (1,0) [0|0] "" Vector__XXX

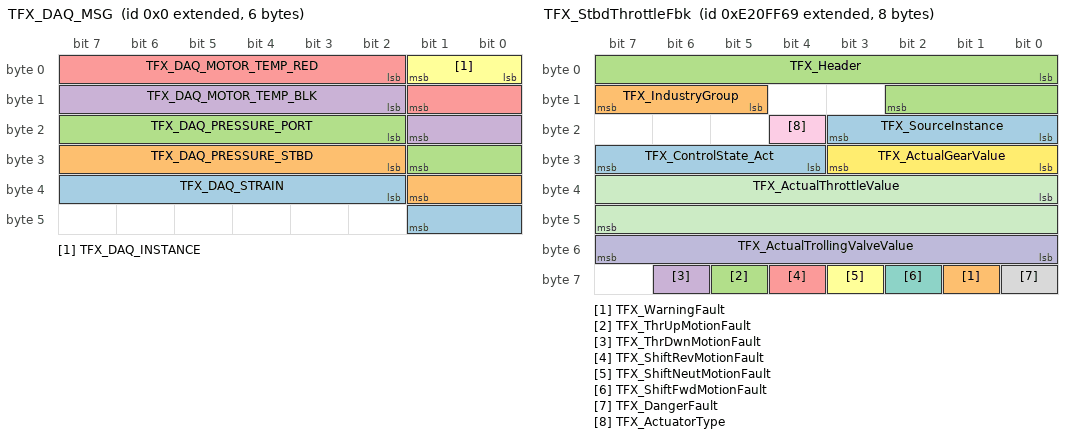
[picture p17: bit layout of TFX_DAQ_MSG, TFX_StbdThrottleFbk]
BO_ 2147483648 TFX_DAQ_MSG: 6 Vector__XXX
 SG_ TFX_DAQ_STRAIN : 34|8@1+ (10,0) [0|2550] "" Vector__XXX
 SG_ TFX_DAQ_PRESSURE_STBD : 26|8@1+ (5,0) [0|1275] "" Vector__XXX
 SG_ TFX_DAQ_PRESSURE_PORT : 18|8@1+ (5,0) [0|1275] "" Vector__XXX
 SG_ TFX_DAQ_MOTOR_TEMP_BLK : 10|8@1+ (1,0) [0|255] "" Vector__XXX
 SG_ TFX_DAQ_MOTOR_TEMP_RED : 2|8@1+ (1,0) [0|255] "" Vector__XXX
 SG_ TFX_DAQ_INSTANCE : 0|2@1+ (1,0) [0|3] "" Vector__XXX

BO_ 2384527209 TFX_StbdThrottleFbk: 8 Vector__XXX
 SG_ TFX_ControlState_Act : 28|4@1+ (1,0) [0|0] "" Vector__XXX
 SG_ TFX_WarningFault : 57|1@1+ (1,0) [0|0] "" Vector__XXX
 SG_ TFX_ThrUpMotionFault : 61|1@1+ (1,0) [0|0] "" Vector__XXX
 SG_ TFX_ThrDwnMotionFault : 62|1@1+ (1,0) [0|0] "" Vector__XXX
 SG_ TFX_ShiftRevMotionFault : 60|1@1+ (1,0) [0|0] "" Vector__XXX
 SG_ TFX_ShiftNeutMotionFault : 59|1@1+ (1,0) [0|0] "" Vector__XXX
 SG_ TFX_ShiftFwdMotionFault : 58|1@1+ (1,0) [0|0] "" Vector__XXX
 SG_ TFX_DangerFault : 56|1@1+ (1,0) [0|0] "" Vector__XXX
 SG_ TFX_ActuatorType : 20|1@1+ (1,0) [0|0] "" Vector__XXX
 SG_ TFX_ActualTrollingValveValue : 48|8@1+ (1,0) [0|100] "%" Vector__XXX
 SG_ TFX_ActualThrottleValue : 32|16@1+ (0.1,0) [0|100] "%" Vector__XXX
 SG_ TFX_ActualGearValue : 24|4@1- (1,0) [0|2] "" Vector__XXX
 SG_ TFX_SourceInstance : 16|4@1+ (1,0) [0|0] "" Vector__XXX
 SG_ TFX_IndustryGroup : 13|3@1+ (1,0) [0|0] "" Vector__XXX
 SG_ TFX_Header : 0|11@1+ (1,0) [0|2047] "" Vector__XXX

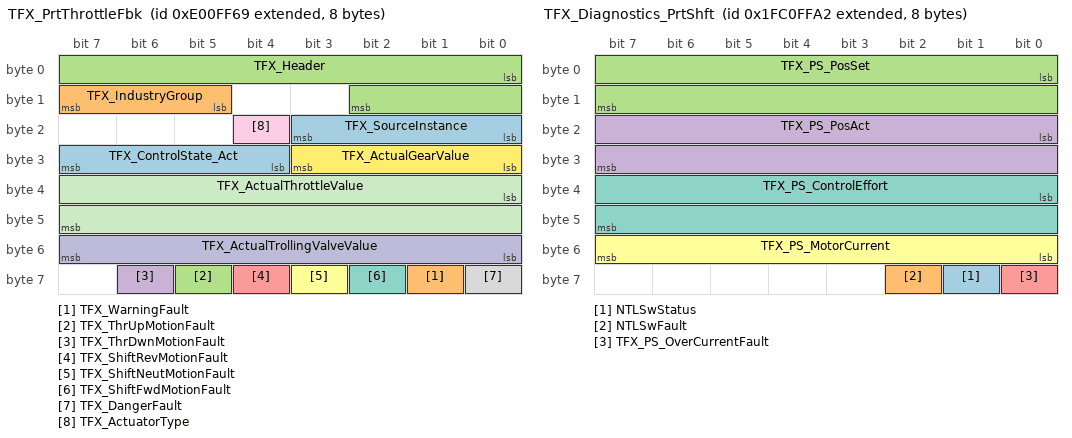
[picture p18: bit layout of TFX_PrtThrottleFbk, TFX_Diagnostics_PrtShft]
BO_ 2382430057 TFX_PrtThrottleFbk: 8 Vector__XXX
 SG_ TFX_ControlState_Act : 28|4@1+ (1,0) [0|0] "" Vector__XXX
 SG_ TFX_WarningFault : 57|1@1+ (1,0) [0|0] "" Vector__XXX
 SG_ TFX_ThrUpMotionFault : 61|1@1+ (1,0) [0|0] "" Vector__XXX
 SG_ TFX_ThrDwnMotionFault : 62|1@1+ (1,0) [0|0] "" Vector__XXX
 SG_ TFX_ShiftRevMotionFault : 60|1@1+ (1,0) [0|0] "" Vector__XXX
 SG_ TFX_ShiftNeutMotionFault : 59|1@1+ (1,0) [0|0] "" Vector__XXX
 SG_ TFX_ShiftFwdMotionFault : 58|1@1+ (1,0) [0|0] "" Vector__XXX
 SG_ TFX_DangerFault : 56|1@1+ (1,0) [0|0] "" Vector__XXX
 SG_ TFX_ActuatorType : 20|1@1+ (1,0) [0|0] "" Vector__XXX
 SG_ TFX_ActualTrollingValveValue : 48|8@1+ (1,0) [0|100] "%" Vector__XXX
 SG_ TFX_ActualThrottleValue : 32|16@1+ (0.1,0) [0|100] "%" Vector__XXX
 SG_ TFX_ActualGearValue : 24|4@1- (1,0) [0|2] "" Vector__XXX
 SG_ TFX_SourceInstance : 16|4@1+ (1,0) [0|0] "" Vector__XXX
 SG_ TFX_IndustryGroup : 13|3@1+ (1,0) [0|0] "" Vector__XXX
 SG_ TFX_Header : 0|11@1+ (1,0) [0|2047] "" Vector__XXX

BO_ 2680225701 TFX_Diagnostics_StbdThr: 8 Vector__XXX
 SG_ TFX_ST_PosSet : 0|16@1+ (0.1,0) [0|100] "mm" Vector__XXX
 SG_ TFX_ST_PosAct : 16|16@1+ (0.1,0) [0|100] "mm" Vector__XXX
 SG_ TFX_ST_OverCurrentFault : 56|1@1+ (1,0) [0|1] "" Vector__XXX
 SG_ TFX_ST_MotorCurrent : 48|8@1+ (0.1,0) [0|25.5] "Amps" Vector__XXX
 SG_ TFX_ST_ControlEffort : 32|16@1- (0.01,0) [-100|100] "%" Vector__XXX

BO_ 2680225700 TFX_Diagnostics_StbdShft: 8 Vector__XXX
 SG_ TFX_SS_PosSet : 0|16@1+ (0.1,0) [0|100] "mm" Vector__XXX
 SG_ TFX_SS_PosAct : 16|16@1+ (0.1,0) [0|100] "mm" Vector__XXX
 SG_ TFX_SS_OverCurrentFault : 56|1@1+ (1,0) [0|1] "" Vector__XXX
 SG_ TFX_SS_MotorCurrent : 48|8@1+ (0.1,0) [0|25.5] "Amps" Vector__XXX
 SG_ TFX_SS_ControlEffort : 32|16@1- (0.01,0) [-100|100] "%" Vector__XXX

BO_ 2680225699 TFX_Diagnostics_PrtThr: 8 Vector__XXX
 SG_ TFX_PT_PosSet : 0|16@1+ (0.1,0) [0|100] "mm" Vector__XXX
 SG_ TFX_PT_PosAct : 16|16@1+ (0.1,0) [0|100] "mm" Vector__XXX
 SG_ TFX_PT_OverCurrentFault : 56|1@1+ (1,0) [0|1] "" Vector__XXX
 SG_ TFX_PT_MotorCurrent : 48|8@1+ (0.1,0) [0|25.5] "Amps" Vector__XXX
 SG_ TFX_PT_ControlEffort : 32|16@1- (0.01,0) [-100|100] "%" Vector__XXX

BO_ 2680225698 TFX_Diagnostics_PrtShft: 8 Vector__XXX
 SG_ NTLSwStatus : 57|1@1+ (1,0) [0|1] "" Vector__XXX
 SG_ NTLSwFault : 58|1@1+ (1,0) [0|0] "" Vector__XXX
 SG_ TFX_PS_PosSet : 0|16@1+ (0.1,0) [0|100] "mm" Vector__XXX
 SG_ TFX_PS_PosAct : 16|16@1+ (0.1,0) [0|100] "mm" Vector__XXX
 SG_ TFX_PS_OverCurrentFault : 56|1@1+ (1,0) [0|1] "" Vector__XXX
 SG_ TFX_PS_MotorCurrent : 48|8@1+ (0.1,0) [0|25.5] "Amps" Vector__XXX
 SG_ TFX_PS_ControlEffort : 32|16@1- (0.01,0) [-100|100] "%" Vector__XXX

BO_ 2680225664 TFX_ShiftActuatorSetup: 8 Vector__XXX
 SG_ TFX_IndustryGroup : 13|3@1+ (1,0) [0|0] "" Vector__XXX
 SG_ TFX_Header : 0|11@1+ (1,0) [0|2047] "" Vector__XXX

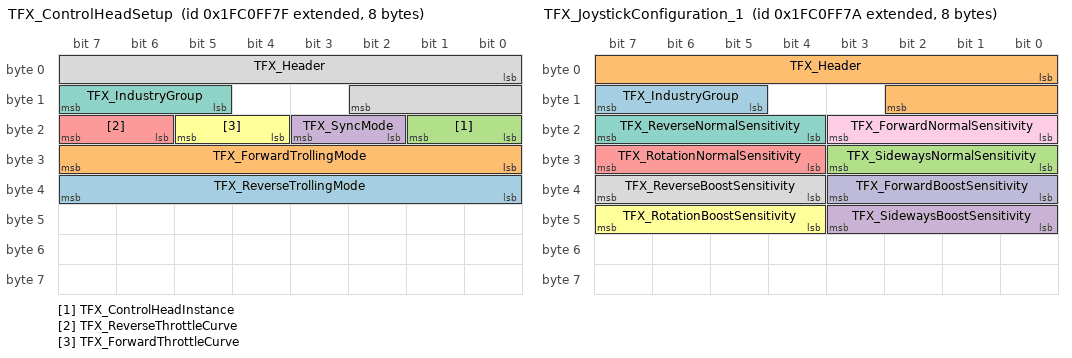
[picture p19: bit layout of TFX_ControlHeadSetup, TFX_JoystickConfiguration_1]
BO_ 2680225663 TFX_ControlHeadSetup: 8 Vector__XXX
 SG_ TFX_ReverseTrollingMode : 32|8@1+ (1,0) [0|0] "%" Vector__XXX
 SG_ TFX_ForwardTrollingMode : 24|8@1+ (1,0) [0|0] "%" Vector__XXX
 SG_ TFX_ControlHeadInstance : 16|2@1+ (1,0) [0|0] "" Vector__XXX
 SG_ TFX_SyncMode : 18|2@1+ (1,0) [0|0] "" Vector__XXX
 SG_ TFX_ReverseThrottleCurve : 22|2@1+ (1,0) [0|3] "" Vector__XXX
 SG_ TFX_ForwardThrottleCurve : 20|2@1+ (1,0) [0|3] "" Vector__XXX
 SG_ TFX_IndustryGroup : 13|3@1+ (1,0) [0|0] "" Vector__XXX
 SG_ TFX_Header : 0|11@1+ (1,0) [0|2047] "" Vector__XXX

BO_ 2680225659 TFX_JoystickConfiguration_2: 8 Vector__XXX
 SG_ TFX_IndustryGroup : 13|3@1+ (1,0) [0|0] "" Vector__XXX
 SG_ TFX_Header : 0|11@1+ (1,0) [0|2047] "" Vector__XXX

BO_ 2680225658 TFX_JoystickConfiguration_1: 8 Vector__XXX
 SG_ TFX_IndustryGroup : 13|3@1+ (1,0) [0|0] "" Vector__XXX
 SG_ TFX_Header : 0|11@1+ (1,0) [0|0] "" Vector__XXX
 SG_ TFX_SidewaysNormalSensitivity : 24|4@1+ (1,0) [0|10] "" Vector__XXX
 SG_ TFX_SidewaysBoostSensitivity : 40|4@1+ (1,0) [0|10] "" Vector__XXX
 SG_ TFX_RotationNormalSensitivity : 28|4@1+ (1,0) [0|10] "" Vector__XXX
 SG_ TFX_RotationBoostSensitivity : 44|4@1+ (1,0) [0|10] "" Vector__XXX
 SG_ TFX_ReverseNormalSensitivity : 20|4@1+ (1,0) [0|10] "" Vector__XXX
 SG_ TFX_ReverseBoostSensitivity : 36|4@1+ (1,0) [0|10] "" Vector__XXX
 SG_ TFX_ForwardNormalSensitivity : 16|4@1+ (1,0) [0|10] "" Vector__XXX
 SG_ TFX_ForwardBoostSensitivity : 32|4@1+ (1,0) [0|10] "" Vector__XXX

BO_ 2680225670 TFX_TrimTiltFbk: 8 Vector__XXX
 SG_ TFX_StbdTrimFbk_PCM : 8|8@1- (1,0) [-128|127] "%" Vector__XXX
 SG_ TFX_StbdTrimFbk_N2K : 24|8@1- (1,0) [-128|127] "%" Vector__XXX
 SG_ TFX_PrtTrimFbk_PCM : 0|8@1- (1,0) [-128|127] "%" Vector__XXX
 SG_ TFX_PrtTrimFbk_N2K : 16|8@1- (1,0) [-128|127] "%" Vector__XXX

BO_ 2680225690 TFX_Diagnostics_Helm_SenAngles: 8 Vector__XXX
 SG_ TFX_Helm_SenMismatch : 32|16@1+ (0.1,0) [0|6553.5] "deg" Vector__XXX
 SG_ TFX_Helm_S2_Angle : 16|16@1- (0.1,0) [-3276.8|3276.7] "deg" Vector__XXX
 SG_ TFX_Helm_S1_Angle : 0|16@1- (0.1,0) [-3276.8|3276.7] "deg" Vector__XXX

BO_ 2680225689 TFX_Diagnostics_Helm_S2Integrity: 8 Vector__XXX
 SG_ TFX_Helm_S2_SumSqurs : 32|32@1- (2.396E-007,0) [-514.53708206|514.53708182] "" Vector__XXX
 SG_ TFX_Helm_S2_sin2Th : 0|16@1- (0.0004895,0) [-16.039936|16.0394465] "" Vector__XXX
 SG_ TFX_Helm_S2_cos2Th : 16|16@1- (0.0004895,0) [-16.039936|16.0394465] "" Vector__XXX

BO_ 2147548874 TFX_DM1: 26 Vector__XXX
 SG_ DM1_SPN_1_High3 : 37|3@1+ (1,0) [0|0] "" Vector__XXX
 SG_ DM1_SPN_6 : 176|19@1+ (1,0) [0|0] "" Vector__XXX
 SG_ DM1_SPN_5 : 144|19@1+ (1,0) [0|0] "" Vector__XXX
 SG_ DM1_SPN_4 : 112|19@1+ (1,0) [0|0] "" Vector__XXX
 SG_ DM1_OccurenceCount_6 : 200|7@1+ (1,0) [0|0] "" Vector__XXX
 SG_ DM1_OccurenceCount_5 : 168|7@1+ (1,0) [0|0] "" Vector__XXX
 SG_ DM1_OccurenceCount_4 : 136|7@1+ (1,0) [0|0] "" Vector__XXX
 SG_ DM1_FMI_6 : 192|5@1+ (1,0) [0|0] "" Vector__XXX
 SG_ DM1_FMI_5 : 160|5@1+ (1,0) [0|0] "" Vector__XXX
 SG_ DM1_FMI_4 : 128|5@1+ (1,0) [0|0] "" Vector__XXX
 SG_ DM1_SPN_3 : 80|19@1+ (1,0) [0|0] "" Vector__XXX
 SG_ DM1_SPN_2 : 48|19@1+ (1,0) [0|0] "" Vector__XXX
 SG_ DM1_OccurenceCount_3 : 104|7@1+ (1,0) [0|0] "" Vector__XXX
 SG_ DM1_OccurenceCount_2 : 72|7@1+ (1,0) [0|0] "" Vector__XXX
 SG_ DM1_FMI_3 : 96|5@1+ (1,0) [0|0] "" Vector__XXX
 SG_ DM1_FMI_2 : 64|5@1+ (1,0) [0|0] "" Vector__XXX
 SG_ DM1_SPN_1_16 : 16|16@1+ (1,0) [0|0] "" Vector__XXX
 SG_ DM1_RedStopLamp : 4|2@1+ (1,0) [0|0] "" Vector__XXX
 SG_ DM1_ProtectLamp : 0|2@1+ (1,0) [0|0] "" Vector__XXX
 SG_ DM1_OccurenceCount_1 : 40|7@1+ (1,0) [0|0] "" Vector__XXX
 SG_ DM1_MalfunctionLamp : 6|2@1+ (1,0) [0|0] "" Vector__XXX
 SG_ DM1_FMI_1 : 32|5@1+ (1,0) [0|0] "" Vector__XXX
 SG_ DM1_ConversionMethod : 47|1@1+ (1,0) [0|0] "" Vector__XXX
 SG_ DM1_AmberWarningLamp : 2|2@1+ (1,0) [0|0] "" Vector__XXX

BO_ 2680221694 TFX_ProprietaryA: 8 Vector__XXX

BO_ 2680225662 TFX_BoatSetup3: 8 Vector__XXX
 SG_ TFX_MaxSteeringAngle : 32|16@1+ (0.01,0) [0|0] "deg" Vector__XXX
 SG_ TFX_EngineCollisionAngle : 16|16@1+ (0.01,0) [0|0] "deg" Vector__XXX
 SG_ TFX_IndustryGroup : 13|3@1+ (1,0) [0|0] "" Vector__XXX
 SG_ TFX_Header : 0|11@1+ (1,0) [0|2047] "" Vector__XXX

BO_ 2680225661 TFX_BoatSetup2: 8 Vector__XXX
 SG_ TFX_LowEngineThrottle : 56|8@1+ (1,0) [0|0] "%" Vector__XXX
 SG_ TFX_LowEngineRPM : 32|16@1+ (0.25,0) [0|0] "RPM" Vector__XXX
 SG_ TFX_HighEngineThrottle : 48|8@1+ (1,0) [0|255] "%" Vector__XXX
 SG_ TFX_HighEngineRPM : 16|16@1+ (0.25,0) [0|0] "RPM" Vector__XXX
 SG_ TFX_IndustryGroup : 13|3@1+ (1,0) [0|0] "" Vector__XXX
 SG_ TFX_Header : 0|11@1+ (1,0) [0|2047] "" Vector__XXX

BO_ 2680225660 TFX_BoatSetup1: 8 Vector__XXX
 SG_ HelmHardstopType : 16|2@1+ (1,0) [0|0] "" Vector__XXX
 SG_ TFX_IndustryGroup : 13|3@1+ (1,0) [0|0] "" Vector__XXX
 SG_ TFX_Header : 0|11@1+ (1,0) [0|2047] "" Vector__XXX

BO_ 2680225650 TFX_CANtrakFeedback: 8 Vector__XXX
 SG_ TFX_ToolCmd : 32|8@1+ (1,0) [0|0] "" Vector__XXX
 SG_ TFX_UserStatus : 28|4@1- (1,0) [0|0] "" Vector__XXX
 SG_ TFX_UserCommand : 24|4@1+ (1,0) [0|0] "" Vector__XXX
 SG_ TFX_SourceInstance : 16|4@1+ (1,0) [0|0] "" Vector__XXX
 SG_ TFX_IndustryGroup : 13|3@1+ (1,0) [0|0] "" Vector__XXX
 SG_ TFX_Header : 0|11@1+ (1,0) [0|2047] "" Vector__XXX

BO_ 2680225685 TFX_Diagnostics_PCM_PWMControl: 8 Vector__XXX
 SG_ TFX_PCM_SetpointDelta : 16|16@1- (0.01,0) [0|60] "deg" Vector__XXX
 SG_ TFX_PCM_PTerm : 32|16@1- (0.01,0) [0|100] "%" Vector__XXX
 SG_ TFX_PCM_FFTerm : 48|16@1- (0.01,0) [0|100] "%" Vector__XXX
 SG_ TFX_PCM_Error : 0|16@1- (0.01,0) [0|60] "deg" Vector__XXX

BO_ 2680225702 TFX_DAQ_Thermocouples: 8 Vector__XXX
 SG_ TFX_DAQ_T3 : 48|16@1- (0.1,0) [-1000|1000] "degC" Vector__XXX
 SG_ TFX_DAQ_T2 : 32|16@1- (0.1,0) [-1000|1000] "degC" Vector__XXX
 SG_ TFX_DAQ_T1 : 16|16@1- (0.1,0) [-1000|1000] "degC" Vector__XXX
 SG_ TFX_DAQ_T0 : 0|16@1- (0.1,0) [-1000|1000] "degC" Vector__XXX

BO_ 2680225704 TFX_DAQ_AnalogVoltages: 8 Vector__XXX
 SG_ TFX_DAQ_V3 : 48|16@1- (0.001,0) [-10|10] "V" Vector__XXX
 SG_ TFX_DAQ_V2 : 32|16@1- (0.001,0) [-10|10] "V" Vector__XXX
 SG_ TFX_DAQ_V1 : 16|16@1- (0.001,0) [-10|10] "V" Vector__XXX
 SG_ TFX_DAQ_V0 : 0|16@1- (0.001,0) [-10|10] "V" Vector__XXX

BO_ 2147538944 TFX_Diagnostics_PCM_Tach: 8 Vector__XXX
 SG_ MaxSteeringAngle : 48|16@1- (0.01,0) [0|0] "" Vector__XXX
 SG_ TFX_RPM_NoiseRej_Filter : 32|16@1+ (0.25,0) [0|0] "rpm" Vector__XXX
 SG_ TFX_RPM_NoiseRej : 16|16@1+ (0.25,0) [0|0] "rpm" Vector__XXX
 SG_ TFX_RPM_Raw : 0|16@1+ (0.25,0) [0|0] "rpm" Vector__XXX

BO_ 2680225688 TFX_Diagnostics_Helm_S1Integrity: 8 Vector__XXX
 SG_ TFX_Helm_S1_SumSqurs : 32|32@1- (2.396E-007,0) [-514.53708206|514.53708182] "" Vector__XXX
 SG_ TFX_Helm_S1_sin2Th : 0|16@1- (0.0004895,0) [-16.039936|16.0394465] "" Vector__XXX
 SG_ TFX_Helm_S1_cos2Th : 16|16@1- (0.0004895,0) [-16.039936|16.0394465] "" Vector__XXX

BO_ 2680225684 TFX_Diagnostics_PCM_RFU: 8 Vector__XXX
 SG_ TFX_PCM_StbdRfu2Delay : 48|16@1+ (1,0) [0|0] "us" Vector__XXX
 SG_ TFX_PCM_StbdRfu1Delay : 16|16@1+ (1,0) [0|0] "us" Vector__XXX
 SG_ TFX_PCM_PortRfu2Delay : 32|16@1+ (1,0) [0|0] "us" Vector__XXX
 SG_ TFX_PCM_PortRfu1Delay : 0|16@1+ (1,0) [0|0] "us" Vector__XXX

CM_ BO_ 3221225472 "This is a message for not used signals, created by Vector CANdb++ DBC OLE DB Provider.";
CM_ BO_ 2147548961 "Used to provide the operational state and internal operating parameters of a specific transmission,
indicated by the transmission.";
CM_ SG_ 2147548961 TransmissionGear "Transmission gear";
CM_ SG_ 2147548961 TransmissionInstance "Transmission instance";
CM_ BO_ 2147548960 "Provides data with a high update rate for a specific engine in a single frame message.";
CM_ BO_ 2147610899 "Heading sensor value with a flag for true or magnetic.";
CM_ BO_ 2147611132 "Provides data with a high update rate for a specific engine in a single frame message.";
CM_ BO_ 2147611133 "Provides data with a high update rate for a specific engine in a single frame message.";
CM_ BO_ 2147611135 "Provides data with a high update rate for a specific engine in a single frame message.";
CM_ BO_ 2147611134 "Provides data with a high update rate for a specific engine in a single frame message.";
BA_DEF_ BO_  "J1939PGDp" INT 0 1;
BA_DEF_ BO_  "J1939PGRepetitionType" ENUM  "always","when active","on request";
BA_DEF_ BO_  "J1939PGRepetitionCycle" INT 0 65535;
BA_DEF_  "Specification" STRING ;
BA_DEF_ SG_  "SigType" STRING ;
BA_DEF_  "IsNMEA" INT 0 1;
BA_DEF_ BO_  "J1939PGPrio" INT 0 7;
BA_DEF_ BO_  "J1939PGDest" INT 0 255;
BA_DEF_ BO_  "SingleFrame" INT 0 1;
BA_DEF_DEF_  "J1939PGDp" 0;
BA_DEF_DEF_  "J1939PGRepetitionType" "always";
BA_DEF_DEF_  "J1939PGRepetitionCycle" 1000;
BA_DEF_DEF_  "Specification" "";
BA_DEF_DEF_  "SigType" "";
BA_DEF_DEF_  "IsNMEA" 1;
BA_DEF_DEF_  "J1939PGPrio" 6;
BA_DEF_DEF_  "J1939PGDest" 255;
BA_DEF_DEF_  "SingleFrame" 0;
BA_ "Specification" "NMEA2000 Version 1.000, August 31, 2001";
BA_ "SingleFrame" BO_ 2680225749 1;
BA_ "SingleFrame" BO_ 2680225591 1;
BA_ "SingleFrame" BO_ 2680225590 1;
BA_ "SingleFrame" BO_ 2680225624 1;
BA_ "SingleFrame" BO_ 2680225593 1;
BA_ "SingleFrame" BO_ 2680225592 1;
BA_ "SingleFrame" BO_ 2680225587 1;
BA_ "SingleFrame" BO_ 2680225585 1;
BA_ "SingleFrame" BO_ 2680225623 1;
BA_ "SingleFrame" BO_ 2680225586 1;
BA_ "SingleFrame" BO_ 2680225583 1;
BA_ "SingleFrame" BO_ 2680225584 1;
BA_ "SingleFrame" BO_ 2680225740 1;
BA_ "SingleFrame" BO_ 2680225741 1;
BA_ "SingleFrame" BO_ 2680225667 1;
BA_ "SingleFrame" BO_ 2680225790 1;
BA_ "SingleFrame" BO_ 2680225582 1;
BA_ "SingleFrame" BO_ 2680225581 1;
BA_ "SingleFrame" BO_ 2680225622 1;
BA_ "SingleFrame" BO_ 2680225786 1;
BA_ "SingleFrame" BO_ 2680225785 1;
BA_ "SingleFrame" BO_ 2680225784 1;
BA_ "SingleFrame" BO_ 2680225783 1;
BA_ "SingleFrame" BO_ 2680225782 1;
BA_ "SingleFrame" BO_ 2680225781 1;
BA_ "SingleFrame" BO_ 2680225780 1;
BA_ "SingleFrame" BO_ 2680225779 1;
BA_ "SingleFrame" BO_ 2680225778 1;
BA_ "SingleFrame" BO_ 2680225777 1;
BA_ "J1939PGDp" BO_ 2147548961 1;
BA_ "J1939PGRepetitionCycle" BO_ 2147548961 100;
BA_ "J1939PGPrio" BO_ 2147548961 2;
BA_ "SingleFrame" BO_ 2147548961 1;
BA_ "J1939PGDp" BO_ 2147548960 1;
BA_ "J1939PGPrio" BO_ 2147548960 2;
BA_ "SingleFrame" BO_ 2147548960 1;
BA_ "SingleFrame" BO_ 2680225567 1;
BA_ "J1939PGPrio" BO_ 2680225567 5;
BA_ "SingleFrame" BO_ 2680225566 1;
BA_ "J1939PGPrio" BO_ 2680225566 5;
BA_ "SingleFrame" BO_ 2680225710 1;
BA_ "SingleFrame" BO_ 2680225601 1;
BA_ "SingleFrame" BO_ 2680225596 1;
BA_ "SingleFrame" BO_ 2680225748 1;
BA_ "SingleFrame" BO_ 2680225747 1;
BA_ "SingleFrame" BO_ 2680225746 1;
BA_ "SingleFrame" BO_ 2680225745 1;
BA_ "SingleFrame" BO_ 2680225744 1;
BA_ "SingleFrame" BO_ 2680225692 1;
BA_ "J1939PGPrio" BO_ 2680422144 7;
BA_ "SingleFrame" BO_ 2680225720 1;
BA_ "SingleFrame" BO_ 2680225556 1;
BA_ "J1939PGPrio" BO_ 2680225734 3;
BA_ "SingleFrame" BO_ 2680225734 1;
BA_ "J1939PGPrio" BO_ 2680225733 3;
BA_ "SingleFrame" BO_ 2680225733 1;
BA_ "J1939PGPrio" BO_ 2680225732 3;
BA_ "SingleFrame" BO_ 2680225732 1;
BA_ "J1939PGPrio" BO_ 2680225731 3;
BA_ "SingleFrame" BO_ 2680225731 1;
BA_ "J1939PGPrio" BO_ 2680225730 3;
BA_ "SingleFrame" BO_ 2680225730 1;
BA_ "J1939PGPrio" BO_ 2680225729 3;
BA_ "SingleFrame" BO_ 2680225729 1;
BA_ "J1939PGPrio" BO_ 2680225728 3;
BA_ "SingleFrame" BO_ 2680225728 1;
BA_ "J1939PGPrio" BO_ 2680225727 3;
BA_ "SingleFrame" BO_ 2680225727 1;
BA_ "J1939PGPrio" BO_ 2680225726 3;
BA_ "SingleFrame" BO_ 2680225726 1;
BA_ "J1939PGPrio" BO_ 2680225618 2;
BA_ "SingleFrame" BO_ 2680225618 1;
BA_ "J1939PGPrio" BO_ 2147545092 3;
BA_ "J1939PGPrio" BO_ 2147610906 7;
BA_ "SingleFrame" BO_ 2680225693 1;
BA_ "SingleFrame" BO_ 2680225668 1;
BA_ "SingleFrame" BO_ 2680225719 1;
BA_ "SingleFrame" BO_ 2680225718 1;
BA_ "SingleFrame" BO_ 2680225717 1;
BA_ "J1939PGPrio" BO_ 2680225723 2;
BA_ "J1939PGDp" BO_ 2147610899 1;
BA_ "J1939PGRepetitionCycle" BO_ 2147610899 100;
BA_ "J1939PGPrio" BO_ 2147610899 2;
BA_ "SingleFrame" BO_ 2147610899 1;
BA_ "SingleFrame" BO_ 2680225712 1;
BA_ "J1939PGDp" BO_ 2147611132 1;
BA_ "J1939PGPrio" BO_ 2147611132 2;
BA_ "SingleFrame" BO_ 2147611132 1;
BA_ "J1939PGDp" BO_ 2147611133 1;
BA_ "J1939PGPrio" BO_ 2147611133 2;
BA_ "SingleFrame" BO_ 2147611133 1;
BA_ "SingleFrame" BO_ 2680225675 1;
BA_ "SingleFrame" BO_ 2680225711 1;
BA_ "J1939PGRepetitionCycle" BO_ 2330001257 10;
BA_ "J1939PGPrio" BO_ 2330001257 2;
BA_ "SingleFrame" BO_ 2330001257 1;
BA_ "J1939PGRepetitionCycle" BO_ 2332098409 10;
BA_ "J1939PGPrio" BO_ 2332098409 2;
BA_ "SingleFrame" BO_ 2332098409 1;
BA_ "J1939PGRepetitionCycle" BO_ 2334195561 10;
BA_ "J1939PGPrio" BO_ 2334195561 2;
BA_ "SingleFrame" BO_ 2334195561 1;
BA_ "J1939PGRepetitionCycle" BO_ 2327904105 10;
BA_ "J1939PGPrio" BO_ 2327904105 2;
BA_ "SingleFrame" BO_ 2327904105 1;
BA_ "SingleFrame" BO_ 2680225709 1;
BA_ "SingleFrame" BO_ 2680225708 1;
BA_ "SingleFrame" BO_ 2147611135 1;
BA_ "J1939PGPrio" BO_ 2147611135 2;
BA_ "J1939PGDp" BO_ 2147611135 1;
BA_ "SingleFrame" BO_ 2147611134 1;
BA_ "J1939PGPrio" BO_ 2147611134 2;
BA_ "J1939PGDp" BO_ 2147611134 1;
BA_ "J1939PGRepetitionCycle" BO_ 2325806953 10;
BA_ "J1939PGPrio" BO_ 2325806953 2;
BA_ "SingleFrame" BO_ 2325806953 1;
BA_ "J1939PGRepetitionCycle" BO_ 2323709801 10;
BA_ "J1939PGPrio" BO_ 2323709801 2;
BA_ "SingleFrame" BO_ 2323709801 1;
BA_ "J1939PGRepetitionCycle" BO_ 2321612649 10;
BA_ "J1939PGPrio" BO_ 2321612649 2;
BA_ "SingleFrame" BO_ 2321612649 1;
BA_ "J1939PGRepetitionCycle" BO_ 2319515497 10;
BA_ "J1939PGPrio" BO_ 2319515497 2;
BA_ "SingleFrame" BO_ 2319515497 1;
BA_ "SingleFrame" BO_ 2317418345 1;
BA_ "J1939PGPrio" BO_ 2317418345 2;
BA_ "J1939PGRepetitionCycle" BO_ 2317418345 10;
BA_ "SingleFrame" BO_ 2315321193 1;
BA_ "J1939PGPrio" BO_ 2315321193 2;
BA_ "J1939PGRepetitionCycle" BO_ 2315321193 10;
BA_ "SingleFrame" BO_ 2680225707 1;
BA_ "J1939PGPrio" BO_ 2680225707 5;
BA_ "J1939PGRepetitionCycle" BO_ 2680225639 10;
BA_ "J1939PGPrio" BO_ 2680225639 2;
BA_ "SingleFrame" BO_ 2680225639 1;
BA_ "J1939PGRepetitionCycle" BO_ 2680225638 10;
BA_ "J1939PGPrio" BO_ 2680225638 2;
BA_ "SingleFrame" BO_ 2680225638 1;
BA_ "J1939PGRepetitionCycle" BO_ 2680225627 10;
BA_ "J1939PGPrio" BO_ 2680225627 3;
BA_ "SingleFrame" BO_ 2680225627 1;
BA_ "J1939PGPrio" BO_ 2680225617 2;
BA_ "SingleFrame" BO_ 2680225617 1;
BA_ "SingleFrame" BO_ 2680225665 1;
BA_ "SingleFrame" BO_ 2680225787 1;
BA_ "SingleFrame" BO_ 2680225666 1;
BA_ "SingleFrame" BO_ 2147483648 1;
BA_ "J1939PGRepetitionCycle" BO_ 2384527209 10;
BA_ "J1939PGPrio" BO_ 2384527209 3;
BA_ "SingleFrame" BO_ 2384527209 1;
BA_ "J1939PGRepetitionCycle" BO_ 2382430057 10;
BA_ "J1939PGPrio" BO_ 2382430057 3;
BA_ "SingleFrame" BO_ 2382430057 1;
BA_ "SingleFrame" BO_ 2680225701 1;
BA_ "J1939PGPrio" BO_ 2680225701 3;
BA_ "SingleFrame" BO_ 2680225700 1;
BA_ "J1939PGPrio" BO_ 2680225700 3;
BA_ "SingleFrame" BO_ 2680225699 1;
BA_ "J1939PGPrio" BO_ 2680225699 3;
BA_ "SingleFrame" BO_ 2680225698 1;
BA_ "J1939PGPrio" BO_ 2680225698 3;
BA_ "SingleFrame" BO_ 2680225664 1;
BA_ "SingleFrame" BO_ 2680225663 1;
BA_ "SingleFrame" BO_ 2680225659 1;
BA_ "SingleFrame" BO_ 2680225658 1;
BA_ "SingleFrame" BO_ 2680225670 1;
BA_ "SingleFrame" BO_ 2680225690 1;
BA_ "SingleFrame" BO_ 2680225689 1;
BA_ "SingleFrame" BO_ 2147548874 1;
BA_ "SingleFrame" BO_ 2680221694 1;
BA_ "J1939PGPrio" BO_ 2680221694 7;
BA_ "SingleFrame" BO_ 2680225662 1;
BA_ "SingleFrame" BO_ 2680225661 1;
BA_ "SingleFrame" BO_ 2680225660 1;
BA_ "SingleFrame" BO_ 2680225650 1;
BA_ "SingleFrame" BO_ 2680225685 1;
BA_ "SingleFrame" BO_ 2680225702 1;
BA_ "SingleFrame" BO_ 2680225704 1;
BA_ "SingleFrame" BO_ 2147538944 1;
BA_ "SingleFrame" BO_ 2680225688 1;
BA_ "SingleFrame" BO_ 2680225684 1;
BA_ "SigType" SG_ 3221225472 TotalNumberOfFramestoTransmitRTS "SPECIFIC";
BA_ "SigType" SG_ 3221225472 TotalMessageSizeRTS "SPECIFIC";
BA_ "SigType" SG_ 3221225472 NumberofFramesAllowableforSend "SPECIFIC";
BA_ "SigType" SG_ 3221225472 NumberofNextTransmittedFrame "SPECIFIC";
BA_ "SigType" SG_ 3221225472 TotalMessageSizeModeEOM "SPECIFIC";
BA_ "SigType" SG_ 3221225472 TotalNumberOfFramesReceived "SPECIFIC";
BA_ "SigType" SG_ 3221225472 TotalMessageSizeModeBAM "SPECIFIC";
BA_ "SigType" SG_ 3221225472 TotalNumberFramesTransmitBAM "SPECIFIC";
BA_ "SigType" SG_ 3221225472 SID "SPECIFIC";
BA_ "SigType" SG_ 3221225472 IndustryGroup "SPECIFIC";
BA_ "SigType" SG_ 3221225472 Override "DISCRETE";
BA_ "SigType" SG_ 3221225472 TFX_IndustryGroup "SPECIFIC";
BA_ "SigType" SG_ 3221225472 TFX_RateOfTurn "RANGE";
BA_ "SigType" SG_ 3221225472 TFX_Angle "RANGE";
BA_ "SigType" SG_ 3221225472 EngineSpeed "RANGE";
BA_ "SigType" SG_ 3221225472 Heading "RANGE";
BA_ "SigType" SG_ 3221225472 RPM_Stbd "RANGE";
BA_ "SigType" SG_ 3221225472 RPM_Port "RANGE";
BA_ "SigType" SG_ 3221225472 TFX_StbdRPMFbk_PCM "RANGE";
BA_ "SigType" SG_ 3221225472 TFX_PrtRPMFbk_PCM "RANGE";
BA_ "SigType" SG_ 3221225472 TFX_StbdRPMFbk_N2K "RANGE";
BA_ "SigType" SG_ 3221225472 TFX_PrtRPMFbk_N2K "RANGE";
BA_ "SigType" SG_ 2680225624 TFX_SteeringCmd "RANGE";
BA_ "SigType" SG_ 2680225624 TFX_IndustryGroup "SPECIFIC";
BA_ "SigType" SG_ 2680225586 IndustryGroup "SPECIFIC";
BA_ "SigType" SG_ 2680225586 ManufacturerCode "SPECIFIC";
BA_ "SigType" SG_ 2680225583 IndustryGroup "SPECIFIC";
BA_ "SigType" SG_ 2680225583 ManufacturerCode "SPECIFIC";
BA_ "SigType" SG_ 2680225584 IndustryGroup "SPECIFIC";
BA_ "SigType" SG_ 2680225584 ManufacturerCode "SPECIFIC";
BA_ "SigType" SG_ 2680225740 IndustryGroup "SPECIFIC";
BA_ "SigType" SG_ 2680225740 ManufacturerCode "SPECIFIC";
BA_ "SigType" SG_ 2680225741 IndustryGroup "SPECIFIC";
BA_ "SigType" SG_ 2680225741 ManufacturerCode "SPECIFIC";
BA_ "SigType" SG_ 2680225667 IndustryGroup "SPECIFIC";
BA_ "SigType" SG_ 2680225582 IndustryGroup "SPECIFIC";
BA_ "SigType" SG_ 2680225582 ManufacturerCode "SPECIFIC";
BA_ "SigType" SG_ 2680225581 IndustryGroup "SPECIFIC";
BA_ "SigType" SG_ 2680225581 ManufacturerCode "SPECIFIC";
BA_ "SigType" SG_ 2147548961 SailDrive "DISCRETE";
BA_ "SigType" SG_ 2147548961 LowOilLevel "DISCRETE";
BA_ "SigType" SG_ 2147548961 LowOilPressure "DISCRETE";
BA_ "SigType" SG_ 2147548961 OverTemperature "DISCRETE";
BA_ "SigType" SG_ 2147548961 CheckTransmission "DISCRETE";
BA_ "SigType" SG_ 2147548961 TransOilTemperature "RANGE";
BA_ "SigType" SG_ 2147548961 TransOilPressure "RANGE";
BA_ "SigType" SG_ 2147548961 TransmissionGear "DISCRETE";
BA_ "SigType" SG_ 2147548961 TransmissionInstance "DISCRETE";
BA_ "SigType" SG_ 2147548960 EngineBoostPressure "RANGE";
BA_ "SigType" SG_ 2147548960 EngineSpeed "RANGE";
BA_ "SigType" SG_ 2147548960 EngineInstance "DISCRETE";
BA_ "SigType" SG_ 2680225567 TFX_IndustryGroup "SPECIFIC";
BA_ "SigType" SG_ 2680225566 TFX_IndustryGroup "SPECIFIC";
BA_ "SigType" SG_ 2680225601 IndustryGroup "SPECIFIC";
BA_ "SigType" SG_ 2680225601 ManufacturerCode "SPECIFIC";
BA_ "SigType" SG_ 2680225596 IndustryGroup "SPECIFIC";
BA_ "SigType" SG_ 2680225596 ManufacturerCode "SPECIFIC";
BA_ "SigType" SG_ 2680225556 EngineOilPressure "RANGE";
BA_ "SigType" SG_ 2680225734 ASK_T_P "RANGE";
BA_ "SigType" SG_ 2680225734 ASK_T_I "RANGE";
BA_ "SigType" SG_ 2680225734 ASK_T_D "RANGE";
BA_ "SigType" SG_ 2680225733 ASK_Y_P "RANGE";
BA_ "SigType" SG_ 2680225733 ASK_Y_I "RANGE";
BA_ "SigType" SG_ 2680225733 ASK_Y_D "RANGE";
BA_ "SigType" SG_ 2680225732 ASK_X_P "RANGE";
BA_ "SigType" SG_ 2680225732 ASK_X_I "RANGE";
BA_ "SigType" SG_ 2680225732 ASK_X_D "RANGE";
BA_ "SigType" SG_ 2680225731 ASK_Yerr "RANGE";
BA_ "SigType" SG_ 2680225731 ASK_Xerr "RANGE";
BA_ "SigType" SG_ 2680225731 ASK_Terr "RANGE";
BA_ "SigType" SG_ 2680225730 ASK_Ycmd "RANGE";
BA_ "SigType" SG_ 2680225730 ASK_Xcmd "RANGE";
BA_ "SigType" SG_ 2680225730 ASK_Tcmd "RANGE";
BA_ "SigType" SG_ 2680225730 ASK_AskZone "RANGE";
BA_ "SigType" SG_ 2680225730 ASK_AskMode "RANGE";
BA_ "SigType" SG_ 2680225729 ASK_LonErrM "RANGE";
BA_ "SigType" SG_ 2680225729 ASK_LonErr "RANGE";
BA_ "SigType" SG_ 2680225729 ASK_LatErrM "RANGE";
BA_ "SigType" SG_ 2680225729 ASK_LatErr "RANGE";
BA_ "SigType" SG_ 2680225727 ASK_LonFbk "RANGE";
BA_ "SigType" SG_ 2680225727 ASK_LatFbk "RANGE";
BA_ "SigType" SG_ 2680225726 ASK_LonSP "RANGE";
BA_ "SigType" SG_ 2680225726 ASK_LatSP "RANGE";
BA_ "SigType" SG_ 2680225618 TFX_IndustryGroup "SPECIFIC";
BA_ "SigType" SG_ 2147610906 SequenceID "RANGE";
BA_ "SigType" SG_ 2680225723 IndustryGroup "SPECIFIC";
BA_ "SigType" SG_ 2680225723 ManufacturerCode "SPECIFIC";
BA_ "SigType" SG_ 2147610899 SID "SPECIFIC";
BA_ "SigType" SG_ 2147512832 SequenceID "RANGE";
BA_ "SigType" SG_ 2680225721 IndustryGroup "SPECIFIC";
BA_ "SigType" SG_ 2680225721 ManufacturerCode "SPECIFIC";
BA_ "SigType" SG_ 2147611132 EngineBoostPressure "RANGE";
BA_ "SigType" SG_ 2147611132 RPM_SCtr "RANGE";
BA_ "SigType" SG_ 2147611132 EngineInstance "DISCRETE";
BA_ "SigType" SG_ 2147611133 RPM_PCtr "RANGE";
BA_ "SigType" SG_ 2147611133 EngineBoostPressure "RANGE";
BA_ "SigType" SG_ 2147611133 EngineInstance "DISCRETE";
BA_ "SigType" SG_ 2330001257 TFX_IndustryGroup "SPECIFIC";
BA_ "SigType" SG_ 2332098409 TFX_IndustryGroup "SPECIFIC";
BA_ "SigType" SG_ 2334195561 TFX_IndustryGroup "SPECIFIC";
BA_ "SigType" SG_ 2327904105 TFX_IndustryGroup "SPECIFIC";
BA_ "SigType" SG_ 2147611135 EngineBoostPressure "RANGE";
BA_ "SigType" SG_ 2147611135 RPM_Stbd "RANGE";
BA_ "SigType" SG_ 2147611135 EngineInstance "DISCRETE";
BA_ "SigType" SG_ 2147611134 RPM_Port "RANGE";
BA_ "SigType" SG_ 2147611134 EngineBoostPressure "RANGE";
BA_ "SigType" SG_ 2147611134 EngineInstance "DISCRETE";
BA_ "SigType" SG_ 2325806953 TFX_IndustryGroup "SPECIFIC";
BA_ "SigType" SG_ 2323709801 TFX_IndustryGroup "SPECIFIC";
BA_ "SigType" SG_ 2321612649 TFX_IndustryGroup "SPECIFIC";
BA_ "SigType" SG_ 2319515497 TFX_IndustryGroup "SPECIFIC";
BA_ "SigType" SG_ 2317418345 TFX_IndustryGroup "SPECIFIC";
BA_ "SigType" SG_ 2315321193 TFX_IndustryGroup "SPECIFIC";
BA_ "SigType" SG_ 2680225707 TFX_IndustryGroup "SPECIFIC";
BA_ "SigType" SG_ 2680225639 TFX_IndustryGroup "SPECIFIC";
BA_ "SigType" SG_ 2680225638 TFX_IndustryGroup "SPECIFIC";
BA_ "SigType" SG_ 2680225627 TFX_IndustryGroup "SPECIFIC";
BA_ "SigType" SG_ 2680225627 TFX_StbdRudderCmd "RANGE";
BA_ "SigType" SG_ 2680225627 TFX_PrtRudderCmd "RANGE";
BA_ "SigType" SG_ 2680225617 TFX_IndustryGroup "SPECIFIC";
BA_ "SigType" SG_ 2680225665 IndustryGroup "SPECIFIC";
BA_ "SigType" SG_ 2384527209 TFX_IndustryGroup "SPECIFIC";
BA_ "SigType" SG_ 2382430057 TFX_IndustryGroup "SPECIFIC";
BA_ "SigType" SG_ 2680225664 TFX_IndustryGroup "SPECIFIC";
BA_ "SigType" SG_ 2680225663 TFX_IndustryGroup "SPECIFIC";
BA_ "SigType" SG_ 2680225659 TFX_IndustryGroup "SPECIFIC";
BA_ "SigType" SG_ 2680225658 TFX_IndustryGroup "SPECIFIC";
BA_ "SigType" SG_ 2680225670 TFX_StbdTrimFbk_PCM "RANGE";
BA_ "SigType" SG_ 2680225670 TFX_StbdTrimFbk_N2K "RANGE";
BA_ "SigType" SG_ 2680225670 TFX_PrtTrimFbk_PCM "RANGE";
BA_ "SigType" SG_ 2680225670 TFX_PrtTrimFbk_N2K "RANGE";
BA_ "SigType" SG_ 2680225662 TFX_IndustryGroup "SPECIFIC";
BA_ "SigType" SG_ 2680225661 TFX_IndustryGroup "SPECIFIC";
BA_ "SigType" SG_ 2680225660 TFX_IndustryGroup "SPECIFIC";
BA_ "SigType" SG_ 2680225650 TFX_IndustryGroup "SPECIFIC";
BA_ "SigType" SG_ 2147538944 TFX_RPM_NoiseRej_Filter "*";
VAL_ 3221225472 FaultCode 5 "Throttle Up Fault" 4 "Reverse Fault" 3 "Forward Fault" 2 "Neutral Fault" 1 "Danger Fault" 0 "No Fault" ;
VAL_ 3221225472 SourceESMInstance 15 "Not Available" 14 "Error" 2 "Reverse" 1 "Neutral" 0 "Forward" ;
VAL_ 3221225472 TFX_Shift_SyncActive 1 "Active" 0 "Inactive" ;
VAL_ 3221225472 TFX_Shift_Group 5 "Shift" 4 "Throttle" 1 "Command" ;
VAL_ 3221225472 TFX_SCM_DockingActive 1 "Active" 0 "Inactive" ;
VAL_ 3221225472 IndustryGroup 5 "IndustrialProcess" 3 "Construction" 2 "AgriculturalAndForestry" 0 "Global" 1 "OnHighway" 4 "Marine" ;
VAL_ 3221225472 TFX_Shift_Gear 3 "Not Available" 2 "Reverse" 1 "Neutral" 0 "Forward" ;
VAL_ 3221225472 TFX_Shift_TrollValveEngaged 1 "Active" 0 "Inactive" ;
VAL_ 3221225472 TFX_Shift_CriticalFailActive 1 "Active" 0 "Inactive" ;
VAL_ 3221225472 TFX_Shift_WarningActive 1 "Active" 0 "Inactive" ;
VAL_ 3221225472 TFX_Header 1850 "Teleflex" ;
VAL_ 3221225472 TFX_Shift_Instance 1 "Stbd" 0 "Port" ;
VAL_ 3221225472 Override 1 "YES" 0 "NO" ;
VAL_ 3221225472 TFX_SourceInstance 1 "Stbd" 0 "Port" ;
VAL_ 3221225472 TFX_IndustryGroup 5 "IndustrialProcess" 3 "Construction" 2 "AgriculturalAndForestry" 0 "Global" 1 "OnHighway" 4 "Marine" ;
VAL_ 3221225472 TFX_VC_State 10 "Power Down" 9 "Limp Home" 8 "Fault" 7 "Vessel Calibration" 6 "Active" 5 "Pre-Active" 4 "Inactive" 3 "Station Select" 2 "Lamp Test" 1 "Joystick Calibration" 0 "Startup" ;
VAL_ 3221225472 TFX_VC_ControlState 6 "CCW" 5 "CW" 4 "Port" 3 "Reverse" 2 "Starboard" 1 "Forward" 0 "Neutral" ;
VAL_ 3221225472 TFX_JoystickHrtBtLoss_1 1 "Active" 0 "Inactive" ;
VAL_ 3221225472 TFX_JoystickHrtBtLoss_0 1 "Active" 0 "Inactive" ;
VAL_ 3221225472 TFX_HelmSensorFault 1 "Active" 0 "Inactive" ;
VAL_ 3221225472 TFX_HelmPCM_HrtBtLoss 1 "Active" 0 "Inactive" ;
VAL_ 3221225472 TFX_HelmHrtBtLoss_1 1 "Active" 0 "Inactive" ;
VAL_ 3221225472 TFX_HelmHrtBtLoss_0 1 "Active" 0 "Inactive" ;
VAL_ 3221225472 TFX_HelmFTCANwiringProblem 1 "Active" 0 "Inactive" ;
VAL_ 3221225472 TFX_HelmBrakeFault 1 "Active" 0 "Inactive" ;
VAL_ 3221225472 TFX_StbdTempSensorFault 1 "Active" 0 "Inactive" ;
VAL_ 3221225472 TFX_StbdOverTempFault 1 "Active" 0 "Inactive" ;
VAL_ 3221225472 TFX_StbdMotorFault 1 "Active" 0 "Inactive" ;
VAL_ 3221225472 TFX_StbdElectronicFault 1 "Active" 0 "Inactive" ;
VAL_ 3221225472 TFX_StbdCylWrongDirection 1 "Active" 0 "Inactive" ;
VAL_ 3221225472 TFX_StbdCylUnintendedMove 1 "Active" 0 "Inactive" ;
VAL_ 3221225472 TFX_StbdCylSensorNotCalibrated 1 "Active" 0 "Inactive" ;
VAL_ 3221225472 TFX_StbdCylSensorFault 1 "Active" 0 "Inactive" ;
VAL_ 3221225472 TFX_StbdCylDidNotMove 1 "Active" 0 "Inactive" ;
VAL_ 3221225472 TFX_StbdBatVoltageFault 1 "Active" 0 "Inactive" ;
VAL_ 3221225472 TFX_PortCylWrongDirection 1 "Active" 0 "Inactive" ;
VAL_ 3221225472 TFX_PortCylSensorNotCalibrated 1 "Active" 0 "Inactive" ;
VAL_ 3221225472 TFX_PortCylSensorFault 1 "Active" 0 "Inactive" ;
VAL_ 3221225472 TFX_StbdSideVoltageSource 1 "Starboard" 0 "Port" ;
VAL_ 3221225472 TFX_StbdSidePerformance 3 "Not Available" 2 "Shut Down" 1 "Limited" 0 "Full" ;
VAL_ 3221225472 TFX_PortSideVoltageSource 1 "Starboard" 0 "Port" ;
VAL_ 3221225472 TFX_PortSidePerformance 3 "Not Available" 2 "Shut Down" 1 "Limited" 0 "Full" ;
VAL_ 3221225472 TFX_PortTempSensorFault 1 "Active" 0 "Inactive" ;
VAL_ 3221225472 TFX_PortOverTempFault 1 "Active" 0 "Inactive" ;
VAL_ 3221225472 TFX_PortMotorFault 1 "Active" 0 "Inactive" ;
VAL_ 3221225472 TFX_PortElectronicFault 1 "Active" 0 "Inactive" ;
VAL_ 3221225472 TFX_PortCylUnintendedMove 1 "Active" 0 "Inactive" ;
VAL_ 3221225472 TFX_PortCylDidNotMove 1 "Active" 0 "Inactive" ;
VAL_ 3221225472 TFX_PortBatVoltageFault 1 "Active" 0 "Inactive" ;
VAL_ 3221225472 TFX_ThrActHrtBtLoss_2 1 "Active" 0 "Inactive" ;
VAL_ 3221225472 TFX_ThrActHrtBtLoss_1 1 "Active" 0 "Inactive" ;
VAL_ 3221225472 TFX_ThrActHrtBtLoss_0 1 "Active" 0 "Inactive" ;
VAL_ 3221225472 TFX_ShftActHrtBtLoss_2 1 "Active" 0 "Inactive" ;
VAL_ 3221225472 TFX_ShftActHrtBtLoss_1 1 "Active" 0 "Inactive" ;
VAL_ 3221225472 TFX_ShftActHrtBtLoss_0 1 "Active" 0 "Inactive" ;
VAL_ 3221225472 TFX_PCM_HrtBtLoss_1 1 "Active" 0 "Inactive" ;
VAL_ 3221225472 TFX_PCM_HrtBtLoss_0 1 "Active" 0 "Inactive" ;
VAL_ 3221225472 TFX_JoystickYaxisPotFault 1 "Active" 0 "Inactive" ;
VAL_ 3221225472 TFX_JoystickXaxisPotFault 1 "Active" 0 "Inactive" ;
VAL_ 3221225472 TFX_JoystickThetaAxisPotFault 1 "Active" 0 "Inactive" ;
VAL_ 3221225472 TFX_ThrActHrtBtLoss_3 1 "Active" 0 "Inactive" ;
VAL_ 3221225472 TFX_StbdLeverFault 1 "Active" 0 "Inactive" ;
VAL_ 3221225472 TFX_ShftActHrtBtLoss_3 1 "Active" 0 "Inactive" ;
VAL_ 3221225472 TFX_PortLeverFault 1 "Active" 0 "Inactive" ;
VAL_ 3221225472 TFX_WarningFault 1 "Active" 0 "Inactive" ;
VAL_ 3221225472 TFX_ThrUpMotionFault 1 "Active" 0 "Inactive" ;
VAL_ 3221225472 TFX_ThrDwnMotionFault 1 "Active" 0 "Inactive" ;
VAL_ 3221225472 TFX_ShiftRevMotionFault 1 "Active" 0 "Inactive" ;
VAL_ 3221225472 TFX_ShiftNeutMotionFault 1 "Active" 0 "Inactive" ;
VAL_ 3221225472 TFX_ShiftFwdMotionFault 1 "Active" 0 "Inactive" ;
VAL_ 3221225472 TFX_CriticalFault 1 "Active" 0 "Inactive" ;
VAL_ 3221225472 TFX_ActuatorType 1 "Throttle" 0 "Shift" ;
VAL_ 3221225472 TFX_ActualGearValue 15 "Not Available" 14 "Error" 2 "Reverse" 1 "Neutral" 0 "Forward" ;
VAL_ 3221225472 TFX_DockingMode 3 "Ignore" 1 "Description for the value '0x1'" 0 "Description for the value '0x0'" ;
VAL_ 3221225472 TFX_StationProtect 3 "Ignore" 1 "On" 0 "Off" ;
VAL_ 3221225472 TFX_SplitRange 65535 "Ignore" ;
VAL_ 3221225472 TFX_LeadLever 3 "Ignore" 1 "Starboard" 0 "Port" ;
VAL_ 3221225472 TFX_FailureToSomething 3 "Ignore" 1 "Gear" 0 "Neutral" ;
VAL_ 3221225472 TFX_SCU_SourceInstance 15 "Not Available" 14 "Error" 3 "Stbd Center" 2 "Port Center" 1 "Stbd" 0 "Port" ;
VAL_ 3221225472 TFX_PCM_StbdHBridgeSource 1 "Stbd" 0 "Port" ;
VAL_ 3221225472 TFX_PCM_PortHBridgeSource 1 "Stbd" 0 "Port" ;
VAL_ 3221225472 TFX_SourceType 1 "Joystick" 0 "Main PCM" ;
VAL_ 3221225472 ETEC_G2_Fault 1 "Yes" 0 "No" ;
VAL_ 3221225472 ETEC_G2_Gear 3 "N/A" 2 "REV" 1 "FWD" 0 "NTL" ;
VAL_ 3221225472 GearCommand 15 "Not Available" 14 "Error" 2 "Reverse" 1 "Neutral" 0 "Forward" ;
VAL_ 3221225472 LimpHomeCommand 1 "Active" 0 "Inactive" ;
VAL_ 3221225472 NTLStartProtection 1 "Active" 0 "Inactive" ;
VAL_ 3221225472 StartStopCommand 3 "Reserved" 2 "Engine Stop" 1 "Engine Start" 0 "No Change" ;
VAL_ 3221225472 TrimCommand 2 "Trim Down Active" 1 "Trim Up Active" 0 "No Trim Change" ;
VAL_ 3221225472 Synchronizing 1 "Active" 0 "Inactive" ;
VAL_ 3221225472 TFX_ST_StbdShiftCmd 3 "Not Available" 2 "Reverse" 1 "Neutral" 0 "Forward" ;
VAL_ 3221225472 TFX_ST_PortShiftCmd 3 "Not Available" 2 "Reverse" 1 "Neutral" 0 "Forward" ;
VAL_ 3221225472 TFX_SteeringDerated 1 "Derated" 0 "Not derated" ;
VAL_ 3221225472 TFX_SteeringOverride 1 "Yes" 0 "No" ;
VAL_ 2680225624 TFX_DangerFault 1 "Active" 0 "Inactive" ;
VAL_ 2680225624 TFX_Warning_Fault 1 "Active" 0 "Inactive" ;
VAL_ 2680225624 TFX_SourceInstance 1 "Stbd" 0 "Port" ;
VAL_ 2680225624 TFX_IndustryGroup 5 "IndustrialProcess" 3 "Construction" 2 "AgriculturalAndForestry" 0 "Global" 1 "OnHighway" 4 "Marine" ;
VAL_ 2680225624 TFX_Header 1850 "Teleflex" ;
VAL_ 2680225593 SSS_FF39_ControllerFaultStatus 2 "Critical Fault Active" 1 "Caution Fault Active" 0 "No Active Faults" ;
VAL_ 2680225592 SSS_FF38_HomeBtnEvent 3 "Ignore" 2 "No Change/Held" 1 "Pressed" 0 "Released" ;
VAL_ 2680225592 SSS_FF38_FavoriteBtnState 3 "Ignore" 2 "No Change/Held" 1 "Pressed" 0 "Released" ;
VAL_ 2680225592 SSS_FF38_RollStbdBtnEvent 3 "Ignore" 2 "No Change/Held" 1 "Pressed" 0 "Released" ;
VAL_ 2680225592 SSS_FF38_RollPortBtnEvent 3 "Ignore" 2 "No Change/Held" 1 "Pressed" 0 "Released" ;
VAL_ 2680225592 SSS_FF38_BowUpBtnEvent 3 "Ignore" 2 "No Change/Held" 1 "Pressed" 0 "Released" ;
VAL_ 2680225592 SSS_FF38_BowDnBtnEvent 3 "Ignore" 2 "No Change/Held" 1 "Pressed" 0 "Released" ;
VAL_ 2680225585 SSS_FF31_HDVerifyStatus 3 "N/A" 2 "Passed" 1 "Failed" 0 "Ok" ;
VAL_ 2680225623 SSS_FF57_ToolCalibStatus 15 "N/A" 8 "Complete" 7 "Failed" 6 "Stbd HS Invalid" 5 "Port HS Invalid" 4 "Stbd HS Detected" 3 "Port HS Detected" 2 "Moving to Stbd" 1 "Moving to Port" 0 "Idle" ;
VAL_ 2680225623 SSS_FF57_ToolCalibInstruction 15 "N/A" 3 "Retry" 2 "Activate Steering" 1 "Turn to Stbd" 0 "Turn to Port" ;
VAL_ 2680225623 SSS_FF57_FieldCalibStatus 15 "N/A" 8 "Complete" 7 "Failed" 6 "Stbd HS Invalid" 5 "Port HS Invalid" 4 "Stbd HS Detected" 3 "Port HS Detected" 2 "Moving to Stbd" 1 "Moving to Port" 0 "Idle" ;
VAL_ 2680225623 SSS_FF57_FieldCalibState 5 "Freeze" 4 "Idle" 3 "Complete" 2 "Stbd HS Search" 1 "Port HS Search" 0 "Startup" ;
VAL_ 2680225586 SSS_FF32_SafeMode 15 "No Data" 14 "Error" 13 "All" ;
VAL_ 2680225586 IndustryGroup 5 "IndustrialProcess" 3 "Construction" 2 "AgriculturalAndForestry" 0 "Global" 1 "OnHighway" 4 "Marine" ;
VAL_ 2680225586 ManufacturerCode 1861 "Vector" 1860 "MetalMarine" 1859 "Kvaser" 1858 "LittonMarine" 1857 "Simrad" 1856 "Trimble" 1855 "Furuno" 1854 "NorthStar" 1853 "JapanRadioCorp" 1852 "Navionics" 1851 "RaytheonMarine" 1850 "TeleflexMarine" ;
VAL_ 2680225583 SSS_u4ActECUInstance 15 "No Data" 14 "Error" 13 "All" ;
VAL_ 2680225583 SSS_u2NumActsPerTab 3 "Ignore" 2 "2" 1 "1" 0 "0" ;
VAL_ 2680225583 SSS_u2AutoHomeOnKeyOff 3 "Ignore" 2 "Reserved" 1 "Enable" 0 "Disable" ;
VAL_ 2680225583 SSS_u2AutoHomeOnCommLoss 3 "Ignore" 2 "Reserved" 1 "Enable" 0 "Disable" ;
VAL_ 2680225583 IndustryGroup 5 "IndustrialProcess" 3 "Construction" 2 "AgriculturalAndForestry" 0 "Global" 1 "OnHighway" 4 "Marine" ;
VAL_ 2680225583 SSS_u4ActuatorFunctionType 15 "Ignore" 14 "Error" 13 "All" 7 "Smart Act 3" 6 "Smart Act 2" 5 "Smart Act 1" 4 "Surf Actuator" 3 "Trim Tab" 2 "Shallow Water Anchor" 1 "Jack Plate" 0 "Engine Trim" ;
VAL_ 2680225583 SSS_u4ActuatorFunctionInstance 15 "No Data" 14 "Error" 13 "All" ;
VAL_ 2680225583 ManufacturerCode 1861 "Vector" 1860 "MetalMarine" 1859 "Kvaser" 1858 "LittonMarine" 1857 "Simrad" 1856 "Trimble" 1855 "Furuno" 1854 "NorthStar" 1853 "JapanRadioCorp" 1852 "Navionics" 1851 "RaytheonMarine" 1850 "TeleflexMarine" ;
VAL_ 2680225584 SSS_u4ActECUInstance 15 "No Data" 14 "Error" 13 "All" ;
VAL_ 2680225584 SSS_u2NumActsPerTab 3 "Ignore" 2 "2" 1 "1" 0 "0" ;
VAL_ 2680225584 SSS_u2AutoHomeOnKeyOff 3 "Ignore" 2 "Reserved" 1 "Enable" 0 "Disable" ;
VAL_ 2680225584 SSS_u2AutoHomeOnCommLoss 3 "Ignore" 2 "Reserved" 1 "Enable" 0 "Disable" ;
VAL_ 2680225584 IndustryGroup 5 "IndustrialProcess" 3 "Construction" 2 "AgriculturalAndForestry" 0 "Global" 1 "OnHighway" 4 "Marine" ;
VAL_ 2680225584 SSS_u4ActuatorFunctionType 15 "Ignore" 14 "Error" 13 "All" 7 "Smart Act 3" 6 "Smart Act 2" 5 "Smart Act 1" 4 "Surf Actuator" 3 "Trim Tab" 2 "Shallow Water Anchor" 1 "Jack Plate" 0 "Engine Trim" ;
VAL_ 2680225584 SSS_u4ActuatorFunctionInstance 15 "No Data" 14 "Error" 13 "All" ;
VAL_ 2680225584 ManufacturerCode 1861 "Vector" 1860 "MetalMarine" 1859 "Kvaser" 1858 "LittonMarine" 1857 "Simrad" 1856 "Trimble" 1855 "Furuno" 1854 "NorthStar" 1853 "JapanRadioCorp" 1852 "Navionics" 1851 "RaytheonMarine" 1850 "TeleflexMarine" ;
VAL_ 2680225740 SSS_TrimDial_SrcType 2 "Trim Dial" 1 "DSC" 0 "MFD" ;
VAL_ 2680225740 SSS_TrimDial_SrcInstance 15 "Not Available" 14 "Error" ;
VAL_ 2680225740 SSS_TTA_MotionCommand 3 "No Cmd" 2 "Move down / Retract / Stbd" 1 "Move up / Extend / Port" 0 "Stop" ;
VAL_ 2680225740 SSS_TrimTabSpeedCmd 4095 "No Change" 4094 "Error" ;
VAL_ 2680225740 SSS_TrimTabPositionCmd 2047 "Description for the value '2'" 2046 "Error" 2043 "Home Cmd" ;
VAL_ 2680225740 IndustryGroup 5 "IndustrialProcess" 3 "Construction" 2 "AgriculturalAndForestry" 0 "Global" 1 "OnHighway" 4 "Marine" ;
VAL_ 2680225740 SSS_u4ActuatorFunctionType 15 "Ignore" 14 "Error" 13 "All" 7 "Smart Act 3" 6 "Smart Act 2" 5 "Smart Act 1" 4 "Surf Actuator" 3 "Trim Tab" 2 "Shallow Water Anchor" 1 "Jack Plate" 0 "Engine Trim" ;
VAL_ 2680225740 SSS_u4ActuatorFunctionInstance 15 "No Data" 14 "Error" 13 "All" ;
VAL_ 2680225740 ManufacturerCode 1861 "Vector" 1860 "MetalMarine" 1859 "Kvaser" 1858 "LittonMarine" 1857 "Simrad" 1856 "Trimble" 1855 "Furuno" 1854 "NorthStar" 1853 "JapanRadioCorp" 1852 "Navionics" 1851 "RaytheonMarine" 1850 "TeleflexMarine" ;
VAL_ 2680225741 IndustryGroup 5 "IndustrialProcess" 3 "Construction" 2 "AgriculturalAndForestry" 0 "Global" 1 "OnHighway" 4 "Marine" ;
VAL_ 2680225741 SSS_u4ActuatorFunctionType 15 "Ignore" 14 "Error" 13 "All" 7 "Smart Act 3" 6 "Smart Act 2" 5 "Smart Act 1" 4 "Surf Actuator" 3 "Trim Tab" 2 "Shallow Water Anchor" 1 "Jack Plate" 0 "Engine Trim" ;
VAL_ 2680225741 SSS_u4ActuatorFunctionInstance 15 "No Data" 14 "Error" 13 "All" ;
VAL_ 2680225741 SSS_u2SensorFault 3 "Ignore" 2 "Warning" 1 "Caution" 0 "Inactive" ;
VAL_ 2680225741 SSS_u2CommFault 3 "Ignore" 2 "Warning" 1 "Caution" 0 "Inactive" ;
VAL_ 2680225741 SSS_u2ActuatorFault 3 "Ignore" 2 "Warning" 1 "Caution" 0 "Inactive" ;
VAL_ 2680225741 SSS_u2VoltageFault 3 "Ignore" 2 "Warning" 1 "Caution" 0 "Inactive" ;
VAL_ 2680225741 SSS_u2MotionFdbk 3 "No Cmd" 2 "Move down / Retract / Stbd" 1 "Move up / Extend / Port" 0 "Stop" ;
VAL_ 2680225741 SSS_u12SpeedFdbk 4095 "No Change" 4094 "Error" ;
VAL_ 2680225741 ManufacturerCode 1861 "Vector" 1860 "MetalMarine" 1859 "Kvaser" 1858 "LittonMarine" 1857 "Simrad" 1856 "Trimble" 1855 "Furuno" 1854 "NorthStar" 1853 "JapanRadioCorp" 1852 "Navionics" 1851 "RaytheonMarine" 1850 "TeleflexMarine" ;
VAL_ 2680225741 SSS_i12PositionFdbk 2047 "No Data" 2046 "Error" 2043 "Not Homed Yet" ;
VAL_ 2680225667 Number_of_TrimControllers 15 "Ignore" 14 "Default" ;
VAL_ 2680225667 Number_of_TrimTabs 15 "Ignore" 14 "Default" ;
VAL_ 2680225667 TFX_Header 1850 "Teleflex" ;
VAL_ 2680225667 IndustryGroup 5 "IndustrialProcess" 3 "Construction" 2 "AgriculturalAndForestry" 0 "Global" 1 "OnHighway" 4 "Marine" ;
VAL_ 2680225582 SSS_u2SensorFault_65326 3 "Ignore" 2 "Warning" 1 "Caution" 0 "Inactive" ;
VAL_ 2680225582 SSS_u2VoltageFault_65326 3 "Ignore" 2 "Warning" 1 "Caution" 0 "Inactive" ;
VAL_ 2680225582 SSS_u2CommFault_65326 3 "Ignore" 2 "Warning" 1 "Caution" 0 "Inactive" ;
VAL_ 2680225582 SSS_u2ActuatorFault_65326 3 "Ignore" 2 "Warning" 1 "Caution" 0 "Inactive" ;
VAL_ 2680225582 IndustryGroup 5 "IndustrialProcess" 3 "Construction" 2 "AgriculturalAndForestry" 0 "Global" 1 "OnHighway" 4 "Marine" ;
VAL_ 2680225582 ManufacturerCode 1861 "Vector" 1860 "MetalMarine" 1859 "Kvaser" 1858 "LittonMarine" 1857 "Simrad" 1856 "Trimble" 1855 "Furuno" 1854 "NorthStar" 1853 "JapanRadioCorp" 1852 "Navionics" 1851 "RaytheonMarine" 1850 "TeleflexMarine" ;
VAL_ 2680225581 SSS_u8ActuatorType 15 "Ignore" 14 "Error" 13 "All" 7 "Smart Act 3" 6 "Smart Act 2" 5 "Smart Act 1" 4 "Surf Actuator" 3 "Trim Tab" 2 "Shallow Water Anchor" 1 "Jack Plate" 0 "Engine Trim" ;
VAL_ 2680225581 SSS_u4ECUInstance 15 "No Data" 14 "Error" 13 "All" ;
VAL_ 2680225581 SSS_u4FunctionType 15 "Ignore" 14 "Error" 13 "All" 7 "Smart Act 3" 6 "Smart Act 2" 5 "Smart Act 1" 4 "Surf Actuator" 3 "Trim Tab" 2 "Shallow Water Anchor" 1 "Jack Plate" 0 "Engine Trim" ;
VAL_ 2680225581 SSS_u4FunctionInstance 15 "No Data" 14 "Error" 13 "All" ;
VAL_ 2680225581 IndustryGroup 5 "IndustrialProcess" 3 "Construction" 2 "AgriculturalAndForestry" 0 "Global" 1 "OnHighway" 4 "Marine" ;
VAL_ 2680225581 ManufacturerCode 1861 "Vector" 1860 "MetalMarine" 1859 "Kvaser" 1858 "LittonMarine" 1857 "Simrad" 1856 "Trimble" 1855 "Furuno" 1854 "NorthStar" 1853 "JapanRadioCorp" 1852 "Navionics" 1851 "RaytheonMarine" 1850 "TeleflexMarine" ;
VAL_ 2147544832 CPP_Command 255 "ECU_RESPONCE" 23 "EXCHANGE_ID" 19 "UNLOCK" 18 "GET_SEED" 4 "UPLOAD" 3 "DOWNLOAD" 2 "SET_MTA" 1 "CONNECT" ;
VAL_ 2147548961 TransmissionGear 3 "Unavailable" 2 "Reverse" 1 "Neutral" 0 "Forward" ;
VAL_ 2680225567 TFX_IndustryGroup 5 "IndustrialProcess" 3 "Construction" 2 "AgriculturalAndForestry" 0 "Global" 1 "OnHighway" 4 "Marine" ;
VAL_ 2680225567 TFX_Header 1850 "Teleflex" ;
VAL_ 2680225566 TFX_Header 1850 "Teleflex" ;
VAL_ 2680225566 TFX_IndustryGroup 5 "IndustrialProcess" 3 "Construction" 2 "AgriculturalAndForestry" 0 "Global" 1 "OnHighway" 4 "Marine" ;
VAL_ 2680225566 MercTrollingState 3 "Not Available (default)" 2 "Error" 1 "Mode on" 0 "Mode off" ;
VAL_ 2680225566 MercThrottleOnlyState 3 "Not Available (default)" 2 "Error" 1 "Mode on" 0 "Mode off" ;
VAL_ 2680225566 MercGateSingleLeverState 3 "Not Available (default)" 2 "Error" 1 "Mode on" 0 "Mode off" ;
VAL_ 2680225566 MercAuthenticationStatus 1 "Authenticated" 0 "Not Authenticated (default)" ;
VAL_ 2680225601 AutopiloteMode 4 "Override" 3 "Route" 2 "Track" 1 "Heading" 0 "Standby" ;
VAL_ 2680225601 IndustryGroup 5 "IndustrialProcess" 3 "Construction" 2 "AgriculturalAndForestry" 0 "Global" 1 "OnHighway" 4 "Marine" ;
VAL_ 2680225601 ManufacturerCode 1861 "Vector" 1860 "MetalMarine" 1859 "Kvaser" 1858 "LittonMarine" 1857 "Simrad" 1856 "Trimble" 1855 "Furuno" 1854 "NorthStar" 1853 "JapanRadioCorp" 1852 "Navionics" 1851 "RaytheonMarine" 1850 "TeleflexMarine" ;
VAL_ 2680225596 IndustryGroup 5 "IndustrialProcess" 3 "Construction" 2 "AgriculturalAndForestry" 0 "Global" 1 "OnHighway" 4 "Marine" ;
VAL_ 2680225596 ManufacturerCode 1861 "Vector" 1860 "MetalMarine" 1859 "Kvaser" 1858 "LittonMarine" 1857 "Simrad" 1856 "Trimble" 1855 "Furuno" 1854 "NorthStar" 1853 "JapanRadioCorp" 1852 "Navionics" 1851 "RaytheonMarine" 1850 "TeleflexMarine" ;
VAL_ 2680225692 PCM_WrgDir_HS 2 "Stbd" 1 "Port" 0 "None" ;
VAL_ 2680225720 CPU_Reset_Source 1024 "Software Reset" 512 "Core Lockup" 256 "JTAG Reset" 130 "Power-on" 65 "VLLS with reset Assertion" 64 "External" 32 "Watchdog" 4 "Loss-of-Clock" 2 "Low-voltage Detect" 1 "Low Leakage Wakeup" ;
VAL_ 2680225730 ASK_AskZone 6 "CCW" 5 "CW" 4 "Port" 3 "Reverse" 2 "Starboard" 1 "Forward" 0 "Neutral" ;
VAL_ 2680225730 ASK_AskMode 3 "Position & Heading" 2 "Heading" 1 "Position" 0 "Off" ;
VAL_ 2680225618 TFX_PCM_Command 5 "Store Stbd Helm Cal HS" 4 "Store Port Helm Cal HS" 3 "Init Helm Cal" 2 "Reset" 1 "Powerdown" 0 "No Command" ;
VAL_ 2680225618 TFX_IndustryGroup 5 "IndustrialProcess" 3 "Construction" 2 "AgriculturalAndForestry" 0 "Global" 1 "OnHighway" 4 "Marine" ;
VAL_ 2680225618 TFX_Header 1850 "Teleflex" ;
VAL_ 2147610906 VariationSource 63 "Data Not Available" 8 "WMM 2020" 7 "WMM 2015" 6 "WMM 2010" 5 "WMM 2005" 4 "WMM 2000" 3 "Automatic - Calculation" 2 "Automatic - Table" 1 "Automatic - Chart" 0 "Manual Entry" ;
VAL_ 2680225693 Power_Wakeup 5 "Unknown" 4 "Both CANs" 3 "CAN2" 2 "CAN1" 1 "Other" 0 "Ignition" ;
VAL_ 2680225693 Power_State 2 "Powerdown" 1 "Wakeup" 0 "Unknown" ;
VAL_ 2680225668 Power_Wakeup 5 "Unknown" 4 "Both CANs" 3 "CAN2" 2 "CAN1" 1 "Other" 0 "Ignition" ;
VAL_ 2680225668 Power_SystemCmd 7 "Ignore" 1 "Force Reset" 0 "Set Pdown timer to save time" ;
VAL_ 2680225668 Power_State 2 "Powerdown" 1 "Wakeup" 0 "Unknown" ;
VAL_ 2680225668 IndustryGroup 5 "IndustrialProcess" 3 "Construction" 2 "AgriculturalAndForestry" 0 "Global" 1 "OnHighway" 4 "Marine" ;
VAL_ 2680225668 TFX_Header 1850 "Teleflex" ;
VAL_ 2680225723 IndustryGroup 5 "IndustrialProcess" 3 "Construction" 2 "AgriculturalAndForestry" 0 "Global" 1 "OnHighway" 4 "Marine" ;
VAL_ 2680225723 ManufacturerCode 1861 "Vector" 1860 "MetalMarine" 1859 "Kvaser" 1858 "LittonMarine" 1857 "Simrad" 1856 "Trimble" 1855 "Furuno" 1854 "NorthStar" 1853 "JapanRadioCorp" 1852 "Navionics" 1851 "RaytheonMarine" 1850 "TeleflexMarine" ;
VAL_ 2680225721 IndustryGroup 5 "IndustrialProcess" 3 "Construction" 2 "AgriculturalAndForestry" 0 "Global" 1 "OnHighway" 4 "Marine" ;
VAL_ 2680225721 ManufacturerCode 1861 "Vector" 1860 "MetalMarine" 1859 "Kvaser" 1858 "LittonMarine" 1857 "Simrad" 1856 "Trimble" 1855 "Furuno" 1854 "NorthStar" 1853 "JapanRadioCorp" 1852 "Navionics" 1851 "RaytheonMarine" 1850 "TeleflexMarine" ;
VAL_ 2680225712 GwStbdPowerOn 1 "On" 0 "Off" ;
VAL_ 2680225712 GwStbdActive 1 "On" 0 "Off" ;
VAL_ 2680225712 GwSCtrPowerOn 1 "On" 0 "Off" ;
VAL_ 2680225712 GwSCtrAlert 1 "On" 0 "Off" ;
VAL_ 2680225712 GwSCtrActive 1 "On" 0 "Off" ;
VAL_ 2680225712 GwPortActive 1 "On" 0 "Off" ;
VAL_ 2680225712 GwPCtrPowerOn 1 "On" 0 "Off" ;
VAL_ 2680225712 GwPCtrAlert 1 "On" 0 "Off" ;
VAL_ 2680225712 GwPCtrActive 1 "On" 0 "Off" ;
VAL_ 2680225712 GwStbdAlert 1 "On" 0 "Off" ;
VAL_ 2680225712 GwPortPowerOn 1 "On" 0 "Off" ;
VAL_ 2680225712 GwPortAlert 1 "On" 0 "Off" ;
VAL_ 2330001257 TFX_ControlState_Act 15 "Not Available" 14 "Error" 5 "Freeze" 4 "Active" 3 "Calibration" 2 "Power Down" 1 "Inactive" ;
VAL_ 2330001257 TFX_WarningFault 1 "Active" 0 "Inactive" ;
VAL_ 2330001257 TFX_ThrUpMotionFault 1 "Active" 0 "Inactive" ;
VAL_ 2330001257 TFX_ThrDwnMotionFault 1 "Active" 0 "Inactive" ;
VAL_ 2330001257 TFX_ShiftRevMotionFault 1 "Active" 0 "Inactive" ;
VAL_ 2330001257 TFX_ShiftNeutMotionFault 1 "Active" 0 "Inactive" ;
VAL_ 2330001257 TFX_ShiftFwdMotionFault 1 "Active" 0 "Inactive" ;
VAL_ 2330001257 TFX_CriticalFault 1 "Active" 0 "Inactive" ;
VAL_ 2330001257 TFX_ActuatorType 3 "Not Available" 2 "EST Gateway" 1 "Throttle" 0 "Shift" ;
VAL_ 2330001257 TFX_ActualTrollingValveValue 255 "Not Available" 254 "Error" ;
VAL_ 2330001257 TFX_ActualThrottleValue 65535 "Not Available" 65534 "Error" ;
VAL_ 2330001257 TFX_ActualGearValue 15 "Not Available" 14 "Error" 2 "Reverse" 1 "Neutral" 0 "Forward" ;
VAL_ 2330001257 TFX_SourceInstance 1 "Stbd" 0 "Port" ;
VAL_ 2330001257 TFX_IndustryGroup 5 "IndustrialProcess" 3 "Construction" 2 "AgriculturalAndForestry" 0 "Global" 1 "OnHighway" 4 "Marine" ;
VAL_ 2330001257 TFX_Header 1850 "Teleflex" ;
VAL_ 2332098409 TFX_ControlState_Act 15 "Not Available" 14 "Error" 5 "Freeze" 4 "Active" 3 "Calibration" 2 "Power Down" 1 "Inactive" ;
VAL_ 2332098409 TFX_WarningFault 1 "Active" 0 "Inactive" ;
VAL_ 2332098409 TFX_ThrUpMotionFault 1 "Active" 0 "Inactive" ;
VAL_ 2332098409 TFX_ThrDwnMotionFault 1 "Active" 0 "Inactive" ;
VAL_ 2332098409 TFX_ShiftRevMotionFault 1 "Active" 0 "Inactive" ;
VAL_ 2332098409 TFX_ShiftNeutMotionFault 1 "Active" 0 "Inactive" ;
VAL_ 2332098409 TFX_ShiftFwdMotionFault 1 "Active" 0 "Inactive" ;
VAL_ 2332098409 TFX_CriticalFault 1 "Active" 0 "Inactive" ;
VAL_ 2332098409 TFX_ActuatorType 3 "Not Available" 2 "EST Gateway" 1 "Throttle" 0 "Shift" ;
VAL_ 2332098409 TFX_ActualTrollingValveValue 255 "Not Available" 254 "Error" ;
VAL_ 2332098409 TFX_ActualThrottleValue 65535 "Not Available" 65534 "Error" ;
VAL_ 2332098409 TFX_ActualGearValue 15 "Not Available" 14 "Error" 2 "Reverse" 1 "Neutral" 0 "Forward" ;
VAL_ 2332098409 TFX_SourceInstance 1 "Stbd" 0 "Port" ;
VAL_ 2332098409 TFX_IndustryGroup 5 "IndustrialProcess" 3 "Construction" 2 "AgriculturalAndForestry" 0 "Global" 1 "OnHighway" 4 "Marine" ;
VAL_ 2332098409 TFX_Header 1850 "Teleflex" ;
VAL_ 2334195561 TFX_ControlState_Act 15 "Not Available" 14 "Error" 5 "Freeze" 4 "Active" 3 "Calibration" 2 "Power Down" 1 "Inactive" ;
VAL_ 2334195561 TFX_WarningFault 1 "Active" 0 "Inactive" ;
VAL_ 2334195561 TFX_ThrUpMotionFault 1 "Active" 0 "Inactive" ;
VAL_ 2334195561 TFX_ThrDwnMotionFault 1 "Active" 0 "Inactive" ;
VAL_ 2334195561 TFX_ShiftRevMotionFault 1 "Active" 0 "Inactive" ;
VAL_ 2334195561 TFX_ShiftNeutMotionFault 1 "Active" 0 "Inactive" ;
VAL_ 2334195561 TFX_ShiftFwdMotionFault 1 "Active" 0 "Inactive" ;
VAL_ 2334195561 TFX_CriticalFault 1 "Active" 0 "Inactive" ;
VAL_ 2334195561 TFX_ActuatorType 3 "Not Available" 2 "EST Gateway" 1 "Throttle" 0 "Shift" ;
VAL_ 2334195561 TFX_ActualTrollingValveValue 255 "Not Available" 254 "Error" ;
VAL_ 2334195561 TFX_ActualThrottleValue 65535 "Not Available" 65534 "Error" ;
VAL_ 2334195561 TFX_ActualGearValue 15 "Not Available" 14 "Error" 2 "Reverse" 1 "Neutral" 0 "Forward" ;
VAL_ 2334195561 TFX_SourceInstance 1 "Stbd" 0 "Port" ;
VAL_ 2334195561 TFX_IndustryGroup 5 "IndustrialProcess" 3 "Construction" 2 "AgriculturalAndForestry" 0 "Global" 1 "OnHighway" 4 "Marine" ;
VAL_ 2334195561 TFX_Header 1850 "Teleflex" ;
VAL_ 2327904105 TFX_ControlState_Act 15 "Not Available" 14 "Error" 5 "Freeze" 4 "Active" 3 "Calibration" 2 "Power Down" 1 "Inactive" ;
VAL_ 2327904105 TFX_WarningFault 1 "Active" 0 "Inactive" ;
VAL_ 2327904105 TFX_ThrUpMotionFault 1 "Active" 0 "Inactive" ;
VAL_ 2327904105 TFX_ThrDwnMotionFault 1 "Active" 0 "Inactive" ;
VAL_ 2327904105 TFX_ShiftRevMotionFault 1 "Active" 0 "Inactive" ;
VAL_ 2327904105 TFX_ShiftNeutMotionFault 1 "Active" 0 "Inactive" ;
VAL_ 2327904105 TFX_ShiftFwdMotionFault 1 "Active" 0 "Inactive" ;
VAL_ 2327904105 TFX_CriticalFault 1 "Active" 0 "Inactive" ;
VAL_ 2327904105 TFX_ActuatorType 3 "Not Available" 2 "EST Gateway" 1 "Throttle" 0 "Shift" ;
VAL_ 2327904105 TFX_ActualTrollingValveValue 255 "Not Available" 254 "Error" ;
VAL_ 2327904105 TFX_ActualThrottleValue 65535 "Not Available" 65534 "Error" ;
VAL_ 2327904105 TFX_ActualGearValue 15 "Not Available" 14 "Error" 2 "Reverse" 1 "Neutral" 0 "Forward" ;
VAL_ 2327904105 TFX_SourceInstance 1 "Stbd" 0 "Port" ;
VAL_ 2327904105 TFX_IndustryGroup 5 "IndustrialProcess" 3 "Construction" 2 "AgriculturalAndForestry" 0 "Global" 1 "OnHighway" 4 "Marine" ;
VAL_ 2327904105 TFX_Header 1850 "Teleflex" ;
VAL_ 2325806953 TFX_ControlState_Act 15 "Not Available" 14 "Error" 5 "Freeze" 4 "Active" 3 "Calibration" 2 "Power Down" 1 "Inactive" ;
VAL_ 2325806953 TFX_WarningFault 1 "Active" 0 "Inactive" ;
VAL_ 2325806953 TFX_ThrUpMotionFault 1 "Active" 0 "Inactive" ;
VAL_ 2325806953 TFX_ThrDwnMotionFault 1 "Active" 0 "Inactive" ;
VAL_ 2325806953 TFX_ShiftRevMotionFault 1 "Active" 0 "Inactive" ;
VAL_ 2325806953 TFX_ShiftNeutMotionFault 1 "Active" 0 "Inactive" ;
VAL_ 2325806953 TFX_ShiftFwdMotionFault 1 "Active" 0 "Inactive" ;
VAL_ 2325806953 TFX_CriticalFault 1 "Active" 0 "Inactive" ;
VAL_ 2325806953 TFX_ActuatorType 3 "Not Available" 2 "EST Gateway" 1 "Throttle" 0 "Shift" ;
VAL_ 2325806953 TFX_ActualTrollingValveValue 255 "Not Available" 254 "Error" ;
VAL_ 2325806953 TFX_ActualThrottleValue 65535 "Not Available" 65534 "Error" ;
VAL_ 2325806953 TFX_ActualGearValue 15 "Not Available" 14 "Error" 2 "Reverse" 1 "Neutral" 0 "Forward" ;
VAL_ 2325806953 TFX_SourceInstance 1 "Stbd" 0 "Port" ;
VAL_ 2325806953 TFX_IndustryGroup 5 "IndustrialProcess" 3 "Construction" 2 "AgriculturalAndForestry" 0 "Global" 1 "OnHighway" 4 "Marine" ;
VAL_ 2325806953 TFX_Header 1850 "Teleflex" ;
VAL_ 2323709801 TFX_ControlState_Act 15 "Not Available" 14 "Error" 5 "Freeze" 4 "Active" 3 "Calibration" 2 "Power Down" 1 "Inactive" ;
VAL_ 2323709801 TFX_WarningFault 1 "Active" 0 "Inactive" ;
VAL_ 2323709801 TFX_ThrUpMotionFault 1 "Active" 0 "Inactive" ;
VAL_ 2323709801 TFX_ThrDwnMotionFault 1 "Active" 0 "Inactive" ;
VAL_ 2323709801 TFX_ShiftRevMotionFault 1 "Active" 0 "Inactive" ;
VAL_ 2323709801 TFX_ShiftNeutMotionFault 1 "Active" 0 "Inactive" ;
VAL_ 2323709801 TFX_ShiftFwdMotionFault 1 "Active" 0 "Inactive" ;
VAL_ 2323709801 TFX_CriticalFault 1 "Active" 0 "Inactive" ;
VAL_ 2323709801 TFX_ActuatorType 3 "Not Available" 2 "EST Gateway" 1 "Throttle" 0 "Shift" ;
VAL_ 2323709801 TFX_ActualTrollingValveValue 255 "Not Available" 254 "Error" ;
VAL_ 2323709801 TFX_ActualThrottleValue 65535 "Not Available" 65534 "Error" ;
VAL_ 2323709801 TFX_ActualGearValue 15 "Not Available" 14 "Error" 2 "Reverse" 1 "Neutral" 0 "Forward" ;
VAL_ 2323709801 TFX_SourceInstance 1 "Stbd" 0 "Port" ;
VAL_ 2323709801 TFX_IndustryGroup 5 "IndustrialProcess" 3 "Construction" 2 "AgriculturalAndForestry" 0 "Global" 1 "OnHighway" 4 "Marine" ;
VAL_ 2323709801 TFX_Header 1850 "Teleflex" ;
VAL_ 2321612649 TFX_ControlState_Act 15 "Not Available" 14 "Error" 5 "Freeze" 4 "Active" 3 "Calibration" 2 "Power Down" 1 "Inactive" ;
VAL_ 2321612649 TFX_WarningFault 1 "Active" 0 "Inactive" ;
VAL_ 2321612649 TFX_ThrUpMotionFault 1 "Active" 0 "Inactive" ;
VAL_ 2321612649 TFX_ThrDwnMotionFault 1 "Active" 0 "Inactive" ;
VAL_ 2321612649 TFX_ShiftRevMotionFault 1 "Active" 0 "Inactive" ;
VAL_ 2321612649 TFX_ShiftNeutMotionFault 1 "Active" 0 "Inactive" ;
VAL_ 2321612649 TFX_ShiftFwdMotionFault 1 "Active" 0 "Inactive" ;
VAL_ 2321612649 TFX_CriticalFault 1 "Active" 0 "Inactive" ;
VAL_ 2321612649 TFX_ActuatorType 3 "Not Available" 2 "EST Gateway" 1 "Throttle" 0 "Shift" ;
VAL_ 2321612649 TFX_ActualTrollingValveValue 255 "Not Available" 254 "Error" ;
VAL_ 2321612649 TFX_ActualThrottleValue 65535 "Not Available" 65534 "Error" ;
VAL_ 2321612649 TFX_ActualGearValue 15 "Not Available" 14 "Error" 2 "Reverse" 1 "Neutral" 0 "Forward" ;
VAL_ 2321612649 TFX_SourceInstance 1 "Stbd" 0 "Port" ;
VAL_ 2321612649 TFX_IndustryGroup 5 "IndustrialProcess" 3 "Construction" 2 "AgriculturalAndForestry" 0 "Global" 1 "OnHighway" 4 "Marine" ;
VAL_ 2321612649 TFX_Header 1850 "Teleflex" ;
VAL_ 2319515497 TFX_ControlState_Act 15 "Not Available" 14 "Error" 5 "Freeze" 4 "Active" 3 "Calibration" 2 "Power Down" 1 "Inactive" ;
VAL_ 2319515497 TFX_WarningFault 1 "Active" 0 "Inactive" ;
VAL_ 2319515497 TFX_ThrUpMotionFault 1 "Active" 0 "Inactive" ;
VAL_ 2319515497 TFX_ThrDwnMotionFault 1 "Active" 0 "Inactive" ;
VAL_ 2319515497 TFX_ShiftRevMotionFault 1 "Active" 0 "Inactive" ;
VAL_ 2319515497 TFX_ShiftNeutMotionFault 1 "Active" 0 "Inactive" ;
VAL_ 2319515497 TFX_ShiftFwdMotionFault 1 "Active" 0 "Inactive" ;
VAL_ 2319515497 TFX_CriticalFault 1 "Active" 0 "Inactive" ;
VAL_ 2319515497 TFX_ActuatorType 3 "Not Available" 2 "EST Gateway" 1 "Throttle" 0 "Shift" ;
VAL_ 2319515497 TFX_ActualTrollingValveValue 255 "Not Available" 254 "Error" ;
VAL_ 2319515497 TFX_ActualThrottleValue 65535 "Not Available" 65534 "Error" ;
VAL_ 2319515497 TFX_ActualGearValue 15 "Not Available" 14 "Error" 2 "Reverse" 1 "Neutral" 0 "Forward" ;
VAL_ 2319515497 TFX_SourceInstance 1 "Stbd" 0 "Port" ;
VAL_ 2319515497 TFX_IndustryGroup 5 "IndustrialProcess" 3 "Construction" 2 "AgriculturalAndForestry" 0 "Global" 1 "OnHighway" 4 "Marine" ;
VAL_ 2319515497 TFX_Header 1850 "Teleflex" ;
VAL_ 2317418345 TFX_ControlState_Act 15 "Not Available" 14 "Error" 5 "Freeze" 4 "Active" 3 "Calibration" 2 "Power Down" 1 "Inactive" ;
VAL_ 2317418345 TFX_WarningFault 1 "Active" 0 "Inactive" ;
VAL_ 2317418345 TFX_ThrUpMotionFault 1 "Active" 0 "Inactive" ;
VAL_ 2317418345 TFX_ThrDwnMotionFault 1 "Active" 0 "Inactive" ;
VAL_ 2317418345 TFX_ShiftRevMotionFault 1 "Active" 0 "Inactive" ;
VAL_ 2317418345 TFX_ShiftNeutMotionFault 1 "Active" 0 "Inactive" ;
VAL_ 2317418345 TFX_ShiftFwdMotionFault 1 "Active" 0 "Inactive" ;
VAL_ 2317418345 TFX_CriticalFault 1 "Active" 0 "Inactive" ;
VAL_ 2317418345 TFX_ActuatorType 3 "Not Available" 2 "EST Gateway" 1 "Throttle" 0 "Shift" ;
VAL_ 2317418345 TFX_ActualTrollingValveValue 255 "Not Available" 254 "Error" ;
VAL_ 2317418345 TFX_ActualThrottleValue 65535 "Not Available" 65534 "Error" ;
VAL_ 2317418345 TFX_ActualGearValue 15 "Not Available" 14 "Error" 2 "Reverse" 1 "Neutral" 0 "Forward" ;
VAL_ 2317418345 TFX_SourceInstance 1 "Stbd" 0 "Port" ;
VAL_ 2317418345 TFX_IndustryGroup 5 "IndustrialProcess" 3 "Construction" 2 "AgriculturalAndForestry" 0 "Global" 1 "OnHighway" 4 "Marine" ;
VAL_ 2317418345 TFX_Header 1850 "Teleflex" ;
VAL_ 2315321193 TFX_ControlState_Act 15 "Not Available" 14 "Error" 5 "Freeze" 4 "Active" 3 "Calibration" 2 "Power Down" 1 "Inactive" ;
VAL_ 2315321193 TFX_WarningFault 1 "Active" 0 "Inactive" ;
VAL_ 2315321193 TFX_ThrUpMotionFault 1 "Active" 0 "Inactive" ;
VAL_ 2315321193 TFX_ThrDwnMotionFault 1 "Active" 0 "Inactive" ;
VAL_ 2315321193 TFX_ShiftRevMotionFault 1 "Active" 0 "Inactive" ;
VAL_ 2315321193 TFX_ShiftNeutMotionFault 1 "Active" 0 "Inactive" ;
VAL_ 2315321193 TFX_ShiftFwdMotionFault 1 "Active" 0 "Inactive" ;
VAL_ 2315321193 TFX_CriticalFault 1 "Active" 0 "Inactive" ;
VAL_ 2315321193 TFX_ActuatorType 3 "Not Available" 2 "EST Gateway" 1 "Throttle" 0 "Shift" ;
VAL_ 2315321193 TFX_ActualTrollingValveValue 255 "Not Available" 254 "Error" ;
VAL_ 2315321193 TFX_ActualThrottleValue 65535 "Not Available" 65534 "Error" ;
VAL_ 2315321193 TFX_ActualGearValue 15 "Not Available" 14 "Error" 2 "Reverse" 1 "Neutral" 0 "Forward" ;
VAL_ 2315321193 TFX_SourceInstance 1 "Stbd" 0 "Port" ;
VAL_ 2315321193 TFX_IndustryGroup 5 "IndustrialProcess" 3 "Construction" 2 "AgriculturalAndForestry" 0 "Global" 1 "OnHighway" 4 "Marine" ;
VAL_ 2315321193 TFX_Header 1850 "Teleflex" ;
VAL_ 2680225707 TFX_ControlState_EST 0 "YL: Startup, S: Unkn, YC: Unkn" 15 "Not Available" 14 "Error" 8 "EOL Test" 7 "Power down" 6 "Fault" 5 "Joystick Active" 4 "YL+S: CH Active, YC: Bypass" 3 "YL: Inactive, S: Cal, YC: Over " 2 "YL: S-Select, S: Cert, YC: Norm" 1 "YL: LPS Cal, S+YC: Startup" ;
VAL_ 2680225707 Gateway_Controlling 4 "Honda LPS" 3 "Verado LPS" 2 "Yamaha CAN Gateway" 15 "Not Available" 1 "Suzuki CAN Gateway" 0 "Yamaha LPS Gateway" ;
VAL_ 2680225707 TFX_WarningFault 1 "Active" 0 "Inactive" ;
VAL_ 2680225707 TFX_DangerFault 1 "Active" 0 "Inactive" ;
VAL_ 2680225707 TFX_SourceInstance 1 "Stbd" 0 "Port" ;
VAL_ 2680225707 TFX_IndustryGroup 5 "IndustrialProcess" 3 "Construction" 2 "AgriculturalAndForestry" 0 "Global" 1 "OnHighway" 4 "Marine" ;
VAL_ 2680225707 TFX_Header 1850 "Teleflex" ;
VAL_ 2680225639 TFX_IndustryGroup 5 "IndustrialProcess" 3 "Construction" 2 "AgriculturalAndForestry" 0 "Global" 1 "OnHighway" 4 "Marine" ;
VAL_ 2680225639 TFX_GearCommand_3 3 "Not Available" 2 "Reverse" 1 "Neutral" 0 "Forward" ;
VAL_ 2680225639 TFX_Header 1850 "Teleflex" ;
VAL_ 2680225638 TFX_IndustryGroup 5 "IndustrialProcess" 3 "Construction" 2 "AgriculturalAndForestry" 0 "Global" 1 "OnHighway" 4 "Marine" ;
VAL_ 2680225638 TFX_GearCommand_2 3 "Not Available" 2 "Reverse" 1 "Neutral" 0 "Forward" ;
VAL_ 2680225638 TFX_Header 1850 "Teleflex" ;
VAL_ 2680225627 TFX_CommandType 1 "Steering" 0 "Rudder" ;
VAL_ 2680225627 TFX_IndustryGroup 5 "IndustrialProcess" 3 "Construction" 2 "AgriculturalAndForestry" 0 "Global" 1 "OnHighway" 4 "Marine" ;
VAL_ 2680225627 TFX_Header 1850 "Teleflex" ;
VAL_ 2680225617 TFX_PCM_Command 5 "Store Stbd Helm Cal HS" 4 "Store Port Helm Cal HS" 3 "Init Helm Cal" 2 "Reset" 1 "Powerdown" 0 "No Command" ;
VAL_ 2680225617 TFX_IndustryGroup 5 "IndustrialProcess" 3 "Construction" 2 "AgriculturalAndForestry" 0 "Global" 1 "OnHighway" 4 "Marine" ;
VAL_ 2680225617 TFX_Header 1850 "Teleflex" ;
VAL_ 2680225665 EPSType 11 "Inboard EAxxxx" 10 "Inboard EC585X" 9 "Inboard EC539X" 8 "Outboard Electric" 7 "Outboard Verado" 15 "Undefined" 6 "None" 5 "Inboard EC581X" 4 "Inboard EC538X" 3 "Sterndrive EC536X" 2 "Sterndrive EC535X" 1 "ETEC_G2" 0 "Outboard Hydraulic" ;
VAL_ 2680225665 EST_Type 7 "ETEC-G2" 6 "None (EPS only)" 5 "i7700" 4 "Suzuki" 3 "Yamaha" 2 "Yanmar" 1 "ICON" 0 "i6800" ;
VAL_ 2680225665 RPMSource 4 "i7700 Tach" 3 "Electronic Engines" 2 "NMEA2000" 1 "PCM Tach" 0 "Unavailable" ;
VAL_ 2680225665 Number_of_EST_Gateways 15 "Ignore" 14 "Default" ;
VAL_ 2680225665 TFX_Header 1850 "Teleflex" ;
VAL_ 2680225665 IndustryGroup 5 "IndustrialProcess" 3 "Construction" 2 "AgriculturalAndForestry" 0 "Global" 1 "OnHighway" 4 "Marine" ;
VAL_ 2680225665 SystemType 3 "O360" 2 "EPS+EST" 1 "EST" 0 "EPS" ;
VAL_ 2680225665 Number_of_JSs 15 "Ignore" 14 "Default" ;
VAL_ 2680225665 Number_of_Helms 15 "Ignore" 14 "Default" ;
VAL_ 2680225665 Number_of_Engines 15 "Ignore" 14 "Default" ;
VAL_ 2680225665 Number_of_CHs 15 "Ignore" 14 "Default" ;
VAL_ 2680225666 TFX_IndustryGroup 5 "IndustrialProcess" 3 "Construction" 2 "AgriculturalAndForestry" 0 "Global" 1 "OnHighway" 4 "Marine" ;
VAL_ 2680225666 TFX_Header 1850 "Teleflex" ;
VAL_ 2680225666 TFX_DashboardIlluminationLevels 255 "Not Available" 254 "Error" ;
VAL_ 2384527209 TFX_ControlState_Act 15 "Not Available" 14 "Error" 5 "Freeze" 4 "Active" 3 "Calibration" 2 "Power Down" 1 "Inactive" ;
VAL_ 2384527209 TFX_WarningFault 1 "Active" 0 "Inactive" ;
VAL_ 2384527209 TFX_ThrUpMotionFault 1 "Active" 0 "Inactive" ;
VAL_ 2384527209 TFX_ThrDwnMotionFault 1 "Active" 0 "Inactive" ;
VAL_ 2384527209 TFX_ShiftRevMotionFault 1 "Active" 0 "Inactive" ;
VAL_ 2384527209 TFX_ShiftNeutMotionFault 1 "Active" 0 "Inactive" ;
VAL_ 2384527209 TFX_ShiftFwdMotionFault 1 "Active" 0 "Inactive" ;
VAL_ 2384527209 TFX_ActuatorType 1 "Throttle" 0 "Shift" ;
VAL_ 2384527209 TFX_ActualGearValue 15 "Not Available" 14 "Error" 2 "Reverse" 1 "Neutral" 0 "Forward" ;
VAL_ 2384527209 TFX_SourceInstance 1 "Stbd" 0 "Port" ;
VAL_ 2384527209 TFX_IndustryGroup 5 "IndustrialProcess" 3 "Construction" 2 "AgriculturalAndForestry" 0 "Global" 1 "OnHighway" 4 "Marine" ;
VAL_ 2384527209 TFX_Header 1850 "Teleflex" ;
VAL_ 2382430057 TFX_ControlState_Act 15 "Not Available" 14 "Error" 5 "Freeze" 4 "Active" 3 "Calibration" 2 "Power Down" 1 "Inactive" ;
VAL_ 2382430057 TFX_WarningFault 1 "Active" 0 "Inactive" ;
VAL_ 2382430057 TFX_ThrUpMotionFault 1 "Active" 0 "Inactive" ;
VAL_ 2382430057 TFX_ThrDwnMotionFault 1 "Active" 0 "Inactive" ;
VAL_ 2382430057 TFX_ShiftRevMotionFault 1 "Active" 0 "Inactive" ;
VAL_ 2382430057 TFX_ShiftNeutMotionFault 1 "Active" 0 "Inactive" ;
VAL_ 2382430057 TFX_ShiftFwdMotionFault 1 "Active" 0 "Inactive" ;
VAL_ 2382430057 TFX_ActuatorType 1 "Throttle" 0 "Shift" ;
VAL_ 2382430057 TFX_ActualGearValue 15 "Not Available" 14 "Error" 2 "Reverse" 1 "Neutral" 0 "Forward" ;
VAL_ 2382430057 TFX_SourceInstance 1 "Stbd" 0 "Port" ;
VAL_ 2382430057 TFX_IndustryGroup 5 "IndustrialProcess" 3 "Construction" 2 "AgriculturalAndForestry" 0 "Global" 1 "OnHighway" 4 "Marine" ;
VAL_ 2382430057 TFX_Header 1850 "Teleflex" ;
VAL_ 2680225698 NTLSwStatus 1 "Yes" 0 "No" ;
VAL_ 2680225698 NTLSwFault 1 "Yes" 0 "No" ;
VAL_ 2680225664 TFX_IndustryGroup 5 "IndustrialProcess" 3 "Construction" 2 "AgriculturalAndForestry" 0 "Global" 1 "OnHighway" 4 "Marine" ;
VAL_ 2680225664 TFX_Header 1850 "Teleflex" ;
VAL_ 2680225663 TFX_ReverseTrollingMode 255 "Ignore" ;
VAL_ 2680225663 TFX_ForwardTrollingMode 255 "Ignore" ;
VAL_ 2680225663 TFX_ControlHeadInstance 3 "All" ;
VAL_ 2680225663 TFX_SyncMode 1 "On" 0 "Off" 3 "Ignore" ;
VAL_ 2680225663 TFX_ReverseThrottleCurve 3 "Ignore" ;
VAL_ 2680225663 TFX_ForwardThrottleCurve 3 "Ignore" ;
VAL_ 2680225663 TFX_IndustryGroup 5 "IndustrialProcess" 3 "Construction" 2 "AgriculturalAndForestry" 0 "Global" 1 "OnHighway" 4 "Marine" ;
VAL_ 2680225663 TFX_Header 1850 "Teleflex" ;
VAL_ 2680225659 TFX_IndustryGroup 5 "IndustrialProcess" 3 "Construction" 2 "AgriculturalAndForestry" 0 "Global" 1 "OnHighway" 4 "Marine" ;
VAL_ 2680225659 TFX_Header 1850 "Teleflex" ;
VAL_ 2680225658 TFX_IndustryGroup 5 "IndustrialProcess" 3 "Construction" 2 "AgriculturalAndForestry" 0 "Global" 1 "OnHighway" 4 "Marine" ;
VAL_ 2680225658 TFX_Header 1850 "Teleflex" ;
VAL_ 2680225658 TFX_SidewaysNormalSensitivity 15 "Ignore" ;
VAL_ 2680225658 TFX_SidewaysBoostSensitivity 15 "Ignore" ;
VAL_ 2680225658 TFX_RotationNormalSensitivity 15 "Ignore" ;
VAL_ 2680225658 TFX_RotationBoostSensitivity 15 "Ignore" ;
VAL_ 2680225658 TFX_ReverseNormalSensitivity 15 "Ignore" ;
VAL_ 2680225658 TFX_ReverseBoostSensitivity 15 "Ignore" ;
VAL_ 2680225658 TFX_ForwardNormalSensitivity 15 "Ignore" ;
VAL_ 2680225658 TFX_ForwardBoostSensitivity 15 "Ignore" ;
VAL_ 2147548874 DM1_RedStopLamp 1 "On" 0 "Off" ;
VAL_ 2147548874 DM1_ProtectLamp 1 "On" 0 "Off" ;
VAL_ 2147548874 DM1_MalfunctionLamp 1 "On" 0 "Off" ;
VAL_ 2147548874 DM1_AmberWarningLamp 1 "On" 0 "Off" ;
VAL_ 2680225662 TFX_MaxSteeringAngle 65535 "Ignore" ;
VAL_ 2680225662 TFX_EngineCollisionAngle 65535 "Ignore" ;
VAL_ 2680225662 TFX_IndustryGroup 5 "IndustrialProcess" 3 "Construction" 2 "AgriculturalAndForestry" 0 "Global" 1 "OnHighway" 4 "Marine" ;
VAL_ 2680225662 TFX_Header 1850 "Teleflex" ;
VAL_ 2680225661 TFX_LowEngineThrottle 255 "Ignore" ;
VAL_ 2680225661 TFX_LowEngineRPM 65535 "Ignore" ;
VAL_ 2680225661 TFX_HighEngineThrottle 255 "Ignore" ;
VAL_ 2680225661 TFX_HighEngineRPM 65535 "Ignore" ;
VAL_ 2680225661 TFX_IndustryGroup 5 "IndustrialProcess" 3 "Construction" 2 "AgriculturalAndForestry" 0 "Global" 1 "OnHighway" 4 "Marine" ;
VAL_ 2680225661 TFX_Header 1850 "Teleflex" ;
VAL_ 2680225660 HelmHardstopType 3 "Ignore" 2 "Electronic and Physical" 1 "Physical" 0 "Electronic" ;
VAL_ 2680225660 TFX_IndustryGroup 5 "IndustrialProcess" 3 "Construction" 2 "AgriculturalAndForestry" 0 "Global" 1 "OnHighway" 4 "Marine" ;
VAL_ 2680225660 TFX_Header 1850 "Teleflex" ;
VAL_ 2680225650 TFX_ToolCmd 15 "None" 11 "Exit Purge/Move" 10 "Purge/Move Sctr Ctr" 9 "Purge/Move Pctr Ctr" 8 "Purge/Move Sctr" 7 "Purge/Move Pctr" 6 "Purge/Move Stbd" 5 "Purge/Move Port" 4 "Clear Calibration" 3 "Exit Calibration" 2 "Enter Calibration" 1 "Exit Maintenance" 0 "Enter Maintenance" ;
VAL_ 2680225650 TFX_UserStatus 21 "Not Available" 20 "Error" 3 "EOL Prog success" 2 "EOL in progress" 1 "EOL Prog Ready" 0 "No Status" ;
VAL_ 2680225650 TFX_UserCommand 7 "Acknowledge EOL Prog." 6 "Start EOL Prog." 5 "Mute button pressed" 4 "OK/Exit button pressed" 15 "Ignore" 14 "Error" 3 "Exit Limp Home Mode" 2 "Enter Limp Home Mode" 1 "Resume" 0 "No Command" ;
VAL_ 2680225650 TFX_SourceInstance 15 "Not Available" 14 "Error" ;
VAL_ 2680225650 TFX_IndustryGroup 5 "IndustrialProcess" 3 "Construction" 2 "AgriculturalAndForestry" 0 "Global" 1 "OnHighway" 4 "Marine" ;
VAL_ 2680225650 TFX_Header 1850 "Teleflex" ;
